VERSION ""

NS_ :

BS_:

BU_: TPM_HS EPS_HS IPC_HS TestTool_HS EBCM_HS BCM_HS TCM_HS ECM_HS
VAL_TABLE_ vt_BooleanValues 1 "true" 0 "false" ;

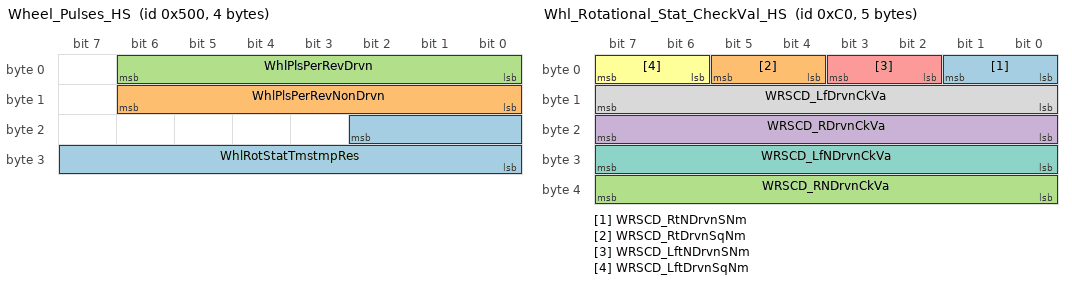
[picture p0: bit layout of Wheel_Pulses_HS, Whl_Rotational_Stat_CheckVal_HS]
BO_ 1280 Wheel_Pulses_HS: 4 EBCM_HS
 SG_ WhlRotStatTmstmpRes : 18|11@0+ (0.002,0) [0|4.094] "uSec"  EPS_HS
 SG_ WhlPlsPerRevNonDrvn : 14|7@0+ (1,0) [0|127] ""  EPS_HS
 SG_ WhlPlsPerRevDrvn : 6|7@0+ (1,0) [0|127] ""  EPS_HS

BO_ 192 Whl_Rotational_Stat_CheckVal_HS: 5 EBCM_HS
 SG_ WRSCD_RtNDrvnSNm : 1|2@0+ (1,0) [0|3] ""  EPS_HS
 SG_ WRSCD_RtDrvnSqNm : 5|2@0+ (1,0) [0|2] ""  EPS_HS
 SG_ WRSCD_RNDrvnCkVa : 39|8@0+ (1,0) [0|255] ""  EPS_HS
 SG_ WRSCD_RDrvnCkVa : 23|8@0+ (1,0) [0|255] ""  EPS_HS
 SG_ WRSCD_LftNDrvnSNm : 3|2@0+ (1,0) [0|3] ""  EPS_HS
 SG_ WRSCD_LftDrvnSqNm : 7|2@0+ (1,0) [0|3] ""  EPS_HS
 SG_ WRSCD_LfNDrvnCkVa : 31|8@0+ (1,0) [0|255] ""  EPS_HS
 SG_ WRSCD_LfDrvnCkVa : 15|8@0+ (1,0) [0|255] ""  EPS_HS

BO_ 546 Chime_Request: 1 TPM_HS
 SG_ ChmNum : 6|3@0- (1,0) [0|1] ""  BCM_HS
 SG_ ChmReq : 7|1@0+ (1,0) [0|1] ""  BCM_HS

BO_ 494 Tire_Pressure_Sensor_Prog_Res_HS: 1 TPM_HS
 SG_ TPMTrLrnMdCmplt : 1|2@0+ (1,0) [0|0] ""  IPC_HS

BO_ 591 USDT_Req_to_TPM_HS: 8 TestTool_HS
 SG_ DgnInf : 7|64@0+ (1,0) [0|1.844674407371E+019] ""  TPM_HS

BO_ 1615 USDT_Resp_From_TPM_HS: 8 TPM_HS
 SG_ DgnInf : 7|64@0+ (1,0) [0|1.8446744074E+019] ""  TestTool_HS

BO_ 1359 UUDT_Resp_From_TPM_HS: 8 TPM_HS
 SG_ DgnInf_HS54F : 7|64@0+ (1,0) [0|1.8446744074E+019] ""  TestTool_HS

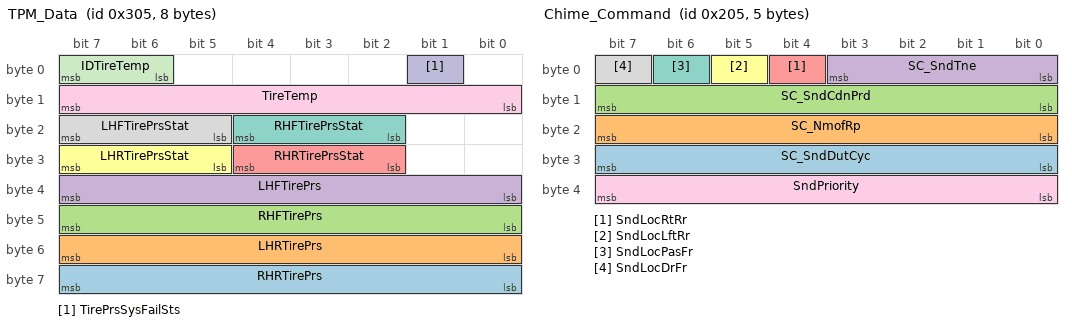
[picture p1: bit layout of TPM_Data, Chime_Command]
BO_ 773 TPM_Data: 8 TPM_HS
 SG_ RHRTirePrs : 63|8@0+ (0.0138,0) [0|3.5] "bar"  IPC_HS
 SG_ LHRTirePrs : 55|8@0+ (0.0138,0) [0|3.5] "bar"  IPC_HS
 SG_ RHFTirePrs : 47|8@0+ (0.0138,0) [0|3.5] "bar"  IPC_HS
 SG_ LHFTirePrs : 39|8@0+ (0.0138,0) [0|3.5] "bar" Vector__XXX
 SG_ RHRTirePrsStat : 28|3@0+ (1,0) [0|0] ""  IPC_HS
 SG_ LHRTirePrsStat : 31|3@0+ (1,0) [0|0] ""  IPC_HS
 SG_ RHFTirePrsStat : 20|3@0+ (1,0) [0|0] ""  IPC_HS
 SG_ LHFTirePrsStat : 23|3@0+ (1,0) [0|0] ""  IPC_HS
 SG_ TireTemp : 15|8@0+ (0.65,-40) [-40|125] "deg C"  IPC_HS
 SG_ TirePrsSysFailSts : 1|1@0+ (1,0) [0|0] ""  IPC_HS
 SG_ IDTireTemp : 7|2@0+ (1,0) [0|0] ""  IPC_HS

BO_ 1284 TPM_ID_Study_ACK: 1 TPM_HS
 SG_ IDStudyACK : 7|1@0+ (1,0) [0|1] ""  IPC_HS

BO_ 1283 TPM_ID_Study_Request: 1 IPC_HS
 SG_ IDStudyReq : 7|1@0+ (1,0) [0|1] ""  TPM_HS

BO_ 519 IPC_Chime_Request: 8 IPC_HS
 SG_ DrvSelOvSpdWarnActConf : 1|1@0+ (1,0) [0|1] ""  BCM_HS
 SG_ OvSpdChmReq : 0|1@0+ (1,0) [0|1] ""  BCM_HS

BO_ 533 IPC_General_Status_1: 1 IPC_HS
 SG_ DrvSelOvSpdEnbl : 1|1@0+ (1,0) [0|1] ""  BCM_HS
 SG_ OvSpdSta : 0|1@0+ (1,0) [0|1] ""  BCM_HS

BO_ 328 Power_Steering_Information_HS: 1 EPS_HS
 SG_ StrngAsstRdcdIO : 1|1@0- (1,0) [0|1] ""  IPC_HS
 SG_ PwrStrIO : 0|1@0+ (1,0) [0|1] ""  IPC_HS

BO_ 1346 UUDT_Resp_From_EPS_HS: 8 EPS_HS
 SG_ DgnInf : 7|64@0+ (1,0) [0|1.8446744074E+019] ""  TestTool_HS

BO_ 1602 USDT_Resp_From_EPS_HS: 8 EPS_HS
 SG_ DgnInf : 7|64@0+ (1,0) [0|1.8446744074E+019] ""  TestTool_HS

BO_ 578 USDT_Req_From_EPS_HS: 8 TestTool_HS
 SG_ DgnInf : 7|64@0+ (1,0) [0|1.8446744074E+019] ""  EPS_HS

BO_ 528 Chime_Active: 1 IPC_HS
 SG_ ChmVolSt : 2|2@0+ (1,0) [0|0] ""  BCM_HS
 SG_ ChmAct : 0|1@0+ (1,0) [0|1] ""  BCM_HS

BO_ 517 Chime_Command: 5 BCM_HS
 SG_ SC_SndDutCyc : 31|8@0+ (0.392157,0) [0|100.000035] "%"  IPC_HS
 SG_ SC_NmofRp : 23|8@0+ (1,0) [0|255] "reps"  IPC_HS
 SG_ SC_SndCdnPrd : 15|8@0+ (1,0) [0|2550] "ms"  IPC_HS
 SG_ SC_SndTne : 3|4@0+ (1,0) [0|15] ""  IPC_HS
 SG_ SndLocRtRr : 4|1@0+ (1,0) [0|1] ""  IPC_HS
 SG_ SndLocLftRr : 5|1@0+ (1,0) [0|1] ""  IPC_HS
 SG_ SndLocPasFr : 6|1@0+ (1,0) [0|1] ""  IPC_HS
 SG_ SndLocDrFr : 7|1@0+ (1,0) [0|1] ""  IPC_HS
 SG_ SndPriority : 39|8@0+ (1,0) [0|255] ""  IPC_HS

BO_ 1612 USDT_Resp_From_IPC_HS: 8 IPC_HS
 SG_ DgnInf : 7|64@0+ (1,0) [0|1.8446744074E+019] ""  TestTool_HS

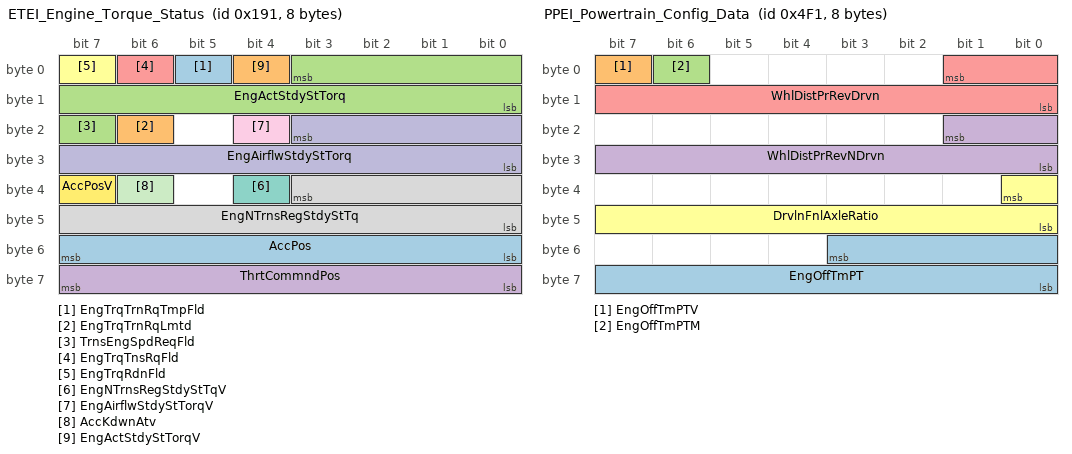
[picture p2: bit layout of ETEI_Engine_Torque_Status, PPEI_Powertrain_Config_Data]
BO_ 401 ETEI_Engine_Torque_Status: 8 ECM_HS
 SG_ EngTrqTrnRqTmpFld : 5|1@0+ (1,0) [0|1] ""  TCM_HS
 SG_ EngTrqTrnRqLmtd : 22|1@0+ (1,0) [0|1] ""  TCM_HS
 SG_ TrnsEngSpdReqFld : 23|1@0+ (1,0) [0|1] ""  TCM_HS
 SG_ ThrtCommndPos : 63|8@0+ (0.392157,0) [0|100.000035] "%"  TCM_HS
 SG_ EngTrqTnsRqFld : 6|1@0+ (1,0) [0|1] ""  TCM_HS
 SG_ EngTrqRdnFld : 7|1@0+ (1,0) [0|1] ""  TCM_HS
 SG_ EngNTrnsRegStdyStTqV : 36|1@0+ (1,0) [0|1] ""  TCM_HS
 SG_ EngNTrnsRegStdyStTq : 35|12@0+ (0.5,-848) [-848|1199.5] "Nm"  TCM_HS
 SG_ EngAirflwStdyStTorqV : 20|1@0+ (1,0) [0|1] ""  TCM_HS
 SG_ EngAirflwStdyStTorq : 19|12@0+ (0.5,-848) [-848|1199.5] "Nm"  TCM_HS
 SG_ AccKdwnAtv : 38|1@0+ (1,0) [0|1] ""  TCM_HS
 SG_ AccPosV : 39|1@0+ (1,0) [0|1] ""  TCM_HS
 SG_ AccPos : 55|8@0+ (0.392157,0) [0|100.000035] "%"  TCM_HS
 SG_ EngActStdyStTorqV : 4|1@0+ (1,0) [0|1] ""  TCM_HS
 SG_ EngActStdyStTorq : 3|12@0+ (0.5,-848) [-848|1199.5] "Nm"  TCM_HS

BO_ 1265 PPEI_Powertrain_Config_Data: 8 ECM_HS
 SG_ EngOffTmPT : 51|12@0+ (0.5,0) [0|2047.5] "min"  TCM_HS
 SG_ EngOffTmPTV : 7|1@0+ (1,0) [0|1] ""  TCM_HS
 SG_ EngOffTmPTM : 6|1@0+ (1,0) [0|1] ""  TCM_HS
 SG_ WhlDistPrRevNDrvn : 17|10@0+ (3,800) [800|3869] "mm"  EPS_HS,EBCM_HS
 SG_ WhlDistPrRevDrvn : 1|10@0+ (3,800) [800|3869] "mm"  EPS_HS,EBCM_HS,BCM_HS
 SG_ DrvlnFnlAxleRatio : 32|9@0+ (0.01,2) [2|7.11] ""  BCM_HS,EBCM_HS

BO_ 417 ETEI_Engine_General_Status: 7 ECM_HS
 SG_ EngRunng : 30|1@0+ (1,0) [0|1] "" Vector__XXX
 SG_ EngCrsCntrlMode : 29|3@0+ (1,0) [0|7] ""  TCM_HS
 SG_ EngPstOxgSnsDgAstRq : 31|1@0+ (1,0) [0|1] ""  TCM_HS
 SG_ CrsCtrlCnstSpdAct : 26|1@0+ (1,0) [0|1] ""  TCM_HS
 SG_ WrmUpShftPtrnRq : 25|1@0+ (1,0) [0|1] ""  TCM_HS
 SG_ EngIdlSpdRdcdRng : 39|8@0+ (8,0) [0|2040] "rpm"  TCM_HS
 SG_ EngCntrlRunCrnkTrmSt : 16|1@0+ (1,0) [0|1] ""  EBCM_HS,TCM_HS
 SG_ EngAlwCltAdp : 24|1@0+ (1,0) [0|1] ""  TCM_HS
 SG_ BsTrgtEngIdlSpd : 47|8@0+ (8,0) [0|2040] "rpm"  TCM_HS
 SG_ AccPdlPosPcntFullRngV : 17|1@0+ (1,0) [0|1] ""  TCM_HS
 SG_ AccPdlPosPcntFullRng : 55|8@0+ (0.392157,0) [0|100.000035] "%"  TCM_HS
 SG_ DslPrtFltrIdlRgtnMdReq : 20|1@0+ (1,0) [0|1] ""  TCM_HS
 SG_ DslPartFltrClngAlgActM : 18|1@0+ (1,0) [0|1] ""  TCM_HS
 SG_ DslPartFltrClngAlgAct : 19|1@0+ (1,0) [0|1] ""  TCM_HS
 SG_ EngCylDeactMd : 9|2@0+ (1,0) [0|3] "" Vector__XXX
 SG_ ACCmCltEngd : 13|1@0+ (1,0) [0|1] ""  TCM_HS
 SG_ ParkNeutralSwStatV : 21|1@0+ (1,0) [0|1] ""  TCM_HS
 SG_ ParkNeutralSwStat : 22|1@0+ (1,0) [0|1] ""  TCM_HS
 SG_ EngColdHiIdleActive : 23|1@0+ (1,0) [0|1] ""  TCM_HS
 SG_ EngCyDactTqSmtAct : 6|1@0+ (1,0) [0|1] ""  TCM_HS
 SG_ EngBrkStat : 15|2@0+ (1,0) [0|3] ""  TCM_HS
 SG_ TracCntlSysPwrtrnInhbt : 12|1@0+ (1,0) [0|1] ""  TCM_HS
 SG_ EngMtlProtAtv : 11|1@0+ (1,0) [0|1] ""  TCM_HS
 SG_ EngDgTrqCnvClUnlkRqd : 7|1@0+ (1,0) [0|1] ""  TCM_HS
 SG_ EngCyldrDeactReqd : 10|1@0+ (1,0) [0|1] ""  TCM_HS
 SG_ ETGRReqdGear : 3|4@0+ (1,0) [0|15] ""  TCM_HS
 SG_ ETGRReqType : 5|2@0+ (1,0) [0|3] ""  TCM_HS

BO_ 1233 PPEI_Engine_General_Status_5: 8 ECM_HS
 SG_ EngShtdwnAct : 48|1@0+ (1,0) [0|1] "" Vector__XXX
 SG_ EngShtdwnPndgIO : 49|1@0+ (1,0) [0|1] ""  BCM_HS
 SG_ FuelFltChgNwIO : 51|1@0+ (1,0) [0|1] ""  BCM_HS
 SG_ PTExPrtclFltrWrn2IO : 50|1@0+ (1,0) [0|1] ""  BCM_HS
 SG_ PTHiElecLdReqd : 52|1@0+ (1,0) [0|1] ""  BCM_HS
 SG_ PTExPrtclFltrWrnIO : 53|1@0+ (1,0) [0|1] ""  BCM_HS
 SG_ AirCndOffIO : 0|1@0+ (1,0) [0|1] ""  IPC_HS,BCM_HS
 SG_ EngSpdMaxLmt : 63|8@0+ (32,0) [0|8160] "rpm"  BCM_HS
 SG_ DslGlwPlgIO : 55|1@0+ (1,0) [0|1] ""  BCM_HS
 SG_ StgDisIO : 30|1@0+ (1,0) [0|1] ""  IPC_HS,BCM_HS
 SG_ RdcdPwrIO : 31|1@0+ (1,0) [0|1] ""  IPC_HS,BCM_HS
 SG_ FuelTotCap : 27|12@0+ (0.125,0) [0|511.875] "liters"  IPC_HS,BCM_HS
 SG_ FlLvlPctV : 28|1@0+ (1,0) [0|1] ""  IPC_HS,BCM_HS
 SG_ FlLvlPct : 47|8@0+ (0.392157,0) [0|100.000035] "%"  IPC_HS,BCM_HS
 SG_ EngWtrInFlIO : 54|1@0+ (1,0) [0|1] ""  BCM_HS
 SG_ EngOilTmpV : 7|1@0+ (1,0) [0|1] ""  IPC_HS,BCM_HS
 SG_ EngOilTmp : 15|8@0+ (1,-40) [-40|215] "deg C"  IPC_HS,BCM_HS
 SG_ EngOilPrsV : 6|1@0+ (1,0) [0|1] ""  IPC_HS,BCM_HS
 SG_ EngOilPrsLwIO : 5|1@0+ (1,0) [0|1] ""  IPC_HS,BCM_HS
 SG_ EngOilPrs : 23|8@0+ (4,0) [0|1020] "kPa"  IPC_HS,BCM_HS
 SG_ EngOilLvlLwIO : 4|1@0+ (1,0) [0|1] ""  IPC_HS,BCM_HS
 SG_ EngOilChngIO : 3|1@0+ (1,0) [0|1] ""  IPC_HS,BCM_HS
 SG_ EngHt_StpEngIO : 1|1@0+ (1,0) [0|1] ""  IPC_HS,BCM_HS
 SG_ EngHotFuelEnrchmntIO : 2|1@0+ (1,0) [0|1] ""  IPC_HS,BCM_HS
 SG_ CkFlFilrCapIO : 29|1@0+ (1,0) [0|1] ""  BCM_HS

BO_ 1217 PPEI_Engine_General_Status_4: 8 ECM_HS
 SG_ LegPstDTCClrDrvCyCm : 40|1@0+ (1,0) [0|1] ""  TCM_HS
 SG_ LegDiagColdStCndMet : 47|1@0+ (1,0) [0|1] ""  TCM_HS
 SG_ LegDiagColdStCndFltPr : 46|1@0+ (1,0) [0|1] ""  TCM_HS
 SG_ EngEconMdCmnd : 44|1@0+ (1,0) [0|1] ""  TCM_HS
 SG_ EngOilHotIO : 45|1@0+ (1,0) [0|1] ""  BCM_HS
 SG_ DslExhFldWrngIndRq : 53|3@0+ (1,0) [0|7] ""  BCM_HS
 SG_ DslExhFldRmngDstV : 50|1@0+ (1,0) [0|1] ""  BCM_HS
 SG_ DslExhFldRmngDst : 49|10@0+ (100,0) [0|102300] "km"  BCM_HS
 SG_ OAT_PT_EstV : 3|1@0+ (1,0) [0|1] ""  BCM_HS
 SG_ LegDiagStndCndMet : 2|1@0+ (1,0) [0|1] ""  TCM_HS
 SG_ LegDiagStndCndFltPr : 1|1@0+ (1,0) [0|1] ""  TCM_HS
 SG_ OAT_PT_EstM : 4|1@0+ (1,0) [0|1] ""  BCM_HS
 SG_ OAT_PT_Est : 39|8@0+ (0.5,-40) [-40|87.5] "deg C"  BCM_HS
 SG_ EngWrmUpAch : 0|1@0+ (1,0) [0|1] ""  TCM_HS
 SG_ EngIntAirTmpV : 5|1@0+ (1,0) [0|1] ""  BCM_HS
 SG_ EngIntAirTmp : 31|8@0+ (1,-40) [-40|215] "deg C"  BCM_HS
 SG_ EngCltTmpV : 6|1@0+ (1,0) [0|1] ""  IPC_HS,BCM_HS
 SG_ EngCltTmp : 23|8@0+ (1,-40) [-40|215] "deg C"  IPC_HS,BCM_HS
 SG_ BarPrsAbsV : 7|1@0+ (1,0) [0|1] ""  BCM_HS
 SG_ BarPrsAbs : 15|8@0+ (0.5,0) [0|127.5] "kPa"  BCM_HS

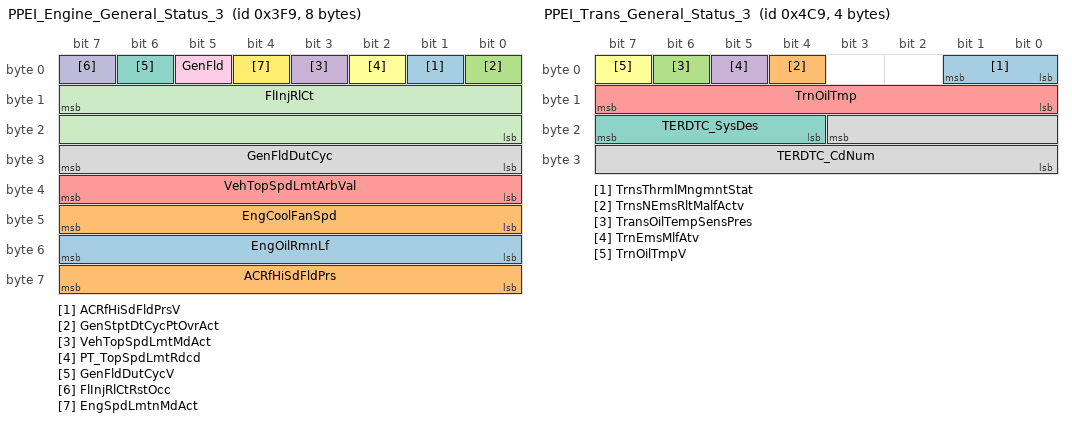
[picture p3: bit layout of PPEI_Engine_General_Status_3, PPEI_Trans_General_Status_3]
BO_ 1017 PPEI_Engine_General_Status_3: 8 ECM_HS
 SG_ ACRfHiSdFldPrsV : 1|1@0+ (1,0) [0|1] ""  BCM_HS
 SG_ ACRfHiSdFldPrs : 63|8@0+ (14,0) [0|3570] "kPaG"  BCM_HS
 SG_ GenStptDtCycPtOvrAct : 0|1@0+ (1,0) [0|1] ""  BCM_HS
 SG_ VehTopSpdLmtMdAct : 3|1@0+ (1,0) [0|1] ""  BCM_HS
 SG_ VehTopSpdLmtArbVal : 39|8@0+ (2,0) [0|510] "km / h"  BCM_HS
 SG_ PT_TopSpdLmtRdcd : 2|1@0+ (1,0) [0|1] ""  BCM_HS
 SG_ GenFldDutCycV : 6|1@0+ (1,0) [0|1] ""  BCM_HS
 SG_ GenFldDutCyc : 31|8@0+ (0.392157,0) [0|100.000035] "%"  BCM_HS
 SG_ GenFld : 5|1@0+ (1,0) [0|1] ""  IPC_HS,BCM_HS
 SG_ FlInjRlCtRstOcc : 7|1@0+ (1,0) [0|1] ""  BCM_HS
 SG_ FlInjRlCt : 15|16@0+ (3.05176E-005,0) [0|1.999970916] "liters"  BCM_HS
 SG_ EngSpdLmtnMdAct : 4|1@0+ (1,0) [0|1] ""  BCM_HS
 SG_ EngOilRmnLf : 55|8@0+ (0.392157,0) [0|100.000035] "%"  BCM_HS
 SG_ EngCoolFanSpd : 47|8@0+ (0.392157,0) [0|100.000035] "%"  BCM_HS

BO_ 977 PPEI_Engine_General_Status_2: 8 ECM_HS
 SG_ FuelFltLifRstPerf : 38|1@0+ (1,0) [0|1] ""  BCM_HS
 SG_ CrsCntlDrSelSpdAct : 39|1@0+ (1,0) [0|1] ""  BCM_HS
 SG_ ACCmpNrmLdGrdAld : 63|8@0+ (0.1,0) [0|25.5] "dm3/m/s"  BCM_HS
 SG_ ACCompCmnd : 37|1@0+ (1,0) [0|1] ""  BCM_HS
 SG_ EngBstPrsIndV : 23|1@0+ (1,0) [0|1] ""  BCM_HS
 SG_ EngBstPrsInd : 55|8@0+ (0.392157,0) [0|100.000035] "%"  BCM_HS
 SG_ EngOilLifRstPerf : 36|1@0+ (1,0) [0|1] ""  IPC_HS,BCM_HS
 SG_ ThrtlPrgrsnStat : 6|2@0+ (1,0) [0|3] ""  BCM_HS
 SG_ ThrPosV : 7|1@0+ (1,0) [0|1] ""  BCM_HS
 SG_ ThrPos : 15|8@0+ (0.392157,0) [0|100.000035] "%"  BCM_HS
 SG_ InstFuelConsmpRate : 35|12@0+ (0.025,0) [0|102.375] "ltrs/hr"  BCM_HS
 SG_ EngOilStrvtnIO : 21|1@0+ (1,0) [0|1] ""  BCM_HS
 SG_ EngNEmsnsRelMalfAct : 3|1@0+ (1,0) [0|1] ""  BCM_HS
 SG_ EngEmsRelMalfIndReq : 2|3@0+ (1,0) [0|7] ""  BCM_HS
 SG_ EngEmsMlfAtv : 4|1@0+ (1,0) [0|1] ""  BCM_HS
 SG_ EngCstFlCutAct : 22|1@0+ (1,0) [0|1] ""  BCM_HS
 SG_ AppBrkBfrCrsIO : 20|1@0+ (1,0) [0|1] ""  BCM_HS
 SG_ CrsSpdLmtrDrvSelSpd : 19|12@0+ (0.0625,0) [0|255.9375] "km / h"  TCM_HS,BCM_HS

BO_ 201 PPEI_Engine_General_Status_1: 8 ECM_HS
 SG_ EngAirIntBstPrV : 51|1@0+ (1,0) [0|1] ""  BCM_HS
 SG_ EngAirIntBstPr : 63|8@0- (1,0) [-128|127] "kPaG"  BCM_HS
 SG_ SpdLmtrSpdWrngEnbld : 47|1@0+ (1,0) [0|1] ""  BCM_HS
 SG_ SpdLmtrSpdWrngAct : 46|1@0+ (1,0) [0|1] ""  BCM_HS
 SG_ EngCylDactEvntPndg : 54|1@0+ (1,0) [0|1] "" Vector__XXX
 SG_ EngCylDeactMd : 43|2@0+ (1,0) [0|3] ""  BCM_HS
 SG_ RmVhStrtEngRng : 55|1@0+ (1,0) [0|1] ""  BCM_HS
 SG_ PFEngSpdCmndSpcd : 45|1@0+ (1,0) [0|1] ""  BCM_HS
 SG_ DrThrtlOvrrdDetProtVal : 25|2@0+ (1,0) [0|3] ""  EBCM_HS
 SG_ DrThrtlOvrdDetAlvRlCnt : 27|2@0+ (1,0) [0|3] ""  EBCM_HS
 SG_ PltfrmEngSpdCmdInhtRq : 44|1@0+ (1,0) [0|1] ""  BCM_HS
 SG_ PT_BrkPedDscrtInpStatV : 41|1@0+ (1,0) [0|1] ""  EBCM_HS
 SG_ PT_BrkPedDscrtInpStat : 40|1@0+ (1,0) [0|1] ""  EBCM_HS
 SG_ AccActPos : 39|8@0+ (0.392157,0) [0|100.000035] "%"  EBCM_HS,BCM_HS,TCM_HS
 SG_ CrsCntEnbld : 29|1@0+ (1,0) [0|1] ""  BCM_HS
 SG_ CrsCntAtv : 30|1@0+ (1,0) [0|1] ""  IPC_HS,EBCM_HS,BCM_HS,TCM_HS
 SG_ DrvThrottlOvrrdDet : 28|1@0+ (1,0) [0|1] ""  EBCM_HS,BCM_HS
 SG_ PT_CrnkAct : 6|1@0+ (1,0) [0|1] "" Vector__XXX
 SG_ PTRunAbrt : 4|1@0+ (1,0) [0|1] ""  BCM_HS
 SG_ PTO_PT_RunAbrtd : 3|1@0+ (1,0) [0|1] ""  BCM_HS
 SG_ PTCrnkAbrted : 5|1@0+ (1,0) [0|1] ""  BCM_HS
 SG_ EngSpdStat : 1|2@0+ (1,0) [0|3] ""  IPC_HS,EBCM_HS,BCM_HS
 SG_ EngSpd : 15|16@0+ (0.25,0) [0|16383.75] "rpm"  IPC_HS,EBCM_HS,BCM_HS
 SG_ EngRunAtv : 7|1@0+ (1,0) [0|1] ""  EPS_HS,IPC_HS,EBCM_HS,BCM_HS
 SG_ EngIdlAtv : 2|1@0+ (1,0) [0|1] ""  IPC_HS,BCM_HS
 SG_ AccActPosV : 31|1@0+ (1,0) [0|1] ""  EBCM_HS,BCM_HS,TCM_HS

BO_ 501 PPEI_Trans_General_Status_2: 8 ECM_HS
 SG_ EngRecDwnshftIO : 54|1@0+ (1,0) [0|1] ""  BCM_HS
 SG_ TrnsPattSelEcnMdOCm : 52|1@0+ (1,0) [0|1] ""  ECM_HS
 SG_ TransShftDlyd : 45|1@0+ (1,0) [0|1] ""  BCM_HS
 SG_ CltStartSwAtvV : 38|1@0+ (1,0) [0|0] ""  BCM_HS
 SG_ CltStartSwAtv : 37|1@0+ (1,0) [0|1] ""  BCM_HS
 SG_ CltchPdlActPosV : 55|1@0+ (1,0) [0|1] ""  ECM_HS
 SG_ CltchPdlActPos : 63|8@0+ (0.392157,0) [0|100.000035] "%"  ECM_HS
 SG_ TrnsEngdStateV : 50|1@0+ (1,0) [0|1] ""  IPC_HS,BCM_HS
 SG_ TrnsEngdState : 49|2@0+ (1,0) [0|3] ""  IPC_HS,BCM_HS
 SG_ TransTUDMdStat : 41|2@0+ (1,0) [0|3] ""  IPC_HS,BCM_HS,ECM_HS
 SG_ TrnCrpMdAtv : 46|1@0+ (1,0) [0|1] ""  ECM_HS,BCM_HS
 SG_ TrnsShftLvrLckRqd : 47|1@0+ (1,0) [0|1] "" Vector__XXX
 SG_ TrnsSkpShftIO : 23|1@0+ (1,0) [0|1] ""  BCM_HS
 SG_ TrnsSftMdStat : 34|3@0+ (1,0) [0|7] ""  BCM_HS
 SG_ TrnsRngInhbtStat : 31|3@0+ (1,0) [0|7] ""  BCM_HS
 SG_ TopTrvlCltchSwActV : 15|1@0+ (1,0) [0|1] ""  BCM_HS
 SG_ TopTrvlCltchSwAct : 14|1@0+ (1,0) [0|1] ""  BCM_HS
 SG_ OvrdrvDsblReqGrntd : 39|1@0+ (1,0) [0|1] ""  BCM_HS
 SG_ EngRecmndUpshftIO : 22|1@0+ (1,0) [0|1] ""  BCM_HS
 SG_ DrvtShftCntrlTrgtGear : 19|4@0+ (1,0) [0|15] ""  IPC_HS,BCM_HS
 SG_ DrShftCntrlReqDndIO : 21|1@0+ (1,0) [0|1] ""  IPC_HS,BCM_HS
 SG_ TrnShftPtrnActStat : 44|3@0+ (1,0) [0|7] ""  EPS_HS,IPC_HS,BCM_HS
 SG_ TrnsFldPrsPrsnt : 51|1@0+ (1,0) [0|1] ""  ECM_HS
 SG_ TrnsShftLvrPos : 27|4@0+ (1,0) [0|15] ""  IPC_HS,BCM_HS,ECM_HS
 SG_ TrnsShftLvrPosV : 28|1@0+ (1,0) [0|1] ""  IPC_HS,BCM_HS,ECM_HS
 SG_ TrnsTrqCnvCltCmndMd : 7|3@0+ (1,0) [0|7] ""  ECM_HS
 SG_ AutoTransComndGear : 11|4@0+ (1,0) [0|15] ""  BCM_HS,ECM_HS
 SG_ AutoTransGrSftDirect : 13|2@0+ (1,0) [0|3] ""  ECM_HS
 SG_ TransEstGear : 3|4@0+ (1,0) [0|15] ""  IPC_HS,EPS_HS,BCM_HS,ECM_HS
 SG_ TransEstGearV : 4|1@0+ (1,0) [0|1] ""  IPC_HS,EPS_HS,BCM_HS,ECM_HS

BO_ 1225 PPEI_Trans_General_Status_3: 4 ECM_HS
 SG_ TrnsThrmlMngmntStat : 1|2@0+ (1,0) [0|3] ""  BCM_HS
 SG_ TrnsNEmsRltMalfActv : 4|1@0+ (1,0) [0|1] ""  BCM_HS
 SG_ TransOilTempSensPres : 6|1@0+ (1,0) [0|1] ""  BCM_HS
 SG_ TrnEmsMlfAtv : 5|1@0+ (1,0) [0|1] ""  BCM_HS,ECM_HS
 SG_ TrnOilTmp : 15|8@0+ (1,-40) [-40|215] "deg C"  BCM_HS,ECM_HS
 SG_ TrnOilTmpV : 7|1@0+ (1,0) [0|1] ""  BCM_HS,ECM_HS
 SG_ TERDTC_SysDes : 23|4@0+ (1,0) [0|15] ""  ECM_HS
 SG_ TERDTC_CdNum : 19|12@0+ (1,0) [0|4095] ""  ECM_HS

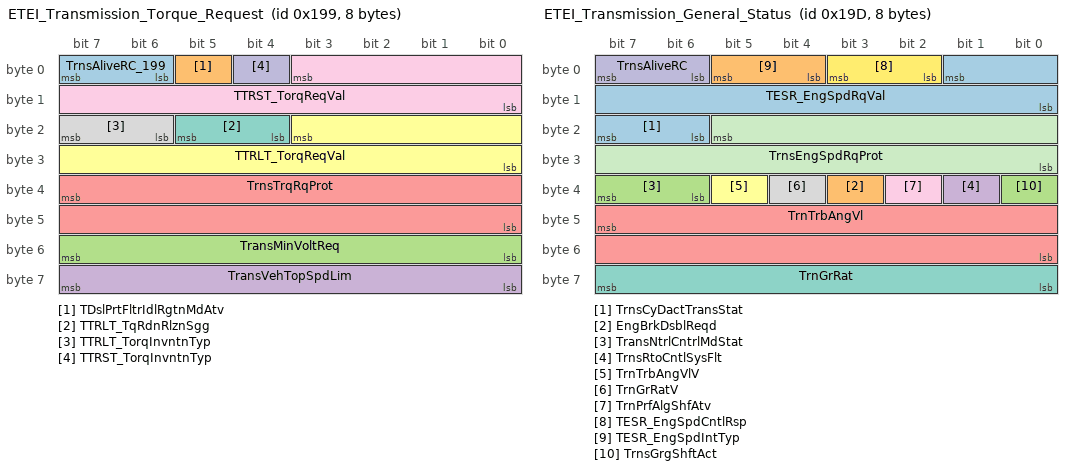
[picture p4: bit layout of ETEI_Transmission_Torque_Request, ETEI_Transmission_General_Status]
BO_ 409 ETEI_Transmission_Torque_Request: 8 TCM_HS
 SG_ TrnsAliveRC_199 : 7|2@0+ (1,0) [0|3] ""  ECM_HS
 SG_ TDslPrtFltrIdlRgtnMdAtv : 5|1@0+ (1,0) [0|1] ""  ECM_HS
 SG_ TransMinVoltReq : 55|8@0+ (0.07843,0) [0|19.99965] "volts"  ECM_HS
 SG_ TransVehTopSpdLim : 63|8@0+ (2,0) [0|510] "km / h"  ECM_HS
 SG_ TrnsTrqRqProt : 39|16@0+ (1,0) [0|65535] ""  ECM_HS
 SG_ TTRLT_TorqReqVal : 19|12@0+ (0.5,-848) [-848|1199.5] "Nm"  ECM_HS
 SG_ TTRLT_TqRdnRlznSgg : 21|2@0+ (1,0) [0|3] ""  ECM_HS
 SG_ TTRLT_TorqInvntnTyp : 23|2@0+ (1,0) [0|3] ""  ECM_HS
 SG_ TTRST_TorqReqVal : 3|12@0+ (0.5,-848) [-848|1199.5] "Nm"  ECM_HS
 SG_ TTRST_TorqInvntnTyp : 4|1@0+ (1,0) [0|1] ""  ECM_HS

BO_ 413 ETEI_Transmission_General_Status: 8 TCM_HS
 SG_ TrnsCyDactTransStat : 23|2@0+ (1,0) [0|3] ""  ECM_HS
 SG_ EngBrkDsblReqd : 35|1@0+ (1,0) [0|1] ""  ECM_HS
 SG_ TransNtrlCntrlMdStat : 39|2@0+ (1,0) [0|3] ""  BCM_HS,ECM_HS
 SG_ TrnsRtoCntlSysFlt : 33|1@0+ (1,0) [0|1] ""  ECM_HS
 SG_ TrnTrbAngVl : 47|16@0+ (0.25,0) [0|16383.75] "rpm"  ECM_HS
 SG_ TrnTrbAngVlV : 37|1@0+ (1,0) [0|1] ""  ECM_HS
 SG_ TrnGrRat : 63|8@0+ (0.03125,0) [0|7.96875] ""  ECM_HS
 SG_ TrnGrRatV : 36|1@0+ (1,0) [0|1] ""  ECM_HS
 SG_ TrnPrfAlgShfAtv : 34|1@0+ (1,0) [0|1] ""  ECM_HS
 SG_ TrnsAliveRC : 7|2@0+ (1,0) [0|3] ""  ECM_HS
 SG_ TrnsEngSpdRqProt : 21|14@0+ (1,0) [0|16383] ""  ECM_HS
 SG_ TESR_EngSpdCntlRsp : 3|2@0+ (1,0) [0|3] ""  ECM_HS
 SG_ TESR_EngSpdRqVal : 1|10@0+ (8,0) [0|8184] "rpm"  ECM_HS
 SG_ TESR_EngSpdIntTyp : 5|2@0+ (1,0) [0|3] ""  ECM_HS
 SG_ TrnsGrgShftAct : 32|1@0+ (1,0) [0|1] ""  ECM_HS

BO_ 257 USDT_Req_to_All_HS_ECUs: 8 TestTool_HS
 SG_ DgnInf : 7|64@0+ (1,0) [0|1.8446744074E+019] ""  TPM_HS,EPS_HS,IPC_HS,EBCM_HS,BCM_HS,TCM_HS,ECM_HS

BO_ 2016 USDT_Req_to_ECM_HS: 8 TestTool_HS
 SG_ DgnInf : 7|64@0+ (1,0) [0|1.8446744074E+019] ""  ECM_HS

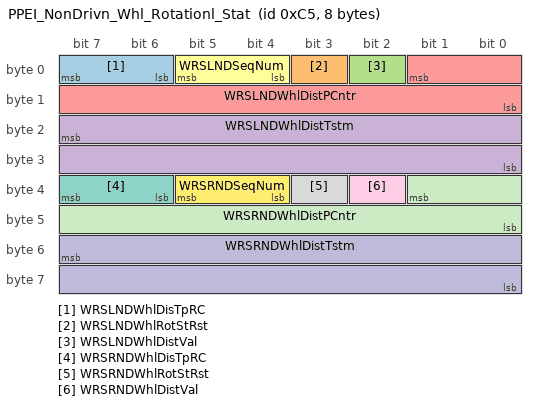
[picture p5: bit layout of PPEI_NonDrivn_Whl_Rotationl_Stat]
BO_ 197 PPEI_NonDrivn_Whl_Rotationl_Stat: 8 EBCM_HS
 SG_ WRSLNDWhlDisTpRC : 7|2@0+ (1,0) [0|3] "counts"  EPS_HS,BCM_HS,TCM_HS,ECM_HS
 SG_ WRSLNDWhlRotStRst : 3|1@0+ (1,0) [0|1] ""  EPS_HS,BCM_HS,TCM_HS,ECM_HS
 SG_ WRSLNDWhlDistVal : 2|1@0+ (1,0) [0|1] ""  EPS_HS,BCM_HS,TCM_HS,ECM_HS
 SG_ WRSLNDWhlDistTstm : 23|16@0+ (1,0) [0|65535] "counts"  EPS_HS,BCM_HS,TCM_HS,ECM_HS
 SG_ WRSLNDWhlDistPCntr : 1|10@0+ (1,0) [0|1023] "counts"  EPS_HS,BCM_HS,TCM_HS,ECM_HS
 SG_ WRSLNDSeqNum : 5|2@0+ (1,0) [0|3] "counts"  EPS_HS,BCM_HS,TCM_HS,ECM_HS
 SG_ WRSRNDWhlDisTpRC : 39|2@0+ (1,0) [0|3] "counts"  EPS_HS,BCM_HS,TCM_HS,ECM_HS
 SG_ WRSRNDWhlRotStRst : 35|1@0+ (1,0) [0|1] ""  EPS_HS,BCM_HS,TCM_HS,ECM_HS
 SG_ WRSRNDWhlDistVal : 34|1@0+ (1,0) [0|1] ""  EPS_HS,BCM_HS,TCM_HS,ECM_HS
 SG_ WRSRNDWhlDistTstm : 55|16@0+ (1,0) [0|65535] "counts"  EPS_HS,BCM_HS,TCM_HS,ECM_HS
 SG_ WRSRNDWhlDistPCntr : 33|10@0+ (1,0) [0|1023] "counts"  EPS_HS,BCM_HS,TCM_HS,ECM_HS
 SG_ WRSRNDSeqNum : 37|2@0+ (1,0) [0|3] "counts"  EPS_HS,BCM_HS,TCM_HS,ECM_HS

BO_TX_BU_ 501 : TCM_HS,ECM_HS;
BO_TX_BU_ 1225 : TCM_HS,ECM_HS;

CM_ "Primary High Speed GMLAN";
CM_ BU_ TPM_HS "Tire Pressure Module";
CM_ BU_ EPS_HS "Electrical Power Streering";
CM_ BU_ IPC_HS "IP cluster";
CM_ BU_ EBCM_HS "Electronic Brake Control Module";
CM_ BU_ BCM_HS "HS Side Global Architecture Gateway and Body Control Module";
CM_ BU_ TCM_HS "Transmission Control Module";
CM_ BU_ ECM_HS "Engine Control Module";
CM_ BO_ 533 "Created for SGM818 LSD function";
CM_ SG_ 401 EngTrqTnsRqFld "Indicates that the Engine controller will not honor the torque request from the Transmission Controller due to a failure in the Rolling count, protection value, etc.";
CM_ SG_ 401 EngNTrnsRegStdyStTqV "ETEI 3.1";
CM_ SG_ 401 EngNTrnsRegStdyStTq "ETEI 3.1";
CM_ SG_ 401 EngAirflwStdyStTorqV "ETEI 3.1";
CM_ SG_ 401 EngAirflwStdyStTorq "ETEI 3.1";
CM_ SG_ 401 EngActStdyStTorqV "ETEI 3.1";
CM_ SG_ 401 EngActStdyStTorq "ETEI 3.1";
CM_ SG_ 417 TracCntlSysPwrtrnInhbt "ETEI 3.1";
CM_ SG_ 977 ACCmpNrmLdGrdAld "dm3/m/s = dm3/minute/second";
CM_ SG_ 977 ThrtlPrgrsnStat "ECM = Engine Control Module";
CM_ BO_ 201 "Changed for PPEI 3.6";
CM_ SG_ 201 EngRunAtv "Indication from powertrain that the engine is running (Has RPM > 0)";
CM_ SG_ 501 TrnShftPtrnActStat "(PT = Powertrain)";
BA_DEF_  "BusType" STRING ;
BA_DEF_ SG_  "VNSigSLHS_VNReq" ENUM  "No","Yes";
BA_DEF_ SG_  "VNSigSLHSSharedDiagnostic" ENUM  "No","Yes";
BA_DEF_ SG_  "SignalType" STRING ;
BA_DEF_ SG_  "PacketOrder" INT 0 65535;
BA_DEF_ SG_  "SignalLongName" STRING ;
BA_DEF_ SG_  "GenSigStartValue" INT 0 65535;
BA_DEF_ SG_  "VNSigAllNodes" ENUM  "No","Yes";
BA_DEF_ SG_  "GenSigDeltaValue" INT 0 0;
BA_DEF_ SG_  "GenSigSendType_signal" ENUM  "not used","not used","not used","not used","not used","not used","not used","NoSigSendType","not used","not used","OnAnyChange","OnChangeIfActive","OnDelta";
BA_DEF_ SG_  "GenSigSendOnInit_signal" ENUM  "Not Initialized","Application","Handler";
BA_DEF_ SG_  "GenSigSendType" ENUM  "not used","not used","not used","not used","not used","not used","not used","NoSigSendType","not used","not used","OnAnyChange","OnChangeIfActive","OnDelta";
BA_DEF_ SG_  "GenSigSendOnInit" ENUM  "Not Initialized","Application","Handler";
BA_DEF_ BO_  "GenMsgILSupport" ENUM  "No","Yes";
BA_DEF_ BO_  "TpApplType" STRING ;
BA_DEF_ BO_  "Prio" INT 0 7;
BA_DEF_ BO_  "MessageSubnet" ENUM  "LS","MS","HS","CE","PE","CC";
BA_DEF_ BO_  "DiagState" ENUM  "No","Yes";
BA_DEF_ BO_  "GenMsgDelayTime" INT 0 100000;
BA_DEF_ BO_  "GenMsgCycleTime" INT 0 100000;
BA_DEF_ BO_  "GenMsgSendType" ENUM  "cyclicX","spontanX","cyclicIfActiveX","spontanWithDelay","cyclicAndSpontanX","cyclicAndSpontanWithDelay","spontanWithRepitition","cyclicIfActiveAndSpontanWD";
BA_DEF_ BO_  "DiagResponse" ENUM  "No","Yes";
BA_DEF_ BO_  "DiagRequest" ENUM  "No","Yes";
BA_DEF_ BO_  "NmMessage" ENUM  "No","Yes";
BA_DEF_ BU_  "NmNode" ENUM  "No","Yes";
BA_DEF_ BU_  "ILUsed" ENUM  "No","Yes";
BA_DEF_ BU_  "NodeLayerModules" STRING ;
BA_DEF_ BU_  "D22_FRdDataByPID" ENUM  "No","Yes";
BA_DEF_ BU_  "D22_ReqType" ENUM  "Functional","Physical","Both";
BA_DEF_ BU_  "D2D_ReqType" ENUM  "Functional","Physical","Both";
BA_DEF_ BU_  "DAE_ReqType" ENUM  "Functional","Physical","Both";
BA_DEF_ BU_  "DAE_NE3" ENUM  "No","Yes";
BA_DEF_ BU_  "DAE_N78" ENUM  "No","Yes";
BA_DEF_ BU_  "DAE_N31" ENUM  "No","Yes";
BA_DEF_ BU_  "DAE_N12" ENUM  "No","Yes";
BA_DEF_ BU_  "DAE_FDevCtrl" ENUM  "No","Yes","vector_leerstring";
BA_DEF_ BU_  "DAA_ReqType" ENUM  "Functional","Physical","Both";
BA_DEF_ BU_  "DAA_N81" ENUM  "No","Yes";
BA_DEF_ BU_  "DAA_N78" ENUM  "No","Yes";
BA_DEF_ BU_  "DAA_N31" ENUM  "No","Yes";
BA_DEF_ BU_  "DAA_N12" ENUM  "No","Yes";
BA_DEF_ BU_  "DAA_L04_FastRate" ENUM  "No","Yes";
BA_DEF_ BU_  "DAA_L03_MedRate" ENUM  "No","Yes";
BA_DEF_ BU_  "DAA_L02_SlowRate" ENUM  "No","Yes";
BA_DEF_ BU_  "DAA_L01_SndOneRsp" ENUM  "No","Yes";
BA_DEF_ BU_  "DAA_L00_StopSnd" ENUM  "No","Yes";
BA_DEF_ BU_  "DAA_FRdDPID" ENUM  "No","Yes","vector_leerstring";
BA_DEF_ BU_  "DA9_ReqType" ENUM  "Functional","Physical","Both";
BA_DEF_ BU_  "DA9_N78" ENUM  "No","Yes";
BA_DEF_ BU_  "DA9_N31" ENUM  "No","Yes";
BA_DEF_ BU_  "DA9_N12" ENUM  "No","Yes";
BA_DEF_ BU_  "DA9_L82_SndChgDTC" ENUM  "No","Yes";
BA_DEF_ BU_  "DA9_L81_RdStatDTCbyMsk" ENUM  "No","Yes";
BA_DEF_ BU_  "DA9_L80_RdStatDTCbyNum" ENUM  "No","Yes";
BA_DEF_ BU_  "DA9_FRdDiagInfo" ENUM  "No","Yes","vector_leerstring";
BA_DEF_ BU_  "DA5_ReqType" ENUM  "Functional","Physical","Both";
BA_DEF_ BU_  "DA5_N78" ENUM  "No","Yes";
BA_DEF_ BU_  "DA5_N22" ENUM  "No","Yes";
BA_DEF_ BU_  "DA5_N12" ENUM  "No","Yes";
BA_DEF_ BU_  "DA5_L03_EnabProgMode" ENUM  "No","Yes";
BA_DEF_ BU_  "DA5_L02_ReqProgModeHS" ENUM  "No","Yes";
BA_DEF_ BU_  "DA5_L01_ReqProgMode" ENUM  "No","Yes";
BA_DEF_ BU_  "DA5_FProgMode" ENUM  "No","Yes","vector_leerstring";
BA_DEF_ BU_  "DA2_ReqType" ENUM  "Functional","Physical","Both";
BA_DEF_ BU_  "DA2_N78" ENUM  "No","Yes";
BA_DEF_ BU_  "DA2_N12" ENUM  "No","Yes";
BA_DEF_ BU_  "DA2_FRptPrgStat" ENUM  "No","Yes","vector_leerstring";
BA_DEF_ BU_  "D3E_ReqType" ENUM  "Functional","Physical","Both";
BA_DEF_ BU_  "D3E_N12" ENUM  "No","Yes";
BA_DEF_ BU_  "D3E_FTstrPres" ENUM  "No","Yes","vector_leerstring";
BA_DEF_ BU_  "D3B_ReqType" ENUM  "Functional","Physical","Both";
BA_DEF_ BU_  "D3B_N78" ENUM  "No","Yes";
BA_DEF_ BU_  "D3B_N31" ENUM  "No","Yes";
BA_DEF_ BU_  "D3B_N22" ENUM  "No","Yes";
BA_DEF_ BU_  "D3B_N12" ENUM  "No","Yes";
BA_DEF_ BU_  "D3B_FWrtBlk" ENUM  "No","Yes","vector_leerstring";
BA_DEF_ BU_  "D36_ReqType" ENUM  "Functional","Physical","Both";
BA_DEF_ BU_  "D36_N89" ENUM  "No","Yes";
BA_DEF_ BU_  "D36_N85" ENUM  "No","Yes";
BA_DEF_ BU_  "D36_N83" ENUM  "No","Yes";
BA_DEF_ BU_  "D36_N78" ENUM  "No","Yes";
BA_DEF_ BU_  "D36_N31" ENUM  "No","Yes";
BA_DEF_ BU_  "D36_N22" ENUM  "No","Yes";
BA_DEF_ BU_  "D36_N12" ENUM  "No","Yes";
BA_DEF_ BU_  "D36_L80_DwnldExec" ENUM  "No","Yes";
BA_DEF_ BU_  "D36_L00_DownLoad" ENUM  "No","Yes";
BA_DEF_ BU_  "D36_FXfrData" ENUM  "No","Yes","vector_leerstring";
BA_DEF_ BU_  "D34_ReqType" ENUM  "Functional","Physical","Both";
BA_DEF_ BU_  "D34_N99" ENUM  "No","Yes";
BA_DEF_ BU_  "D34_N78" ENUM  "No","Yes";
BA_DEF_ BU_  "D34_N22" ENUM  "No","Yes";
BA_DEF_ BU_  "D34_N12" ENUM  "No","Yes";
BA_DEF_ BU_  "D34_FReqDwnld" ENUM  "No","Yes";
BA_DEF_ BU_  "D2C_ReqType" ENUM  "Functional","Physical","Both";
BA_DEF_ BU_  "D2C_N78" ENUM  "No","Yes";
BA_DEF_ BU_  "D2C_N31" ENUM  "No","Yes";
BA_DEF_ BU_  "D2C_N12" ENUM  "No","Yes";
BA_DEF_ BU_  "D2C_FDynMsg" ENUM  "No","Yes","vector_leerstring";
BA_DEF_ BU_  "D28_ReqType" ENUM  "Functional","Physical","Both";
BA_DEF_ BU_  "D28_N22" ENUM  "No","Yes";
BA_DEF_ BU_  "D28_N12" ENUM  "No","Yes";
BA_DEF_ BU_  "D28_FDisNormComm" ENUM  "No","Yes","vector_leerstring";
BA_DEF_ BU_  "D27_ReqType" ENUM  "Functional","Physical","Both";
BA_DEF_ BU_  "D27_N78" ENUM  "No","Yes";
BA_DEF_ BU_  "D27_N37" ENUM  "No","Yes";
BA_DEF_ BU_  "D27_N36" ENUM  "No","Yes";
BA_DEF_ BU_  "D27_N35" ENUM  "No","Yes";
BA_DEF_ BU_  "D27_N22" ENUM  "No","Yes";
BA_DEF_ BU_  "D27_N12" ENUM  "No","Yes";
BA_DEF_ BU_  "D27_L02_SndKey" ENUM  "No","Yes";
BA_DEF_ BU_  "D27_L01_ReqSeed" ENUM  "No","Yes";
BA_DEF_ BU_  "D27_FSecAcc" ENUM  "No","Yes","vector_leerstring";
BA_DEF_ BU_  "D23_ReqType" ENUM  "Functional","Physical","Both";
BA_DEF_ BU_  "D23_N78" ENUM  "No","Yes";
BA_DEF_ BU_  "D23_N31" ENUM  "No","Yes";
BA_DEF_ BU_  "D23_N12" ENUM  "No","Yes";
BA_DEF_ BU_  "D23_FRdMemAddr" ENUM  "No","Yes","vector_leerstring";
BA_DEF_ BU_  "D20_ReqType" ENUM  "Functional","Physical","Both";
BA_DEF_ BU_  "D20_N12" ENUM  "No","Yes";
BA_DEF_ BU_  "D20_FRtnNormComm" ENUM  "No","Yes","vector_leerstring";
BA_DEF_ BU_  "D1A_ReqType" ENUM  "Functional","Physical","Both";
BA_DEF_ BU_  "D1A_N78" ENUM  "No","Yes";
BA_DEF_ BU_  "D1A_N31" ENUM  "No","Yes";
BA_DEF_ BU_  "D1A_N22" ENUM  "No","Yes";
BA_DEF_ BU_  "D1A_N12" ENUM  "No","Yes";
BA_DEF_ BU_  "D1A_FRdDataID" ENUM  "No","Yes","vector_leerstring";
BA_DEF_ BU_  "D12_ReqType" ENUM  "Functional","Physical","Both";
BA_DEF_ BU_  "D12_N78" ENUM  "No","Yes";
BA_DEF_ BU_  "D12_N31" ENUM  "No","Yes";
BA_DEF_ BU_  "D12_N12" ENUM  "No","Yes";
BA_DEF_ BU_  "D12_L02_RdFRcdParam" ENUM  "No","Yes";
BA_DEF_ BU_  "D12_L01_RdFRcdData" ENUM  "No","Yes";
BA_DEF_ BU_  "D12_FRdFailRec" ENUM  "No","Yes","vector_leerstring";
BA_DEF_ BU_  "D10_ReqType" ENUM  "Functional","Physical ","Both";
BA_DEF_ BU_  "D10_N78" ENUM  "No","Yes";
BA_DEF_ BU_  "D10_N22" ENUM  "No","Yes";
BA_DEF_ BU_  "D10_N12" ENUM  "No","Yes";
BA_DEF_ BU_  "D10_L04_WakeUpLinks" ENUM  "No","Yes";
BA_DEF_ BU_  "D10_L03_DTCsDurDevCtrl" ENUM  "No","Yes";
BA_DEF_ BU_  "D10_L02_DisAllDTCs" ENUM  "No","Yes";
BA_DEF_ BU_  "D10_FInitDiagOp" ENUM  "No","Yes";
BA_DEF_ BU_  "D04_ReqType" ENUM  "Functional","Physical","Both";
BA_DEF_ BU_  "D04_N78" ENUM  "No","Yes";
BA_DEF_ BU_  "D04_N22" ENUM  "No","Yes";
BA_DEF_ BU_  "D04_N12" ENUM  "No","Yes";
BA_DEF_ BU_  "D04_FClrDTC" ENUM  "No","Yes";
BA_DEF_ BU_  "NmStationAddress" INT 0 31;
BA_DEF_ BU_  "ECU_Id_Node" HEX 0 255;
BA_DEF_ BU_  "SourceId_Node" HEX 0 253;
BA_DEF_ BU_  "VNECUSLHSSharedDiagnostic" ENUM  "None","Activator","Remoted","Activator and Remoted","Shared Local";
BA_DEF_ BU_  "VNECUSLHS_VNReq" ENUM  "None","Activator","Remoted","Activator and Remoted","Shared Local";
BA_DEF_ BU_  "VNECUAllNodes" ENUM  "None","Activator","Remoted","Activator and Remoted","Shared Local";
BA_DEF_ BU_  "SourceId" HEX 0 253;
BA_DEF_ BU_  "ECU_Id" HEX 0 255;
BA_DEF_  "SyncJumpWidthMax" INT 0 255;
BA_DEF_  "SyncJumpWidthMin" INT 0 255;
BA_DEF_  "SamplePointMax" FLOAT 0 100;
BA_DEF_  "SamplePointMin" FLOAT 0 100;
BA_DEF_  "Baudrate" INT 0 1000000;
BA_DEF_  "VehicleArchitecture" STRING ;
BA_DEF_  "VNInitActSLHS_VNReq" ENUM  "No","Yes";
BA_DEF_  "VN_SLHS_VNReq" INT 0 255;
BA_DEF_  "VNInitActSLHSSharedDiagnostic" ENUM  "No","Yes";
BA_DEF_  "VN_SLHSSharedDiagnostic" INT 0 255;
BA_DEF_  "VersionNumber" FLOAT 0 65535;
BA_DEF_  "NmMessageCount" INT 0 32;
BA_DEF_  "NmBaseAddress" HEX 0 2032;
BA_DEF_  "NetworkType" STRING ;
BA_DEF_  "VNMFPeriodicInterval" INT 0 65535;
BA_DEF_  "BusWakeUpDelay" INT 0 65535;
BA_DEF_  "BusOffRecoveryTime" INT 0 65535;
BA_DEF_  "NodeStatusMsgID" HEX 0 536870911;
BA_DEF_  "NodeStatusMsgCycleTime" INT 0 65535;
BA_DEF_  "NodeStatusMsgTimeoutTime" INT 0 65535;
BA_DEF_  "UseGMParameterIDs" INT 0 1;
BA_DEF_  "VersionWeek" INT 0 255;
BA_DEF_  "VersionYear" INT 0 255;
BA_DEF_  "VN_AllNodes" INT 0 255;
BA_DEF_  "Manufacturer" ENUM  "DBAG","VAG","BMW","PAG","GM";
BA_DEF_  "NmType" STRING ;
BA_DEF_REL_ BU_SG_REL_  "GenSigSuprvRespComment" STRING ;
BA_DEF_REL_ BU_SG_REL_  "GenSigVBitResp" ENUM  "No","Yes";
BA_DEF_REL_ BU_SG_REL_  "GenSigVBitRespComment" STRING ;
BA_DEF_REL_ BU_SG_REL_  "GenSigVDAFailComment" STRING ;
BA_DEF_REL_ BU_SG_REL_  "GenSigVDAFailResp" ENUM  "No","Yes";
BA_DEF_REL_ BU_SG_REL_  "GenSigRxStartValue" STRING ;
BA_DEF_REL_ BU_SG_REL_  "GenSigSuprvRespSubValue" INT 0 65535;
BA_DEF_REL_ BU_SG_REL_  "GenSigSuprvResp" ENUM  "None","Notify App","Substitute Default";
BA_DEF_REL_ BU_SG_REL_  "GenSigTimeoutMsg" HEX -2147483648 268435455;
BA_DEF_REL_ BU_SG_REL_  "GenSigTimeoutTime" INT 0 15000;
BA_DEF_DEF_  "BusType" "";
BA_DEF_DEF_  "VNSigSLHS_VNReq" "No";
BA_DEF_DEF_  "VNSigSLHSSharedDiagnostic" "No";
BA_DEF_DEF_  "SignalType" "";
BA_DEF_DEF_  "PacketOrder" 0;
BA_DEF_DEF_  "SignalLongName" "";
BA_DEF_DEF_  "GenSigStartValue" 0;
BA_DEF_DEF_  "VNSigAllNodes" "No";
BA_DEF_DEF_  "GenSigDeltaValue" 0;
BA_DEF_DEF_  "GenSigSendType_signal" "NoSigSendType";
BA_DEF_DEF_  "GenSigSendOnInit_signal" "Not Initialized";
BA_DEF_DEF_  "GenSigSendType" "NoSigSendType";
BA_DEF_DEF_  "GenSigSendOnInit" "Not Initialized";
BA_DEF_DEF_  "GenMsgILSupport" "Yes";
BA_DEF_DEF_  "TpApplType" "";
BA_DEF_DEF_  "Prio" 4;
BA_DEF_DEF_  "MessageSubnet" "LS";
BA_DEF_DEF_  "DiagState" "No";
BA_DEF_DEF_  "GenMsgDelayTime" 0;
BA_DEF_DEF_  "GenMsgCycleTime" 0;
BA_DEF_DEF_  "GenMsgSendType" "spontanX";
BA_DEF_DEF_  "DiagResponse" "No";
BA_DEF_DEF_  "DiagRequest" "No";
BA_DEF_DEF_  "NmMessage" "No";
BA_DEF_DEF_  "NmNode" "Yes";
BA_DEF_DEF_  "ILUsed" "Yes";
BA_DEF_DEF_  "NodeLayerModules" "gmlan02.dll";
BA_DEF_DEF_  "D22_FRdDataByPID" "No";
BA_DEF_DEF_  "D22_ReqType" "Both";
BA_DEF_DEF_  "D2D_ReqType" "Both";
BA_DEF_DEF_  "DAE_ReqType" "Both";
BA_DEF_DEF_  "DAE_NE3" "No";
BA_DEF_DEF_  "DAE_N78" "No";
BA_DEF_DEF_  "DAE_N31" "No";
BA_DEF_DEF_  "DAE_N12" "No";
BA_DEF_DEF_  "DAE_FDevCtrl" "No";
BA_DEF_DEF_  "DAA_ReqType" "Both";
BA_DEF_DEF_  "DAA_N81" "No";
BA_DEF_DEF_  "DAA_N78" "No";
BA_DEF_DEF_  "DAA_N31" "No";
BA_DEF_DEF_  "DAA_N12" "No";
BA_DEF_DEF_  "DAA_L04_FastRate" "No";
BA_DEF_DEF_  "DAA_L03_MedRate" "No";
BA_DEF_DEF_  "DAA_L02_SlowRate" "No";
BA_DEF_DEF_  "DAA_L01_SndOneRsp" "No";
BA_DEF_DEF_  "DAA_L00_StopSnd" "No";
BA_DEF_DEF_  "DAA_FRdDPID" "No";
BA_DEF_DEF_  "DA9_ReqType" "Both";
BA_DEF_DEF_  "DA9_N78" "No";
BA_DEF_DEF_  "DA9_N31" "No";
BA_DEF_DEF_  "DA9_N12" "No";
BA_DEF_DEF_  "DA9_L82_SndChgDTC" "No";
BA_DEF_DEF_  "DA9_L81_RdStatDTCbyMsk" "No";
BA_DEF_DEF_  "DA9_L80_RdStatDTCbyNum" "No";
BA_DEF_DEF_  "DA9_FRdDiagInfo" "Yes";
BA_DEF_DEF_  "DA5_ReqType" "Both";
BA_DEF_DEF_  "DA5_N78" "No";
BA_DEF_DEF_  "DA5_N22" "No";
BA_DEF_DEF_  "DA5_N12" "No";
BA_DEF_DEF_  "DA5_L03_EnabProgMode" "No";
BA_DEF_DEF_  "DA5_L02_ReqProgModeHS" "No";
BA_DEF_DEF_  "DA5_L01_ReqProgMode" "No";
BA_DEF_DEF_  "DA5_FProgMode" "Yes";
BA_DEF_DEF_  "DA2_ReqType" "Both";
BA_DEF_DEF_  "DA2_N78" "No";
BA_DEF_DEF_  "DA2_N12" "No";
BA_DEF_DEF_  "DA2_FRptPrgStat" "Yes";
BA_DEF_DEF_  "D3E_ReqType" "Both";
BA_DEF_DEF_  "D3E_N12" "No";
BA_DEF_DEF_  "D3E_FTstrPres" "Yes";
BA_DEF_DEF_  "D3B_ReqType" "Both";
BA_DEF_DEF_  "D3B_N78" "No";
BA_DEF_DEF_  "D3B_N31" "No";
BA_DEF_DEF_  "D3B_N22" "No";
BA_DEF_DEF_  "D3B_N12" "No";
BA_DEF_DEF_  "D3B_FWrtBlk" "No";
BA_DEF_DEF_  "D36_ReqType" "Both";
BA_DEF_DEF_  "D36_N89" "No";
BA_DEF_DEF_  "D36_N85" "No";
BA_DEF_DEF_  "D36_N83" "No";
BA_DEF_DEF_  "D36_N78" "No";
BA_DEF_DEF_  "D36_N31" "No";
BA_DEF_DEF_  "D36_N22" "No";
BA_DEF_DEF_  "D36_N12" "No";
BA_DEF_DEF_  "D36_L80_DwnldExec" "No";
BA_DEF_DEF_  "D36_L00_DownLoad" "No";
BA_DEF_DEF_  "D36_FXfrData" "Yes";
BA_DEF_DEF_  "D34_ReqType" "Both";
BA_DEF_DEF_  "D34_N99" "No";
BA_DEF_DEF_  "D34_N78" "No";
BA_DEF_DEF_  "D34_N22" "No";
BA_DEF_DEF_  "D34_N12" "No";
BA_DEF_DEF_  "D34_FReqDwnld" "Yes";
BA_DEF_DEF_  "D2C_ReqType" "Both";
BA_DEF_DEF_  "D2C_N78" "No";
BA_DEF_DEF_  "D2C_N31" "No";
BA_DEF_DEF_  "D2C_N12" "No";
BA_DEF_DEF_  "D2C_FDynMsg" "No";
BA_DEF_DEF_  "D28_ReqType" "Both";
BA_DEF_DEF_  "D28_N22" "No";
BA_DEF_DEF_  "D28_N12" "No";
BA_DEF_DEF_  "D28_FDisNormComm" "Yes";
BA_DEF_DEF_  "D27_ReqType" "Both";
BA_DEF_DEF_  "D27_N78" "No";
BA_DEF_DEF_  "D27_N37" "No";
BA_DEF_DEF_  "D27_N36" "No";
BA_DEF_DEF_  "D27_N35" "No";
BA_DEF_DEF_  "D27_N22" "No";
BA_DEF_DEF_  "D27_N12" "No";
BA_DEF_DEF_  "D27_L02_SndKey" "No";
BA_DEF_DEF_  "D27_L01_ReqSeed" "No";
BA_DEF_DEF_  "D27_FSecAcc" "No";
BA_DEF_DEF_  "D23_ReqType" "Both";
BA_DEF_DEF_  "D23_N78" "No";
BA_DEF_DEF_  "D23_N31" "No";
BA_DEF_DEF_  "D23_N12" "No";
BA_DEF_DEF_  "D23_FRdMemAddr" "No";
BA_DEF_DEF_  "D20_ReqType" "Both";
BA_DEF_DEF_  "D20_N12" "No";
BA_DEF_DEF_  "D20_FRtnNormComm" "Yes";
BA_DEF_DEF_  "D1A_ReqType" "Both";
BA_DEF_DEF_  "D1A_N78" "No";
BA_DEF_DEF_  "D1A_N31" "No";
BA_DEF_DEF_  "D1A_N22" "No";
BA_DEF_DEF_  "D1A_N12" "No";
BA_DEF_DEF_  "D1A_FRdDataID" "Yes";
BA_DEF_DEF_  "D12_ReqType" "Both";
BA_DEF_DEF_  "D12_N78" "No";
BA_DEF_DEF_  "D12_N31" "No";
BA_DEF_DEF_  "D12_N12" "No";
BA_DEF_DEF_  "D12_L02_RdFRcdParam" "No";
BA_DEF_DEF_  "D12_L01_RdFRcdData" "No";
BA_DEF_DEF_  "D12_FRdFailRec" "No";
BA_DEF_DEF_  "D10_ReqType" "Both";
BA_DEF_DEF_  "D10_N78" "No";
BA_DEF_DEF_  "D10_N22" "No";
BA_DEF_DEF_  "D10_N12" "No";
BA_DEF_DEF_  "D10_L04_WakeUpLinks" "No";
BA_DEF_DEF_  "D10_L03_DTCsDurDevCtrl" "No";
BA_DEF_DEF_  "D10_L02_DisAllDTCs" "No";
BA_DEF_DEF_  "D10_FInitDiagOp" "Yes";
BA_DEF_DEF_  "D04_ReqType" "Both";
BA_DEF_DEF_  "D04_N78" "No";
BA_DEF_DEF_  "D04_N22" "No";
BA_DEF_DEF_  "D04_N12" "No";
BA_DEF_DEF_  "D04_FClrDTC" "Yes";
BA_DEF_DEF_  "NmStationAddress" 0;
BA_DEF_DEF_  "ECU_Id_Node" 0;
BA_DEF_DEF_  "SourceId_Node" 0;
BA_DEF_DEF_  "VNECUSLHSSharedDiagnostic" "None";
BA_DEF_DEF_  "VNECUSLHS_VNReq" "None";
BA_DEF_DEF_  "VNECUAllNodes" "None";
BA_DEF_DEF_  "SourceId" 0;
BA_DEF_DEF_  "ECU_Id" 0;
BA_DEF_DEF_  "SyncJumpWidthMax" 0;
BA_DEF_DEF_  "SyncJumpWidthMin" 0;
BA_DEF_DEF_  "SamplePointMax" 0;
BA_DEF_DEF_  "SamplePointMin" 0;
BA_DEF_DEF_  "Baudrate" 0;
BA_DEF_DEF_  "VehicleArchitecture" "";
BA_DEF_DEF_  "VNInitActSLHS_VNReq" "No";
BA_DEF_DEF_  "VN_SLHS_VNReq" 2;
BA_DEF_DEF_  "VNInitActSLHSSharedDiagnostic" "No";
BA_DEF_DEF_  "VN_SLHSSharedDiagnostic" 0;
BA_DEF_DEF_  "VersionNumber" 120;
BA_DEF_DEF_  "NmMessageCount" 32;
BA_DEF_DEF_  "NmBaseAddress" 1568;
BA_DEF_DEF_  "NetworkType" "";
BA_DEF_DEF_  "VNMFPeriodicInterval" 3000;
BA_DEF_DEF_  "BusWakeUpDelay" 100;
BA_DEF_DEF_  "BusOffRecoveryTime" 0;
BA_DEF_DEF_  "NodeStatusMsgID" 335536128;
BA_DEF_DEF_  "NodeStatusMsgCycleTime" 1200;
BA_DEF_DEF_  "NodeStatusMsgTimeoutTime" 3000;
BA_DEF_DEF_  "UseGMParameterIDs" 1;
BA_DEF_DEF_  "VersionWeek" 0;
BA_DEF_DEF_  "VersionYear" 9;
BA_DEF_DEF_  "VN_AllNodes" 1;
BA_DEF_DEF_  "Manufacturer" "GM";
BA_DEF_DEF_  "NmType" "GMLAN";
BA_DEF_DEF_REL_ "GenSigSuprvRespComment" "";
BA_DEF_DEF_REL_ "GenSigVBitResp" "No";
BA_DEF_DEF_REL_ "GenSigVBitRespComment" "";
BA_DEF_DEF_REL_ "GenSigVDAFailComment" "";
BA_DEF_DEF_REL_ "GenSigVDAFailResp" "No";
BA_DEF_DEF_REL_ "GenSigRxStartValue" "";
BA_DEF_DEF_REL_ "GenSigSuprvRespSubValue" 0;
BA_DEF_DEF_REL_ "GenSigSuprvResp" "None";
BA_DEF_DEF_REL_ "GenSigTimeoutMsg" 0;
BA_DEF_DEF_REL_ "GenSigTimeoutTime" 0;
BA_ "BusType" "CAN";
BA_ "VersionYear" 3;
BA_ "VersionWeek" 40;
BA_ "UseGMParameterIDs" 0;
BA_ "NodeStatusMsgTimeoutTime" 0;
BA_ "NodeStatusMsgID" 0;
BA_ "BusOffRecoveryTime" 160;
BA_ "BusWakeUpDelay" 70;
BA_ "NetworkType" "CAN";
BA_ "NmBaseAddress" 1536;
BA_ "NmMessageCount" 16;
BA_ "VNInitActSLHSSharedDiagnostic" 1;
BA_ "VNInitActSLHS_VNReq" 1;
BA_ "VehicleArchitecture" "CLEA";
BA_ "Baudrate" 500000;
BA_ "SamplePointMin" 80;
BA_ "SamplePointMax" 81.25;
BA_ "SyncJumpWidthMin" 2;
BA_ "SyncJumpWidthMax" 3;
BA_ "VNECUSLHS_VNReq" BU_ TPM_HS 4;
BA_ "DAE_NE3" BU_ TPM_HS 1;
BA_ "DAE_N78" BU_ TPM_HS 1;
BA_ "DAE_N31" BU_ TPM_HS 1;
BA_ "DAE_N12" BU_ TPM_HS 1;
BA_ "DAE_FDevCtrl" BU_ TPM_HS 1;
BA_ "DAA_N81" BU_ TPM_HS 1;
BA_ "VNECUSLHSSharedDiagnostic" BU_ TPM_HS 4;
BA_ "VNECUAllNodes" BU_ TPM_HS 4;
BA_ "D04_N78" BU_ TPM_HS 1;
BA_ "D04_N22" BU_ TPM_HS 1;
BA_ "D04_N12" BU_ TPM_HS 1;
BA_ "SourceId" BU_ TPM_HS 35;
BA_ "ECU_Id" BU_ TPM_HS 35;
BA_ "SourceId_Node" BU_ TPM_HS 35;
BA_ "ECU_Id_Node" BU_ TPM_HS 35;
BA_ "D10_L02_DisAllDTCs" BU_ TPM_HS 1;
BA_ "D10_L03_DTCsDurDevCtrl" BU_ TPM_HS 1;
BA_ "D10_L04_WakeUpLinks" BU_ TPM_HS 1;
BA_ "D10_N12" BU_ TPM_HS 1;
BA_ "D10_N22" BU_ TPM_HS 1;
BA_ "D12_N31" BU_ TPM_HS 1;
BA_ "D1A_N12" BU_ TPM_HS 1;
BA_ "D1A_N22" BU_ TPM_HS 1;
BA_ "D1A_N31" BU_ TPM_HS 1;
BA_ "D1A_N78" BU_ TPM_HS 1;
BA_ "D20_N12" BU_ TPM_HS 1;
BA_ "D23_N78" BU_ TPM_HS 1;
BA_ "D23_N31" BU_ TPM_HS 1;
BA_ "D23_N12" BU_ TPM_HS 1;
BA_ "D23_FRdMemAddr" BU_ TPM_HS 1;
BA_ "D27_N78" BU_ TPM_HS 1;
BA_ "D27_N37" BU_ TPM_HS 1;
BA_ "D27_N36" BU_ TPM_HS 1;
BA_ "D27_N35" BU_ TPM_HS 1;
BA_ "D27_N22" BU_ TPM_HS 1;
BA_ "D27_N12" BU_ TPM_HS 1;
BA_ "D27_L02_SndKey" BU_ TPM_HS 1;
BA_ "D27_L01_ReqSeed" BU_ TPM_HS 1;
BA_ "D27_FSecAcc" BU_ TPM_HS 1;
BA_ "D28_N12" BU_ TPM_HS 1;
BA_ "D28_N22" BU_ TPM_HS 1;
BA_ "D2C_FDynMsg" BU_ TPM_HS 1;
BA_ "D2C_N12" BU_ TPM_HS 1;
BA_ "D2C_N31" BU_ TPM_HS 1;
BA_ "D2C_N78" BU_ TPM_HS 1;
BA_ "D34_N12" BU_ TPM_HS 1;
BA_ "D34_N22" BU_ TPM_HS 1;
BA_ "D34_N78" BU_ TPM_HS 1;
BA_ "D34_N99" BU_ TPM_HS 1;
BA_ "D36_L00_DownLoad" BU_ TPM_HS 1;
BA_ "D36_L80_DwnldExec" BU_ TPM_HS 1;
BA_ "D36_N12" BU_ TPM_HS 1;
BA_ "D36_N22" BU_ TPM_HS 1;
BA_ "D36_N31" BU_ TPM_HS 1;
BA_ "D36_N78" BU_ TPM_HS 1;
BA_ "D36_N83" BU_ TPM_HS 1;
BA_ "D36_N85" BU_ TPM_HS 1;
BA_ "D3B_N31" BU_ TPM_HS 1;
BA_ "D3B_N22" BU_ TPM_HS 1;
BA_ "D3B_N12" BU_ TPM_HS 1;
BA_ "D3B_FWrtBlk" BU_ TPM_HS 1;
BA_ "D3B_N78" BU_ TPM_HS 1;
BA_ "DA5_L03_EnabProgMode" BU_ TPM_HS 1;
BA_ "DA5_L01_ReqProgMode" BU_ TPM_HS 1;
BA_ "DA2_N78" BU_ TPM_HS 1;
BA_ "DA2_N12" BU_ TPM_HS 1;
BA_ "D3E_N12" BU_ TPM_HS 1;
BA_ "DA9_N78" BU_ TPM_HS 1;
BA_ "DA9_N31" BU_ TPM_HS 1;
BA_ "DA9_N12" BU_ TPM_HS 1;
BA_ "DA5_N78" BU_ TPM_HS 1;
BA_ "DA5_N22" BU_ TPM_HS 1;
BA_ "DA5_N12" BU_ TPM_HS 1;
BA_ "DAA_N78" BU_ TPM_HS 1;
BA_ "DAA_N31" BU_ TPM_HS 1;
BA_ "DAA_N12" BU_ TPM_HS 1;
BA_ "DAA_L04_FastRate" BU_ TPM_HS 1;
BA_ "DAA_L03_MedRate" BU_ TPM_HS 1;
BA_ "DAA_L02_SlowRate" BU_ TPM_HS 1;
BA_ "DAA_L01_SndOneRsp" BU_ TPM_HS 1;
BA_ "DAA_L00_StopSnd" BU_ TPM_HS 1;
BA_ "DAA_FRdDPID" BU_ TPM_HS 1;
BA_ "SourceId_Node" BU_ EPS_HS 49;
BA_ "ECU_Id_Node" BU_ EPS_HS 2;
BA_ "ECU_Id" BU_ EPS_HS 2;
BA_ "SourceId" BU_ EPS_HS 49;
BA_ "VNECUAllNodes" BU_ EPS_HS 4;
BA_ "VNECUSLHS_VNReq" BU_ EPS_HS 4;
BA_ "VNECUSLHSSharedDiagnostic" BU_ EPS_HS 4;
BA_ "DAE_NE3" BU_ EPS_HS 1;
BA_ "DAE_N78" BU_ EPS_HS 1;
BA_ "DAE_N31" BU_ EPS_HS 1;
BA_ "DAE_N12" BU_ EPS_HS 1;
BA_ "DAE_FDevCtrl" BU_ EPS_HS 1;
BA_ "DAA_N81" BU_ EPS_HS 1;
BA_ "D04_N78" BU_ EPS_HS 1;
BA_ "D04_N22" BU_ EPS_HS 1;
BA_ "D04_N12" BU_ EPS_HS 1;
BA_ "D10_L02_DisAllDTCs" BU_ EPS_HS 1;
BA_ "D10_L03_DTCsDurDevCtrl" BU_ EPS_HS 1;
BA_ "D10_L04_WakeUpLinks" BU_ EPS_HS 1;
BA_ "D10_N12" BU_ EPS_HS 1;
BA_ "D10_N22" BU_ EPS_HS 1;
BA_ "D12_N31" BU_ EPS_HS 1;
BA_ "D1A_N12" BU_ EPS_HS 1;
BA_ "D1A_N22" BU_ EPS_HS 1;
BA_ "D1A_N31" BU_ EPS_HS 1;
BA_ "D1A_N78" BU_ EPS_HS 1;
BA_ "D20_N12" BU_ EPS_HS 1;
BA_ "D23_N78" BU_ EPS_HS 1;
BA_ "D23_N31" BU_ EPS_HS 1;
BA_ "D23_N12" BU_ EPS_HS 1;
BA_ "D23_FRdMemAddr" BU_ EPS_HS 1;
BA_ "D27_N78" BU_ EPS_HS 1;
BA_ "D27_N37" BU_ EPS_HS 1;
BA_ "D27_N36" BU_ EPS_HS 1;
BA_ "D27_N35" BU_ EPS_HS 1;
BA_ "D27_N22" BU_ EPS_HS 1;
BA_ "D27_N12" BU_ EPS_HS 1;
BA_ "D27_L02_SndKey" BU_ EPS_HS 1;
BA_ "D27_L01_ReqSeed" BU_ EPS_HS 1;
BA_ "D27_FSecAcc" BU_ EPS_HS 1;
BA_ "D28_N12" BU_ EPS_HS 1;
BA_ "D28_N22" BU_ EPS_HS 1;
BA_ "D2C_FDynMsg" BU_ EPS_HS 1;
BA_ "D2C_N12" BU_ EPS_HS 1;
BA_ "D2C_N31" BU_ EPS_HS 1;
BA_ "D2C_N78" BU_ EPS_HS 1;
BA_ "D34_N12" BU_ EPS_HS 1;
BA_ "D34_N22" BU_ EPS_HS 1;
BA_ "D34_N78" BU_ EPS_HS 1;
BA_ "D34_N99" BU_ EPS_HS 1;
BA_ "D36_L00_DownLoad" BU_ EPS_HS 1;
BA_ "D36_L80_DwnldExec" BU_ EPS_HS 1;
BA_ "D36_N12" BU_ EPS_HS 1;
BA_ "D36_N22" BU_ EPS_HS 1;
BA_ "D36_N31" BU_ EPS_HS 1;
BA_ "D36_N78" BU_ EPS_HS 1;
BA_ "D36_N83" BU_ EPS_HS 1;
BA_ "D36_N85" BU_ EPS_HS 1;
BA_ "D3B_N31" BU_ EPS_HS 1;
BA_ "D3B_N22" BU_ EPS_HS 1;
BA_ "D3B_N12" BU_ EPS_HS 1;
BA_ "D3B_FWrtBlk" BU_ EPS_HS 1;
BA_ "D3B_N78" BU_ EPS_HS 1;
BA_ "DA5_L03_EnabProgMode" BU_ EPS_HS 1;
BA_ "DA5_L01_ReqProgMode" BU_ EPS_HS 1;
BA_ "DA2_N78" BU_ EPS_HS 1;
BA_ "DA2_N12" BU_ EPS_HS 1;
BA_ "D3E_N12" BU_ EPS_HS 1;
BA_ "DA9_N78" BU_ EPS_HS 1;
BA_ "DA9_N31" BU_ EPS_HS 1;
BA_ "DA9_N12" BU_ EPS_HS 1;
BA_ "DA5_N78" BU_ EPS_HS 1;
BA_ "DA5_N22" BU_ EPS_HS 1;
BA_ "DA5_N12" BU_ EPS_HS 1;
BA_ "DAA_N78" BU_ EPS_HS 1;
BA_ "DAA_N31" BU_ EPS_HS 1;
BA_ "DAA_N12" BU_ EPS_HS 1;
BA_ "DAA_L04_FastRate" BU_ EPS_HS 1;
BA_ "DAA_L03_MedRate" BU_ EPS_HS 1;
BA_ "DAA_L02_SlowRate" BU_ EPS_HS 1;
BA_ "DAA_L01_SndOneRsp" BU_ EPS_HS 1;
BA_ "DAA_L00_StopSnd" BU_ EPS_HS 1;
BA_ "DAA_FRdDPID" BU_ EPS_HS 1;
BA_ "SourceId_Node" BU_ IPC_HS 96;
BA_ "ECU_Id_Node" BU_ IPC_HS 12;
BA_ "ECU_Id" BU_ IPC_HS 12;
BA_ "SourceId" BU_ IPC_HS 96;
BA_ "VNECUAllNodes" BU_ IPC_HS 4;
BA_ "VNECUSLHS_VNReq" BU_ IPC_HS 4;
BA_ "VNECUSLHSSharedDiagnostic" BU_ IPC_HS 4;
BA_ "DAE_NE3" BU_ IPC_HS 1;
BA_ "DAE_N78" BU_ IPC_HS 1;
BA_ "DAE_N31" BU_ IPC_HS 1;
BA_ "DAE_N12" BU_ IPC_HS 1;
BA_ "DAE_FDevCtrl" BU_ IPC_HS 1;
BA_ "DAA_N81" BU_ IPC_HS 1;
BA_ "D04_N78" BU_ IPC_HS 1;
BA_ "D04_N22" BU_ IPC_HS 1;
BA_ "D04_N12" BU_ IPC_HS 1;
BA_ "D10_L02_DisAllDTCs" BU_ IPC_HS 1;
BA_ "D10_L03_DTCsDurDevCtrl" BU_ IPC_HS 1;
BA_ "D10_L04_WakeUpLinks" BU_ IPC_HS 1;
BA_ "D10_N12" BU_ IPC_HS 1;
BA_ "D10_N22" BU_ IPC_HS 1;
BA_ "D12_N31" BU_ IPC_HS 1;
BA_ "D1A_N12" BU_ IPC_HS 1;
BA_ "D1A_N22" BU_ IPC_HS 1;
BA_ "D1A_N31" BU_ IPC_HS 1;
BA_ "D1A_N78" BU_ IPC_HS 1;
BA_ "D20_N12" BU_ IPC_HS 1;
BA_ "D23_N78" BU_ IPC_HS 1;
BA_ "D23_N31" BU_ IPC_HS 1;
BA_ "D23_N12" BU_ IPC_HS 1;
BA_ "D23_FRdMemAddr" BU_ IPC_HS 1;
BA_ "D27_N78" BU_ IPC_HS 1;
BA_ "D27_N37" BU_ IPC_HS 1;
BA_ "D27_N36" BU_ IPC_HS 1;
BA_ "D27_N35" BU_ IPC_HS 1;
BA_ "D27_N22" BU_ IPC_HS 1;
BA_ "D27_N12" BU_ IPC_HS 1;
BA_ "D27_L02_SndKey" BU_ IPC_HS 1;
BA_ "D27_L01_ReqSeed" BU_ IPC_HS 1;
BA_ "D27_FSecAcc" BU_ IPC_HS 1;
BA_ "D28_N12" BU_ IPC_HS 1;
BA_ "D28_N22" BU_ IPC_HS 1;
BA_ "D2C_FDynMsg" BU_ IPC_HS 1;
BA_ "D2C_N12" BU_ IPC_HS 1;
BA_ "D2C_N31" BU_ IPC_HS 1;
BA_ "D2C_N78" BU_ IPC_HS 1;
BA_ "D34_N12" BU_ IPC_HS 1;
BA_ "D34_N22" BU_ IPC_HS 1;
BA_ "D34_N78" BU_ IPC_HS 1;
BA_ "D34_N99" BU_ IPC_HS 1;
BA_ "D36_L00_DownLoad" BU_ IPC_HS 1;
BA_ "D36_L80_DwnldExec" BU_ IPC_HS 1;
BA_ "D36_N12" BU_ IPC_HS 1;
BA_ "D36_N22" BU_ IPC_HS 1;
BA_ "D36_N31" BU_ IPC_HS 1;
BA_ "D36_N78" BU_ IPC_HS 1;
BA_ "D36_N83" BU_ IPC_HS 1;
BA_ "D36_N85" BU_ IPC_HS 1;
BA_ "D3B_N31" BU_ IPC_HS 1;
BA_ "D3B_N22" BU_ IPC_HS 1;
BA_ "D3B_N12" BU_ IPC_HS 1;
BA_ "D3B_FWrtBlk" BU_ IPC_HS 1;
BA_ "D3B_N78" BU_ IPC_HS 1;
BA_ "DA5_L03_EnabProgMode" BU_ IPC_HS 1;
BA_ "DA5_L01_ReqProgMode" BU_ IPC_HS 1;
BA_ "DA2_N78" BU_ IPC_HS 1;
BA_ "DA2_N12" BU_ IPC_HS 1;
BA_ "D3E_N12" BU_ IPC_HS 1;
BA_ "DA9_N78" BU_ IPC_HS 1;
BA_ "DA9_N31" BU_ IPC_HS 1;
BA_ "DA9_N12" BU_ IPC_HS 1;
BA_ "DA5_N78" BU_ IPC_HS 1;
BA_ "DA5_N22" BU_ IPC_HS 1;
BA_ "DA5_N12" BU_ IPC_HS 1;
BA_ "DAA_N78" BU_ IPC_HS 1;
BA_ "DAA_N31" BU_ IPC_HS 1;
BA_ "DAA_N12" BU_ IPC_HS 1;
BA_ "DAA_L04_FastRate" BU_ IPC_HS 1;
BA_ "DAA_L03_MedRate" BU_ IPC_HS 1;
BA_ "DAA_L02_SlowRate" BU_ IPC_HS 1;
BA_ "DAA_L01_SndOneRsp" BU_ IPC_HS 1;
BA_ "DAA_L00_StopSnd" BU_ IPC_HS 1;
BA_ "DAA_FRdDPID" BU_ IPC_HS 1;
BA_ "SourceId_Node" BU_ TestTool_HS 253;
BA_ "SourceId" BU_ TestTool_HS 253;
BA_ "VNECUSLHSSharedDiagnostic" BU_ TestTool_HS 4;
BA_ "DAE_NE3" BU_ TestTool_HS 1;
BA_ "DAE_N78" BU_ TestTool_HS 1;
BA_ "DAE_N31" BU_ TestTool_HS 1;
BA_ "DAE_N12" BU_ TestTool_HS 1;
BA_ "DAE_FDevCtrl" BU_ TestTool_HS 1;
BA_ "DAA_N81" BU_ TestTool_HS 1;
BA_ "VNECUAllNodes" BU_ TestTool_HS 4;
BA_ "VNECUSLHS_VNReq" BU_ TestTool_HS 4;
BA_ "D04_N78" BU_ TestTool_HS 1;
BA_ "D04_N22" BU_ TestTool_HS 1;
BA_ "D04_N12" BU_ TestTool_HS 1;
BA_ "D10_L02_DisAllDTCs" BU_ TestTool_HS 1;
BA_ "D10_L03_DTCsDurDevCtrl" BU_ TestTool_HS 1;
BA_ "D10_L04_WakeUpLinks" BU_ TestTool_HS 1;
BA_ "D10_N12" BU_ TestTool_HS 1;
BA_ "D10_N22" BU_ TestTool_HS 1;
BA_ "D12_N31" BU_ TestTool_HS 1;
BA_ "D1A_N12" BU_ TestTool_HS 1;
BA_ "D1A_N22" BU_ TestTool_HS 1;
BA_ "D1A_N31" BU_ TestTool_HS 1;
BA_ "D1A_N78" BU_ TestTool_HS 1;
BA_ "D20_N12" BU_ TestTool_HS 1;
BA_ "D23_N78" BU_ TestTool_HS 1;
BA_ "D23_N31" BU_ TestTool_HS 1;
BA_ "D23_N12" BU_ TestTool_HS 1;
BA_ "D23_FRdMemAddr" BU_ TestTool_HS 1;
BA_ "D27_N78" BU_ TestTool_HS 1;
BA_ "D27_N37" BU_ TestTool_HS 1;
BA_ "D27_N36" BU_ TestTool_HS 1;
BA_ "D27_N35" BU_ TestTool_HS 1;
BA_ "D27_N22" BU_ TestTool_HS 1;
BA_ "D27_N12" BU_ TestTool_HS 1;
BA_ "D27_L02_SndKey" BU_ TestTool_HS 1;
BA_ "D27_L01_ReqSeed" BU_ TestTool_HS 1;
BA_ "D27_FSecAcc" BU_ TestTool_HS 1;
BA_ "D28_N12" BU_ TestTool_HS 1;
BA_ "D28_N22" BU_ TestTool_HS 1;
BA_ "D2C_FDynMsg" BU_ TestTool_HS 1;
BA_ "D2C_N12" BU_ TestTool_HS 1;
BA_ "D2C_N31" BU_ TestTool_HS 1;
BA_ "D2C_N78" BU_ TestTool_HS 1;
BA_ "D34_N12" BU_ TestTool_HS 1;
BA_ "D34_N22" BU_ TestTool_HS 1;
BA_ "D34_N78" BU_ TestTool_HS 1;
BA_ "D34_N99" BU_ TestTool_HS 1;
BA_ "D36_L00_DownLoad" BU_ TestTool_HS 1;
BA_ "D36_L80_DwnldExec" BU_ TestTool_HS 1;
BA_ "D36_N12" BU_ TestTool_HS 1;
BA_ "D36_N22" BU_ TestTool_HS 1;
BA_ "D36_N31" BU_ TestTool_HS 1;
BA_ "D36_N78" BU_ TestTool_HS 1;
BA_ "D36_N83" BU_ TestTool_HS 1;
BA_ "D36_N85" BU_ TestTool_HS 1;
BA_ "D3B_N31" BU_ TestTool_HS 1;
BA_ "D3B_N22" BU_ TestTool_HS 1;
BA_ "D3B_N12" BU_ TestTool_HS 1;
BA_ "D3B_FWrtBlk" BU_ TestTool_HS 1;
BA_ "D3B_N78" BU_ TestTool_HS 1;
BA_ "DA5_L03_EnabProgMode" BU_ TestTool_HS 1;
BA_ "DA5_L01_ReqProgMode" BU_ TestTool_HS 1;
BA_ "DA2_N78" BU_ TestTool_HS 1;
BA_ "DA2_N12" BU_ TestTool_HS 1;
BA_ "D3E_N12" BU_ TestTool_HS 1;
BA_ "DA9_N78" BU_ TestTool_HS 1;
BA_ "DA9_N31" BU_ TestTool_HS 1;
BA_ "DA9_N12" BU_ TestTool_HS 1;
BA_ "DA5_N78" BU_ TestTool_HS 1;
BA_ "DA5_N22" BU_ TestTool_HS 1;
BA_ "DA5_N12" BU_ TestTool_HS 1;
BA_ "DAA_N78" BU_ TestTool_HS 1;
BA_ "DAA_N31" BU_ TestTool_HS 1;
BA_ "DAA_N12" BU_ TestTool_HS 1;
BA_ "DAA_L04_FastRate" BU_ TestTool_HS 1;
BA_ "DAA_L03_MedRate" BU_ TestTool_HS 1;
BA_ "DAA_L02_SlowRate" BU_ TestTool_HS 1;
BA_ "DAA_L01_SndOneRsp" BU_ TestTool_HS 1;
BA_ "DAA_L00_StopSnd" BU_ TestTool_HS 1;
BA_ "DAA_FRdDPID" BU_ TestTool_HS 1;
BA_ "SourceId_Node" BU_ EBCM_HS 40;
BA_ "ECU_Id_Node" BU_ EBCM_HS 3;
BA_ "D04_N12" BU_ EBCM_HS 1;
BA_ "D04_N22" BU_ EBCM_HS 1;
BA_ "D10_L02_DisAllDTCs" BU_ EBCM_HS 1;
BA_ "D10_L03_DTCsDurDevCtrl" BU_ EBCM_HS 1;
BA_ "D10_N12" BU_ EBCM_HS 1;
BA_ "D10_N22" BU_ EBCM_HS 1;
BA_ "D12_N31" BU_ EBCM_HS 1;
BA_ "D1A_N12" BU_ EBCM_HS 1;
BA_ "D1A_N22" BU_ EBCM_HS 1;
BA_ "D1A_N31" BU_ EBCM_HS 1;
BA_ "D1A_N78" BU_ EBCM_HS 1;
BA_ "D20_N12" BU_ EBCM_HS 1;
BA_ "D23_FRdMemAddr" BU_ EBCM_HS 1;
BA_ "D23_N12" BU_ EBCM_HS 1;
BA_ "D23_N31" BU_ EBCM_HS 1;
BA_ "D27_FSecAcc" BU_ EBCM_HS 1;
BA_ "D27_L01_ReqSeed" BU_ EBCM_HS 1;
BA_ "D27_L02_SndKey" BU_ EBCM_HS 1;
BA_ "D27_N12" BU_ EBCM_HS 1;
BA_ "D27_N22" BU_ EBCM_HS 1;
BA_ "D27_N35" BU_ EBCM_HS 1;
BA_ "D27_N36" BU_ EBCM_HS 1;
BA_ "D27_N37" BU_ EBCM_HS 1;
BA_ "D27_N78" BU_ EBCM_HS 1;
BA_ "D28_N12" BU_ EBCM_HS 1;
BA_ "D28_N22" BU_ EBCM_HS 1;
BA_ "D2C_FDynMsg" BU_ EBCM_HS 1;
BA_ "D2C_N12" BU_ EBCM_HS 1;
BA_ "D2C_N31" BU_ EBCM_HS 1;
BA_ "D2C_N78" BU_ EBCM_HS 1;
BA_ "D34_N12" BU_ EBCM_HS 1;
BA_ "D34_N22" BU_ EBCM_HS 1;
BA_ "D34_N78" BU_ EBCM_HS 1;
BA_ "D34_N99" BU_ EBCM_HS 1;
BA_ "D36_L00_DownLoad" BU_ EBCM_HS 1;
BA_ "D36_L80_DwnldExec" BU_ EBCM_HS 1;
BA_ "D36_N12" BU_ EBCM_HS 1;
BA_ "D36_N22" BU_ EBCM_HS 1;
BA_ "D36_N31" BU_ EBCM_HS 1;
BA_ "D36_N78" BU_ EBCM_HS 1;
BA_ "D36_N83" BU_ EBCM_HS 1;
BA_ "D36_N85" BU_ EBCM_HS 1;
BA_ "D3B_FWrtBlk" BU_ EBCM_HS 1;
BA_ "D3B_N12" BU_ EBCM_HS 1;
BA_ "D3B_N22" BU_ EBCM_HS 1;
BA_ "D3B_N31" BU_ EBCM_HS 1;
BA_ "D3B_N78" BU_ EBCM_HS 1;
BA_ "D3E_N12" BU_ EBCM_HS 1;
BA_ "DA2_N12" BU_ EBCM_HS 1;
BA_ "DA5_L01_ReqProgMode" BU_ EBCM_HS 1;
BA_ "DA5_L03_EnabProgMode" BU_ EBCM_HS 1;
BA_ "DA5_N12" BU_ EBCM_HS 1;
BA_ "DA5_N22" BU_ EBCM_HS 1;
BA_ "DA9_N12" BU_ EBCM_HS 1;
BA_ "DA9_N31" BU_ EBCM_HS 1;
BA_ "DA9_N78" BU_ EBCM_HS 1;
BA_ "DAA_FRdDPID" BU_ EBCM_HS 1;
BA_ "DAA_L00_StopSnd" BU_ EBCM_HS 1;
BA_ "DAA_L01_SndOneRsp" BU_ EBCM_HS 1;
BA_ "DAA_L02_SlowRate" BU_ EBCM_HS 1;
BA_ "DAA_L03_MedRate" BU_ EBCM_HS 1;
BA_ "DAA_L04_FastRate" BU_ EBCM_HS 1;
BA_ "DAA_N12" BU_ EBCM_HS 1;
BA_ "DAA_N31" BU_ EBCM_HS 1;
BA_ "DAA_N78" BU_ EBCM_HS 1;
BA_ "DAA_N81" BU_ EBCM_HS 1;
BA_ "DAE_FDevCtrl" BU_ EBCM_HS 1;
BA_ "DAE_N12" BU_ EBCM_HS 1;
BA_ "DAE_N31" BU_ EBCM_HS 1;
BA_ "DAE_N78" BU_ EBCM_HS 1;
BA_ "DAE_NE3" BU_ EBCM_HS 1;
BA_ "ECU_Id" BU_ EBCM_HS 3;
BA_ "SourceId" BU_ EBCM_HS 40;
BA_ "VNECUAllNodes" BU_ EBCM_HS 4;
BA_ "VNECUSLHS_VNReq" BU_ EBCM_HS 4;
BA_ "VNECUSLHSSharedDiagnostic" BU_ EBCM_HS 4;
BA_ "D04_N78" BU_ EBCM_HS 1;
BA_ "D10_L04_WakeUpLinks" BU_ EBCM_HS 1;
BA_ "D23_N78" BU_ EBCM_HS 1;
BA_ "DA2_N78" BU_ EBCM_HS 1;
BA_ "DA5_N78" BU_ EBCM_HS 1;
BA_ "SourceId_Node" BU_ BCM_HS 64;
BA_ "ECU_Id_Node" BU_ BCM_HS 1;
BA_ "D04_N12" BU_ BCM_HS 1;
BA_ "D04_N22" BU_ BCM_HS 1;
BA_ "D04_N78" BU_ BCM_HS 1;
BA_ "D10_L02_DisAllDTCs" BU_ BCM_HS 1;
BA_ "D10_L03_DTCsDurDevCtrl" BU_ BCM_HS 1;
BA_ "D10_L04_WakeUpLinks" BU_ BCM_HS 1;
BA_ "D10_N12" BU_ BCM_HS 1;
BA_ "D10_N22" BU_ BCM_HS 1;
BA_ "D10_N78" BU_ BCM_HS 1;
BA_ "D1A_N12" BU_ BCM_HS 1;
BA_ "D1A_N22" BU_ BCM_HS 1;
BA_ "D1A_N31" BU_ BCM_HS 1;
BA_ "D1A_N78" BU_ BCM_HS 1;
BA_ "D20_N12" BU_ BCM_HS 1;
BA_ "D23_FRdMemAddr" BU_ BCM_HS 1;
BA_ "D23_N12" BU_ BCM_HS 1;
BA_ "D23_N31" BU_ BCM_HS 1;
BA_ "D23_N78" BU_ BCM_HS 1;
BA_ "D27_FSecAcc" BU_ BCM_HS 1;
BA_ "D27_L01_ReqSeed" BU_ BCM_HS 1;
BA_ "D27_L02_SndKey" BU_ BCM_HS 1;
BA_ "D27_N12" BU_ BCM_HS 1;
BA_ "D27_N22" BU_ BCM_HS 1;
BA_ "D27_N35" BU_ BCM_HS 1;
BA_ "D27_N36" BU_ BCM_HS 1;
BA_ "D27_N37" BU_ BCM_HS 1;
BA_ "D27_N78" BU_ BCM_HS 1;
BA_ "D28_N12" BU_ BCM_HS 1;
BA_ "D28_N22" BU_ BCM_HS 1;
BA_ "D2C_FDynMsg" BU_ BCM_HS 1;
BA_ "D2C_N12" BU_ BCM_HS 1;
BA_ "D2C_N31" BU_ BCM_HS 1;
BA_ "D2C_N78" BU_ BCM_HS 1;
BA_ "D34_N12" BU_ BCM_HS 1;
BA_ "D34_N22" BU_ BCM_HS 1;
BA_ "D34_N78" BU_ BCM_HS 1;
BA_ "D34_N99" BU_ BCM_HS 1;
BA_ "D36_L00_DownLoad" BU_ BCM_HS 1;
BA_ "D36_L80_DwnldExec" BU_ BCM_HS 1;
BA_ "D36_N12" BU_ BCM_HS 1;
BA_ "D36_N22" BU_ BCM_HS 1;
BA_ "D36_N31" BU_ BCM_HS 1;
BA_ "D36_N78" BU_ BCM_HS 1;
BA_ "D36_N83" BU_ BCM_HS 1;
BA_ "D36_N85" BU_ BCM_HS 1;
BA_ "D3B_FWrtBlk" BU_ BCM_HS 1;
BA_ "D3B_N12" BU_ BCM_HS 1;
BA_ "D3B_N22" BU_ BCM_HS 1;
BA_ "D3B_N31" BU_ BCM_HS 1;
BA_ "D3B_N78" BU_ BCM_HS 1;
BA_ "D3E_N12" BU_ BCM_HS 1;
BA_ "DA2_N12" BU_ BCM_HS 1;
BA_ "DA2_N78" BU_ BCM_HS 1;
BA_ "DA5_L01_ReqProgMode" BU_ BCM_HS 1;
BA_ "DA5_L03_EnabProgMode" BU_ BCM_HS 1;
BA_ "DA5_N12" BU_ BCM_HS 1;
BA_ "DA5_N22" BU_ BCM_HS 1;
BA_ "DA5_N78" BU_ BCM_HS 1;
BA_ "DA9_N12" BU_ BCM_HS 1;
BA_ "DA9_N31" BU_ BCM_HS 1;
BA_ "DA9_N78" BU_ BCM_HS 1;
BA_ "DAA_FRdDPID" BU_ BCM_HS 1;
BA_ "DAA_L00_StopSnd" BU_ BCM_HS 1;
BA_ "DAA_L01_SndOneRsp" BU_ BCM_HS 1;
BA_ "DAA_L02_SlowRate" BU_ BCM_HS 1;
BA_ "DAA_L03_MedRate" BU_ BCM_HS 1;
BA_ "DAA_L04_FastRate" BU_ BCM_HS 1;
BA_ "DAA_N12" BU_ BCM_HS 1;
BA_ "DAA_N31" BU_ BCM_HS 1;
BA_ "DAA_N78" BU_ BCM_HS 1;
BA_ "DAA_N81" BU_ BCM_HS 1;
BA_ "DAE_FDevCtrl" BU_ BCM_HS 1;
BA_ "DAE_N12" BU_ BCM_HS 1;
BA_ "DAE_N31" BU_ BCM_HS 1;
BA_ "DAE_N78" BU_ BCM_HS 1;
BA_ "DAE_NE3" BU_ BCM_HS 1;
BA_ "ECU_Id" BU_ BCM_HS 1;
BA_ "SourceId" BU_ BCM_HS 64;
BA_ "VNECUAllNodes" BU_ BCM_HS 4;
BA_ "VNECUSLHS_VNReq" BU_ BCM_HS 4;
BA_ "VNECUSLHSSharedDiagnostic" BU_ BCM_HS 4;
BA_ "SourceId_Node" BU_ TCM_HS 24;
BA_ "ECU_Id_Node" BU_ TCM_HS 226;
BA_ "D04_N12" BU_ TCM_HS 1;
BA_ "D04_N22" BU_ TCM_HS 1;
BA_ "D04_N78" BU_ TCM_HS 1;
BA_ "D10_L02_DisAllDTCs" BU_ TCM_HS 1;
BA_ "D10_L03_DTCsDurDevCtrl" BU_ TCM_HS 1;
BA_ "D10_N12" BU_ TCM_HS 1;
BA_ "D10_N22" BU_ TCM_HS 1;
BA_ "D12_N31" BU_ TCM_HS 1;
BA_ "D1A_N12" BU_ TCM_HS 1;
BA_ "D1A_N22" BU_ TCM_HS 1;
BA_ "D1A_N31" BU_ TCM_HS 1;
BA_ "D1A_N78" BU_ TCM_HS 1;
BA_ "D20_N12" BU_ TCM_HS 1;
BA_ "D23_FRdMemAddr" BU_ TCM_HS 1;
BA_ "D23_N12" BU_ TCM_HS 1;
BA_ "D23_N31" BU_ TCM_HS 1;
BA_ "D23_N78" BU_ TCM_HS 1;
BA_ "D27_FSecAcc" BU_ TCM_HS 1;
BA_ "D27_L01_ReqSeed" BU_ TCM_HS 1;
BA_ "D27_L02_SndKey" BU_ TCM_HS 1;
BA_ "D27_N12" BU_ TCM_HS 1;
BA_ "D27_N22" BU_ TCM_HS 1;
BA_ "D27_N35" BU_ TCM_HS 1;
BA_ "D27_N36" BU_ TCM_HS 1;
BA_ "D27_N37" BU_ TCM_HS 1;
BA_ "D27_N78" BU_ TCM_HS 1;
BA_ "D28_N12" BU_ TCM_HS 1;
BA_ "D28_N22" BU_ TCM_HS 1;
BA_ "D2C_FDynMsg" BU_ TCM_HS 1;
BA_ "D2C_N12" BU_ TCM_HS 1;
BA_ "D2C_N31" BU_ TCM_HS 1;
BA_ "D2C_N78" BU_ TCM_HS 1;
BA_ "D34_N12" BU_ TCM_HS 1;
BA_ "D34_N22" BU_ TCM_HS 1;
BA_ "D34_N78" BU_ TCM_HS 1;
BA_ "D34_N99" BU_ TCM_HS 1;
BA_ "D36_L00_DownLoad" BU_ TCM_HS 1;
BA_ "D36_L80_DwnldExec" BU_ TCM_HS 1;
BA_ "D36_N12" BU_ TCM_HS 1;
BA_ "D36_N22" BU_ TCM_HS 1;
BA_ "D36_N31" BU_ TCM_HS 1;
BA_ "D36_N78" BU_ TCM_HS 1;
BA_ "D36_N83" BU_ TCM_HS 1;
BA_ "D36_N85" BU_ TCM_HS 1;
BA_ "D3B_FWrtBlk" BU_ TCM_HS 1;
BA_ "D3B_N12" BU_ TCM_HS 1;
BA_ "D3B_N22" BU_ TCM_HS 1;
BA_ "D3B_N31" BU_ TCM_HS 1;
BA_ "D3B_N78" BU_ TCM_HS 1;
BA_ "D3E_N12" BU_ TCM_HS 1;
BA_ "DA2_N12" BU_ TCM_HS 1;
BA_ "DA2_N78" BU_ TCM_HS 1;
BA_ "DA5_L01_ReqProgMode" BU_ TCM_HS 1;
BA_ "DA5_L03_EnabProgMode" BU_ TCM_HS 1;
BA_ "DA5_N12" BU_ TCM_HS 1;
BA_ "DA5_N22" BU_ TCM_HS 1;
BA_ "DA5_N78" BU_ TCM_HS 1;
BA_ "DA9_N12" BU_ TCM_HS 1;
BA_ "DA9_N31" BU_ TCM_HS 1;
BA_ "DA9_N78" BU_ TCM_HS 1;
BA_ "DAA_FRdDPID" BU_ TCM_HS 1;
BA_ "DAA_L00_StopSnd" BU_ TCM_HS 1;
BA_ "DAA_L01_SndOneRsp" BU_ TCM_HS 1;
BA_ "DAA_L02_SlowRate" BU_ TCM_HS 1;
BA_ "DAA_L03_MedRate" BU_ TCM_HS 1;
BA_ "DAA_L04_FastRate" BU_ TCM_HS 1;
BA_ "DAA_N12" BU_ TCM_HS 1;
BA_ "DAA_N31" BU_ TCM_HS 1;
BA_ "DAA_N78" BU_ TCM_HS 1;
BA_ "DAA_N81" BU_ TCM_HS 1;
BA_ "DAE_FDevCtrl" BU_ TCM_HS 1;
BA_ "DAE_N12" BU_ TCM_HS 1;
BA_ "DAE_N31" BU_ TCM_HS 1;
BA_ "DAE_N78" BU_ TCM_HS 1;
BA_ "DAE_NE3" BU_ TCM_HS 1;
BA_ "ECU_Id" BU_ TCM_HS 226;
BA_ "SourceId" BU_ TCM_HS 24;
BA_ "VNECUAllNodes" BU_ TCM_HS 4;
BA_ "VNECUSLHS_VNReq" BU_ TCM_HS 4;
BA_ "VNECUSLHSSharedDiagnostic" BU_ TCM_HS 4;
BA_ "D10_L04_WakeUpLinks" BU_ TCM_HS 1;
BA_ "SourceId_Node" BU_ ECM_HS 17;
BA_ "ECU_Id_Node" BU_ ECM_HS 224;
BA_ "D04_N12" BU_ ECM_HS 1;
BA_ "D04_N22" BU_ ECM_HS 1;
BA_ "D04_N78" BU_ ECM_HS 1;
BA_ "D10_L02_DisAllDTCs" BU_ ECM_HS 1;
BA_ "D10_L03_DTCsDurDevCtrl" BU_ ECM_HS 1;
BA_ "D10_N12" BU_ ECM_HS 1;
BA_ "D10_N22" BU_ ECM_HS 1;
BA_ "D12_N31" BU_ ECM_HS 1;
BA_ "D1A_N12" BU_ ECM_HS 1;
BA_ "D1A_N22" BU_ ECM_HS 1;
BA_ "D1A_N31" BU_ ECM_HS 1;
BA_ "D1A_N78" BU_ ECM_HS 1;
BA_ "D20_N12" BU_ ECM_HS 1;
BA_ "D23_FRdMemAddr" BU_ ECM_HS 1;
BA_ "D23_N12" BU_ ECM_HS 1;
BA_ "D23_N31" BU_ ECM_HS 1;
BA_ "D23_N78" BU_ ECM_HS 1;
BA_ "D27_FSecAcc" BU_ ECM_HS 1;
BA_ "D27_L01_ReqSeed" BU_ ECM_HS 1;
BA_ "D27_L02_SndKey" BU_ ECM_HS 1;
BA_ "D27_N12" BU_ ECM_HS 1;
BA_ "D27_N22" BU_ ECM_HS 1;
BA_ "D27_N35" BU_ ECM_HS 1;
BA_ "D27_N36" BU_ ECM_HS 1;
BA_ "D27_N37" BU_ ECM_HS 1;
BA_ "D27_N78" BU_ ECM_HS 1;
BA_ "D28_N12" BU_ ECM_HS 1;
BA_ "D28_N22" BU_ ECM_HS 1;
BA_ "D2C_FDynMsg" BU_ ECM_HS 1;
BA_ "D2C_N12" BU_ ECM_HS 1;
BA_ "D2C_N31" BU_ ECM_HS 1;
BA_ "D2C_N78" BU_ ECM_HS 1;
BA_ "D34_N12" BU_ ECM_HS 1;
BA_ "D34_N22" BU_ ECM_HS 1;
BA_ "D34_N78" BU_ ECM_HS 1;
BA_ "D34_N99" BU_ ECM_HS 1;
BA_ "D36_L00_DownLoad" BU_ ECM_HS 1;
BA_ "D36_L80_DwnldExec" BU_ ECM_HS 1;
BA_ "D36_N12" BU_ ECM_HS 1;
BA_ "D36_N22" BU_ ECM_HS 1;
BA_ "D36_N31" BU_ ECM_HS 1;
BA_ "D36_N78" BU_ ECM_HS 1;
BA_ "D36_N83" BU_ ECM_HS 1;
BA_ "D36_N85" BU_ ECM_HS 1;
BA_ "D3B_FWrtBlk" BU_ ECM_HS 1;
BA_ "D3B_N12" BU_ ECM_HS 1;
BA_ "D3B_N22" BU_ ECM_HS 1;
BA_ "D3B_N31" BU_ ECM_HS 1;
BA_ "D3B_N78" BU_ ECM_HS 1;
BA_ "D3E_N12" BU_ ECM_HS 1;
BA_ "DA2_N12" BU_ ECM_HS 1;
BA_ "DA2_N78" BU_ ECM_HS 1;
BA_ "DA5_L01_ReqProgMode" BU_ ECM_HS 1;
BA_ "DA5_L03_EnabProgMode" BU_ ECM_HS 1;
BA_ "DA5_N12" BU_ ECM_HS 1;
BA_ "DA5_N22" BU_ ECM_HS 1;
BA_ "DA5_N78" BU_ ECM_HS 1;
BA_ "DA9_N12" BU_ ECM_HS 1;
BA_ "DA9_N31" BU_ ECM_HS 1;
BA_ "DA9_N78" BU_ ECM_HS 1;
BA_ "DAA_FRdDPID" BU_ ECM_HS 1;
BA_ "DAA_L00_StopSnd" BU_ ECM_HS 1;
BA_ "DAA_L01_SndOneRsp" BU_ ECM_HS 1;
BA_ "DAA_L02_SlowRate" BU_ ECM_HS 1;
BA_ "DAA_L03_MedRate" BU_ ECM_HS 1;
BA_ "DAA_L04_FastRate" BU_ ECM_HS 1;
BA_ "DAA_N12" BU_ ECM_HS 1;
BA_ "DAA_N31" BU_ ECM_HS 1;
BA_ "DAA_N78" BU_ ECM_HS 1;
BA_ "DAA_N81" BU_ ECM_HS 1;
BA_ "DAE_FDevCtrl" BU_ ECM_HS 1;
BA_ "DAE_N12" BU_ ECM_HS 1;
BA_ "DAE_N31" BU_ ECM_HS 1;
BA_ "DAE_N78" BU_ ECM_HS 1;
BA_ "DAE_NE3" BU_ ECM_HS 1;
BA_ "ECU_Id" BU_ ECM_HS 224;
BA_ "SourceId" BU_ ECM_HS 17;
BA_ "VNECUAllNodes" BU_ ECM_HS 4;
BA_ "VNECUSLHS_VNReq" BU_ ECM_HS 4;
BA_ "VNECUSLHSSharedDiagnostic" BU_ ECM_HS 4;
BA_ "D10_L04_WakeUpLinks" BU_ ECM_HS 1;
BA_ "GenMsgSendType" BO_ 1280 0;
BA_ "GenMsgCycleTime" BO_ 1280 1000;
BA_ "MessageSubnet" BO_ 1280 2;
BA_ "Prio" BO_ 1280 0;
BA_ "GenMsgSendType" BO_ 192 0;
BA_ "GenMsgCycleTime" BO_ 192 10;
BA_ "MessageSubnet" BO_ 192 2;
BA_ "Prio" BO_ 192 0;
BA_ "GenMsgDelayTime" BO_ 546 100;
BA_ "MessageSubnet" BO_ 546 2;
BA_ "Prio" BO_ 546 0;
BA_ "MessageSubnet" BO_ 494 2;
BA_ "Prio" BO_ 494 0;
BA_ "GenMsgDelayTime" BO_ 494 100;
BA_ "DiagRequest" BO_ 591 1;
BA_ "MessageSubnet" BO_ 591 2;
BA_ "Prio" BO_ 591 0;
BA_ "DiagResponse" BO_ 1615 1;
BA_ "MessageSubnet" BO_ 1615 2;
BA_ "Prio" BO_ 1615 0;
BA_ "MessageSubnet" BO_ 1359 2;
BA_ "Prio" BO_ 1359 0;
BA_ "GenMsgSendType" BO_ 773 4;
BA_ "GenMsgCycleTime" BO_ 773 500;
BA_ "GenMsgDelayTime" BO_ 773 100;
BA_ "MessageSubnet" BO_ 773 2;
BA_ "Prio" BO_ 773 0;
BA_ "GenMsgDelayTime" BO_ 1284 100;
BA_ "MessageSubnet" BO_ 1284 2;
BA_ "Prio" BO_ 1284 0;
BA_ "GenMsgDelayTime" BO_ 1283 100;
BA_ "MessageSubnet" BO_ 1283 2;
BA_ "Prio" BO_ 1283 0;
BA_ "MessageSubnet" BO_ 519 2;
BA_ "Prio" BO_ 519 0;
BA_ "GenMsgSendType" BO_ 533 0;
BA_ "GenMsgCycleTime" BO_ 533 1000;
BA_ "Prio" BO_ 533 0;
BA_ "GenMsgSendType" BO_ 328 0;
BA_ "GenMsgCycleTime" BO_ 328 1000;
BA_ "GenMsgDelayTime" BO_ 328 100;
BA_ "MessageSubnet" BO_ 328 2;
BA_ "Prio" BO_ 328 0;
BA_ "MessageSubnet" BO_ 1346 2;
BA_ "Prio" BO_ 1346 0;
BA_ "GenMsgILSupport" BO_ 1346 0;
BA_ "DiagResponse" BO_ 1602 1;
BA_ "MessageSubnet" BO_ 1602 2;
BA_ "Prio" BO_ 1602 0;
BA_ "DiagRequest" BO_ 578 1;
BA_ "MessageSubnet" BO_ 578 2;
BA_ "Prio" BO_ 578 0;
BA_ "MessageSubnet" BO_ 528 2;
BA_ "Prio" BO_ 528 0;
BA_ "MessageSubnet" BO_ 517 2;
BA_ "Prio" BO_ 517 0;
BA_ "DiagResponse" BO_ 1612 1;
BA_ "MessageSubnet" BO_ 1612 2;
BA_ "Prio" BO_ 1612 0;
BA_ "GenMsgSendType" BO_ 401 0;
BA_ "GenMsgCycleTime" BO_ 401 12;
BA_ "MessageSubnet" BO_ 401 2;
BA_ "Prio" BO_ 401 0;
BA_ "GenMsgSendType" BO_ 1265 0;
BA_ "GenMsgCycleTime" BO_ 1265 1000;
BA_ "MessageSubnet" BO_ 1265 2;
BA_ "Prio" BO_ 1265 0;
BA_ "GenMsgSendType" BO_ 417 0;
BA_ "GenMsgCycleTime" BO_ 417 25;
BA_ "MessageSubnet" BO_ 417 2;
BA_ "Prio" BO_ 417 0;
BA_ "GenMsgSendType" BO_ 1233 0;
BA_ "GenMsgCycleTime" BO_ 1233 500;
BA_ "MessageSubnet" BO_ 1233 2;
BA_ "Prio" BO_ 1233 0;
BA_ "GenMsgSendType" BO_ 1217 0;
BA_ "GenMsgCycleTime" BO_ 1217 500;
BA_ "MessageSubnet" BO_ 1217 2;
BA_ "Prio" BO_ 1217 0;
BA_ "GenMsgSendType" BO_ 1017 0;
BA_ "GenMsgCycleTime" BO_ 1017 250;
BA_ "MessageSubnet" BO_ 1017 2;
BA_ "Prio" BO_ 1017 0;
BA_ "GenMsgSendType" BO_ 977 0;
BA_ "GenMsgCycleTime" BO_ 977 100;
BA_ "MessageSubnet" BO_ 977 2;
BA_ "Prio" BO_ 977 0;
BA_ "GenMsgSendType" BO_ 201 0;
BA_ "GenMsgCycleTime" BO_ 201 12;
BA_ "MessageSubnet" BO_ 201 2;
BA_ "Prio" BO_ 201 0;
BA_ "GenMsgSendType" BO_ 501 0;
BA_ "GenMsgCycleTime" BO_ 501 25;
BA_ "MessageSubnet" BO_ 501 2;
BA_ "Prio" BO_ 501 0;
BA_ "GenMsgSendType" BO_ 1225 0;
BA_ "GenMsgCycleTime" BO_ 1225 500;
BA_ "MessageSubnet" BO_ 1225 2;
BA_ "Prio" BO_ 1225 0;
BA_ "GenMsgSendType" BO_ 409 0;
BA_ "GenMsgCycleTime" BO_ 409 12;
BA_ "MessageSubnet" BO_ 409 2;
BA_ "Prio" BO_ 409 0;
BA_ "GenMsgSendType" BO_ 413 0;
BA_ "GenMsgCycleTime" BO_ 413 25;
BA_ "MessageSubnet" BO_ 413 2;
BA_ "Prio" BO_ 413 0;
BA_ "DiagState" BO_ 257 1;
BA_ "MessageSubnet" BO_ 257 2;
BA_ "Prio" BO_ 257 0;
BA_ "GenMsgILSupport" BO_ 257 0;
BA_ "DiagRequest" BO_ 2016 1;
BA_ "MessageSubnet" BO_ 2016 2;
BA_ "Prio" BO_ 2016 0;
BA_ "GenMsgSendType" BO_ 197 0;
BA_ "GenMsgCycleTime" BO_ 197 10;
BA_ "MessageSubnet" BO_ 197 2;
BA_ "Prio" BO_ 197 0;
BA_ "VNSigAllNodes" SG_ 1280 WhlRotStatTmstmpRes 1;
BA_ "SignalLongName" SG_ 1280 WhlRotStatTmstmpRes "Wheel Rotational Status Timestamp Resolution";
BA_ "SignalType" SG_ 1280 WhlRotStatTmstmpRes "UNM";
BA_ "VNSigAllNodes" SG_ 1280 WhlPlsPerRevNonDrvn 1;
BA_ "SignalLongName" SG_ 1280 WhlPlsPerRevNonDrvn "Wheel Pulses Per Revolution Non Driven";
BA_ "SignalType" SG_ 1280 WhlPlsPerRevNonDrvn "UNM";
BA_ "VNSigAllNodes" SG_ 1280 WhlPlsPerRevDrvn 1;
BA_ "SignalLongName" SG_ 1280 WhlPlsPerRevDrvn "Wheel Pulses Per Revolution Driven";
BA_ "SignalType" SG_ 1280 WhlPlsPerRevDrvn "UNM";
BA_ "VNSigAllNodes" SG_ 192 WRSCD_RtNDrvnSNm 1;
BA_ "SignalLongName" SG_ 192 WRSCD_RtNDrvnSNm "Wheel Rotational Status Check Data : Right Non Driven Sequence Number";
BA_ "PacketOrder" SG_ 192 WRSCD_RtNDrvnSNm 4;
BA_ "SignalType" SG_ 192 WRSCD_RtNDrvnSNm "UNM";
BA_ "VNSigAllNodes" SG_ 192 WRSCD_RtDrvnSqNm 1;
BA_ "SignalLongName" SG_ 192 WRSCD_RtDrvnSqNm "Wheel Rotational Status Check Data : Right Driven Sequence Number";
BA_ "PacketOrder" SG_ 192 WRSCD_RtDrvnSqNm 2;
BA_ "SignalType" SG_ 192 WRSCD_RtDrvnSqNm "UNM";
BA_ "VNSigAllNodes" SG_ 192 WRSCD_RNDrvnCkVa 1;
BA_ "SignalLongName" SG_ 192 WRSCD_RNDrvnCkVa "Wheel Rotational Status Check Data : Right Non Driven Check Value";
BA_ "PacketOrder" SG_ 192 WRSCD_RNDrvnCkVa 8;
BA_ "SignalType" SG_ 192 WRSCD_RNDrvnCkVa "UNM";
BA_ "VNSigAllNodes" SG_ 192 WRSCD_RDrvnCkVa 1;
BA_ "SignalLongName" SG_ 192 WRSCD_RDrvnCkVa "Wheel Rotational Status Check Data : Right Driven Check Value";
BA_ "PacketOrder" SG_ 192 WRSCD_RDrvnCkVa 6;
BA_ "SignalType" SG_ 192 WRSCD_RDrvnCkVa "UNM";
BA_ "VNSigAllNodes" SG_ 192 WRSCD_LftNDrvnSNm 1;
BA_ "SignalLongName" SG_ 192 WRSCD_LftNDrvnSNm "Wheel Rotational Status Check Data : Left Non Driven Sequence Number";
BA_ "PacketOrder" SG_ 192 WRSCD_LftNDrvnSNm 3;
BA_ "SignalType" SG_ 192 WRSCD_LftNDrvnSNm "UNM";
BA_ "VNSigAllNodes" SG_ 192 WRSCD_LftDrvnSqNm 1;
BA_ "SignalLongName" SG_ 192 WRSCD_LftDrvnSqNm "Wheel Rotational Status Check Data : Left Driven Sequence Number";
BA_ "PacketOrder" SG_ 192 WRSCD_LftDrvnSqNm 1;
BA_ "SignalType" SG_ 192 WRSCD_LftDrvnSqNm "UNM";
BA_ "VNSigAllNodes" SG_ 192 WRSCD_LfNDrvnCkVa 1;
BA_ "SignalLongName" SG_ 192 WRSCD_LfNDrvnCkVa "Wheel Rotational Status Check Data : Left Non Driven Check Value";
BA_ "PacketOrder" SG_ 192 WRSCD_LfNDrvnCkVa 7;
BA_ "SignalType" SG_ 192 WRSCD_LfNDrvnCkVa "UNM";
BA_ "VNSigAllNodes" SG_ 192 WRSCD_LfDrvnCkVa 1;
BA_ "SignalLongName" SG_ 192 WRSCD_LfDrvnCkVa "Wheel Rotational Status Check Data : Left Driven Check Value";
BA_ "PacketOrder" SG_ 192 WRSCD_LfDrvnCkVa 5;
BA_ "SignalType" SG_ 192 WRSCD_LfDrvnCkVa "UNM";
BA_ "GenSigSendType" SG_ 546 ChmNum 10;
BA_ "GenSigSendType_signal" SG_ 546 ChmNum 10;
BA_ "VNSigAllNodes" SG_ 546 ChmNum 1;
BA_ "SignalLongName" SG_ 546 ChmNum "Chime Number";
BA_ "SignalType" SG_ 546 ChmNum "ENM";
BA_ "GenSigSendType" SG_ 546 ChmReq 10;
BA_ "GenSigSendType_signal" SG_ 546 ChmReq 10;
BA_ "VNSigAllNodes" SG_ 546 ChmReq 1;
BA_ "SignalLongName" SG_ 546 ChmReq "Chime Request";
BA_ "SignalType" SG_ 546 ChmReq "BLN";
BA_ "VNSigAllNodes" SG_ 494 TPMTrLrnMdCmplt 1;
BA_ "GenSigSendType" SG_ 494 TPMTrLrnMdCmplt 10;
BA_ "GenSigSendType_signal" SG_ 494 TPMTrLrnMdCmplt 10;
BA_ "SignalLongName" SG_ 494 TPMTrLrnMdCmplt "Tire Pressure Monitoring Tire Learn Mode Complete";
BA_ "SignalType" SG_ 494 TPMTrLrnMdCmplt "ENM";
BA_ "VNSigAllNodes" SG_ 591 DgnInf 1;
BA_ "SignalLongName" SG_ 591 DgnInf "Diagnostic Information";
BA_ "SignalType" SG_ 591 DgnInf "UNM";
BA_ "VNSigSLHSSharedDiagnostic" SG_ 591 DgnInf 1;
BA_ "VNSigAllNodes" SG_ 1615 DgnInf 1;
BA_ "SignalLongName" SG_ 1615 DgnInf "Diagnostic Information";
BA_ "SignalType" SG_ 1615 DgnInf "UNM";
BA_ "VNSigSLHSSharedDiagnostic" SG_ 1615 DgnInf 1;
BA_ "VNSigAllNodes" SG_ 1359 DgnInf_HS54F 1;
BA_ "VNSigSLHSSharedDiagnostic" SG_ 1359 DgnInf_HS54F 1;
BA_ "SignalLongName" SG_ 1359 DgnInf_HS54F "Diagnostic Information HS54F";
BA_ "SignalType" SG_ 1359 DgnInf_HS54F "UNM";
BA_ "VNSigAllNodes" SG_ 773 RHRTirePrs 1;
BA_ "SignalLongName" SG_ 773 RHRTirePrs "RHR Tire Pressure";
BA_ "SignalType" SG_ 773 RHRTirePrs "UNM";
BA_ "VNSigAllNodes" SG_ 773 LHRTirePrs 1;
BA_ "SignalLongName" SG_ 773 LHRTirePrs "LHR Tire Pressure";
BA_ "SignalType" SG_ 773 LHRTirePrs "UNM";
BA_ "VNSigAllNodes" SG_ 773 RHFTirePrs 1;
BA_ "SignalLongName" SG_ 773 RHFTirePrs "RHF Tire Pressure";
BA_ "SignalType" SG_ 773 RHFTirePrs "UNM";
BA_ "VNSigAllNodes" SG_ 773 LHFTirePrs 1;
BA_ "SignalLongName" SG_ 773 LHFTirePrs "LHF Tire Pressure";
BA_ "SignalType" SG_ 773 LHFTirePrs "UNM";
BA_ "VNSigAllNodes" SG_ 773 RHRTirePrsStat 1;
BA_ "SignalLongName" SG_ 773 RHRTirePrsStat "RHR Tire Pressure Status";
BA_ "SignalType" SG_ 773 RHRTirePrsStat "ENM";
BA_ "SignalType" SG_ 773 LHRTirePrsStat "ENM";
BA_ "SignalLongName" SG_ 773 LHRTirePrsStat "LHR Tire Pressure Status";
BA_ "VNSigAllNodes" SG_ 773 LHRTirePrsStat 1;
BA_ "SignalType" SG_ 773 RHFTirePrsStat "ENM";
BA_ "SignalLongName" SG_ 773 RHFTirePrsStat "RHF Tire Pressure Status";
BA_ "VNSigAllNodes" SG_ 773 RHFTirePrsStat 1;
BA_ "SignalType" SG_ 773 LHFTirePrsStat "ENM";
BA_ "SignalLongName" SG_ 773 LHFTirePrsStat "LHF Tire Pressure Status";
BA_ "VNSigAllNodes" SG_ 773 LHFTirePrsStat 1;
BA_ "SignalType" SG_ 773 TireTemp "UNM";
BA_ "SignalLongName" SG_ 773 TireTemp "Tire Temperature";
BA_ "VNSigAllNodes" SG_ 773 TireTemp 1;
BA_ "SignalType" SG_ 773 TirePrsSysFailSts "ENM";
BA_ "SignalLongName" SG_ 773 TirePrsSysFailSts "Tire Pressure System Fail Status";
BA_ "VNSigAllNodes" SG_ 773 TirePrsSysFailSts 1;
BA_ "GenSigSendType_signal" SG_ 773 TirePrsSysFailSts 10;
BA_ "GenSigSendType" SG_ 773 TirePrsSysFailSts 10;
BA_ "VNSigAllNodes" SG_ 773 IDTireTemp 1;
BA_ "SignalLongName" SG_ 773 IDTireTemp "ID Tire Temperature";
BA_ "SignalType" SG_ 773 IDTireTemp "ENM";
BA_ "GenSigSendType" SG_ 1284 IDStudyACK 10;
BA_ "GenSigSendType_signal" SG_ 1284 IDStudyACK 10;
BA_ "VNSigAllNodes" SG_ 1284 IDStudyACK 1;
BA_ "SignalLongName" SG_ 1284 IDStudyACK "ID Study ACK";
BA_ "SignalType" SG_ 1284 IDStudyACK "BLN";
BA_ "GenSigSendType" SG_ 1283 IDStudyReq 10;
BA_ "GenSigSendType_signal" SG_ 1283 IDStudyReq 10;
BA_ "VNSigAllNodes" SG_ 1283 IDStudyReq 1;
BA_ "SignalLongName" SG_ 1283 IDStudyReq "ID Study Request";
BA_ "SignalType" SG_ 1283 IDStudyReq "BLN";
BA_ "VNSigAllNodes" SG_ 519 DrvSelOvSpdWarnActConf 1;
BA_ "SignalLongName" SG_ 519 DrvSelOvSpdWarnActConf "Driver Selected Over Speed Warning Active Confirmation";
BA_ "VNSigAllNodes" SG_ 519 OvSpdChmReq 1;
BA_ "SignalLongName" SG_ 519 OvSpdChmReq "Over Speed Chime Request";
BA_ "VNSigAllNodes" SG_ 533 DrvSelOvSpdEnbl 1;
BA_ "SignalLongName" SG_ 533 DrvSelOvSpdEnbl "Driver Selected Over Speed Enable";
BA_ "VNSigAllNodes" SG_ 533 OvSpdSta 1;
BA_ "SignalLongName" SG_ 533 OvSpdSta "Over Speed Status";
BA_ "GenSigSendType" SG_ 328 StrngAsstRdcdIO 10;
BA_ "GenSigSendType_signal" SG_ 328 StrngAsstRdcdIO 10;
BA_ "VNSigAllNodes" SG_ 328 StrngAsstRdcdIO 1;
BA_ "SignalLongName" SG_ 328 StrngAsstRdcdIO "Steering Assist Reduced Indication On";
BA_ "SignalType" SG_ 328 StrngAsstRdcdIO "BLN";
BA_ "GenSigSendType_signal" SG_ 328 PwrStrIO 10;
BA_ "VNSigAllNodes" SG_ 328 PwrStrIO 1;
BA_ "SignalLongName" SG_ 328 PwrStrIO "Power Steering Indication On";
BA_ "SignalType" SG_ 328 PwrStrIO "BLN";
BA_ "VNSigAllNodes" SG_ 1346 DgnInf 1;
BA_ "SignalLongName" SG_ 1346 DgnInf "Diagnostic Information";
BA_ "SignalType" SG_ 1346 DgnInf "UNM";
BA_ "VNSigSLHSSharedDiagnostic" SG_ 1346 DgnInf 1;
BA_ "VNSigAllNodes" SG_ 1602 DgnInf 1;
BA_ "SignalLongName" SG_ 1602 DgnInf "Diagnostic Information";
BA_ "SignalType" SG_ 1602 DgnInf "UNM";
BA_ "VNSigSLHSSharedDiagnostic" SG_ 1602 DgnInf 1;
BA_ "VNSigAllNodes" SG_ 578 DgnInf 1;
BA_ "SignalLongName" SG_ 578 DgnInf "Diagnostic Information";
BA_ "SignalType" SG_ 578 DgnInf "UNM";
BA_ "VNSigSLHSSharedDiagnostic" SG_ 578 DgnInf 1;
BA_ "GenSigSendType_signal" SG_ 528 ChmVolSt 10;
BA_ "VNSigAllNodes" SG_ 528 ChmVolSt 1;
BA_ "SignalLongName" SG_ 528 ChmVolSt "Chime Volume Status";
BA_ "SignalType" SG_ 528 ChmVolSt "ENM";
BA_ "VNSigAllNodes" SG_ 528 ChmAct 1;
BA_ "SignalLongName" SG_ 528 ChmAct "Chime Active";
BA_ "SignalType" SG_ 528 ChmAct "BLN";
BA_ "GenSigSendOnInit" SG_ 528 ChmAct 1;
BA_ "GenSigSendType_signal" SG_ 517 SC_SndDutCyc 12;
BA_ "GenSigDeltaValue" SG_ 517 SC_SndDutCyc 1;
BA_ "VNSigAllNodes" SG_ 517 SC_SndDutCyc 1;
BA_ "SignalLongName" SG_ 517 SC_SndDutCyc "Sound Characteristics : Sound Duty Cycle";
BA_ "PacketOrder" SG_ 517 SC_SndDutCyc 4;
BA_ "SignalType" SG_ 517 SC_SndDutCyc "UNM";
BA_ "GenSigSendType_signal" SG_ 517 SC_NmofRp 12;
BA_ "GenSigDeltaValue" SG_ 517 SC_NmofRp 1;
BA_ "VNSigAllNodes" SG_ 517 SC_NmofRp 1;
BA_ "SignalLongName" SG_ 517 SC_NmofRp "Sound Characteristics : Number of Repetitions";
BA_ "PacketOrder" SG_ 517 SC_NmofRp 3;
BA_ "SignalType" SG_ 517 SC_NmofRp "UNM";
BA_ "GenSigSendType_signal" SG_ 517 SC_SndCdnPrd 12;
BA_ "GenSigDeltaValue" SG_ 517 SC_SndCdnPrd 1;
BA_ "VNSigAllNodes" SG_ 517 SC_SndCdnPrd 1;
BA_ "SignalLongName" SG_ 517 SC_SndCdnPrd "Sound Characteristics : Sound Cadence Period";
BA_ "PacketOrder" SG_ 517 SC_SndCdnPrd 2;
BA_ "SignalType" SG_ 517 SC_SndCdnPrd "UNM";
BA_ "GenSigSendType_signal" SG_ 517 SC_SndTne 10;
BA_ "VNSigAllNodes" SG_ 517 SC_SndTne 1;
BA_ "SignalLongName" SG_ 517 SC_SndTne "Sound Characteristics : Sound Tone";
BA_ "PacketOrder" SG_ 517 SC_SndTne 1;
BA_ "SignalType" SG_ 517 SC_SndTne "ENM";
BA_ "GenSigSendType_signal" SG_ 517 SndLocRtRr 10;
BA_ "VNSigAllNodes" SG_ 517 SndLocRtRr 1;
BA_ "SignalLongName" SG_ 517 SndLocRtRr "Sound Location : Right Rear";
BA_ "PacketOrder" SG_ 517 SndLocRtRr 4;
BA_ "SignalType" SG_ 517 SndLocRtRr "BLN";
BA_ "GenSigSendType_signal" SG_ 517 SndLocLftRr 10;
BA_ "VNSigAllNodes" SG_ 517 SndLocLftRr 1;
BA_ "SignalLongName" SG_ 517 SndLocLftRr "Sound Location : Left Rear";
BA_ "PacketOrder" SG_ 517 SndLocLftRr 3;
BA_ "SignalType" SG_ 517 SndLocLftRr "BLN";
BA_ "GenSigSendType_signal" SG_ 517 SndLocPasFr 10;
BA_ "VNSigAllNodes" SG_ 517 SndLocPasFr 1;
BA_ "SignalLongName" SG_ 517 SndLocPasFr "Sound Location : Passenger Front";
BA_ "PacketOrder" SG_ 517 SndLocPasFr 2;
BA_ "SignalType" SG_ 517 SndLocPasFr "BLN";
BA_ "GenSigSendType_signal" SG_ 517 SndLocDrFr 10;
BA_ "VNSigAllNodes" SG_ 517 SndLocDrFr 1;
BA_ "SignalLongName" SG_ 517 SndLocDrFr "Sound Location : Driver Front";
BA_ "PacketOrder" SG_ 517 SndLocDrFr 1;
BA_ "SignalType" SG_ 517 SndLocDrFr "BLN";
BA_ "GenSigSendType_signal" SG_ 517 SndPriority 12;
BA_ "GenSigDeltaValue" SG_ 517 SndPriority 1;
BA_ "VNSigAllNodes" SG_ 517 SndPriority 1;
BA_ "SignalLongName" SG_ 517 SndPriority "Sound Priority";
BA_ "SignalType" SG_ 517 SndPriority "UNM";
BA_ "VNSigAllNodes" SG_ 1612 DgnInf 1;
BA_ "SignalLongName" SG_ 1612 DgnInf "Diagnostic Information";
BA_ "SignalType" SG_ 1612 DgnInf "UNM";
BA_ "VNSigSLHSSharedDiagnostic" SG_ 1612 DgnInf 1;
BA_ "VNSigAllNodes" SG_ 401 EngTrqTrnRqTmpFld 1;
BA_ "SignalLongName" SG_ 401 EngTrqTrnRqTmpFld "Engine Torque Transmission Request Temporarily Failed";
BA_ "SignalType" SG_ 401 EngTrqTrnRqTmpFld "BLN";
BA_ "VNSigAllNodes" SG_ 401 EngTrqTrnRqLmtd 1;
BA_ "SignalLongName" SG_ 401 EngTrqTrnRqLmtd "Engine Torque Transmission Request Limited";
BA_ "SignalType" SG_ 401 EngTrqTrnRqLmtd "BLN";
BA_ "VNSigAllNodes" SG_ 401 TrnsEngSpdReqFld 1;
BA_ "SignalLongName" SG_ 401 TrnsEngSpdReqFld "Transmission Engine Speed Request Failed";
BA_ "SignalType" SG_ 401 TrnsEngSpdReqFld "BLN";
BA_ "VNSigAllNodes" SG_ 401 ThrtCommndPos 1;
BA_ "SignalLongName" SG_ 401 ThrtCommndPos "Throttle Commanded Position";
BA_ "SignalType" SG_ 401 ThrtCommndPos "UNM";
BA_ "VNSigAllNodes" SG_ 401 EngTrqTnsRqFld 1;
BA_ "SignalLongName" SG_ 401 EngTrqTnsRqFld "Engine Torque Transmission Request Failed";
BA_ "SignalType" SG_ 401 EngTrqTnsRqFld "BLN";
BA_ "VNSigAllNodes" SG_ 401 EngTrqRdnFld 1;
BA_ "SignalLongName" SG_ 401 EngTrqRdnFld "Engine Torque Reduction Failed";
BA_ "SignalType" SG_ 401 EngTrqRdnFld "BLN";
BA_ "VNSigAllNodes" SG_ 401 EngNTrnsRegStdyStTqV 1;
BA_ "SignalLongName" SG_ 401 EngNTrnsRegStdyStTqV "Engine Non-Transmission Regulated Steady State Torque Validity";
BA_ "SignalType" SG_ 401 EngNTrnsRegStdyStTqV "ENM";
BA_ "VNSigAllNodes" SG_ 401 EngNTrnsRegStdyStTq 1;
BA_ "SignalLongName" SG_ 401 EngNTrnsRegStdyStTq "Engine Non-Transmission Regulated Steady State Torque";
BA_ "SignalType" SG_ 401 EngNTrnsRegStdyStTq "UNM";
BA_ "VNSigAllNodes" SG_ 401 EngAirflwStdyStTorqV 1;
BA_ "SignalLongName" SG_ 401 EngAirflwStdyStTorqV "Engine Airflow Steady State Torque Validity";
BA_ "SignalType" SG_ 401 EngAirflwStdyStTorqV "ENM";
BA_ "VNSigAllNodes" SG_ 401 EngAirflwStdyStTorq 1;
BA_ "SignalLongName" SG_ 401 EngAirflwStdyStTorq "Engine Airflow Steady State Torque";
BA_ "SignalType" SG_ 401 EngAirflwStdyStTorq "UNM";
BA_ "VNSigAllNodes" SG_ 401 AccKdwnAtv 1;
BA_ "SignalLongName" SG_ 401 AccKdwnAtv "Accelerator Kick Down Detected";
BA_ "SignalType" SG_ 401 AccKdwnAtv "BLN";
BA_ "VNSigAllNodes" SG_ 401 AccPosV 1;
BA_ "SignalLongName" SG_ 401 AccPosV "Accelerator Effective Position Validity";
BA_ "SignalType" SG_ 401 AccPosV "ENM";
BA_ "VNSigAllNodes" SG_ 401 AccPos 1;
BA_ "SignalLongName" SG_ 401 AccPos "Accelerator Effective Position";
BA_ "SignalType" SG_ 401 AccPos "UNM";
BA_ "VNSigAllNodes" SG_ 401 EngActStdyStTorqV 1;
BA_ "SignalLongName" SG_ 401 EngActStdyStTorqV "Engine Actual Steady State Torque Validity";
BA_ "SignalType" SG_ 401 EngActStdyStTorqV "ENM";
BA_ "VNSigAllNodes" SG_ 401 EngActStdyStTorq 1;
BA_ "SignalLongName" SG_ 401 EngActStdyStTorq "Engine Actual Steady State Torque";
BA_ "SignalType" SG_ 401 EngActStdyStTorq "UNM";
BA_ "VNSigAllNodes" SG_ 1265 EngOffTmPT 1;
BA_ "SignalLongName" SG_ 1265 EngOffTmPT "Engine Off Time Powertrain";
BA_ "SignalType" SG_ 1265 EngOffTmPT "UNM";
BA_ "VNSigAllNodes" SG_ 1265 EngOffTmPTV 1;
BA_ "SignalLongName" SG_ 1265 EngOffTmPTV "Engine Off Time Powertrain Validity";
BA_ "SignalType" SG_ 1265 EngOffTmPTV "ENM";
BA_ "VNSigAllNodes" SG_ 1265 EngOffTmPTM 1;
BA_ "SignalLongName" SG_ 1265 EngOffTmPTM "Engine Off Time Powertrain Mask";
BA_ "SignalType" SG_ 1265 EngOffTmPTM "ENM";
BA_ "VNSigAllNodes" SG_ 1265 WhlDistPrRevNDrvn 1;
BA_ "SignalLongName" SG_ 1265 WhlDistPrRevNDrvn "Wheel Distance Per Revolution Non Driven";
BA_ "SignalType" SG_ 1265 WhlDistPrRevNDrvn "UNM";
BA_ "VNSigAllNodes" SG_ 1265 WhlDistPrRevDrvn 1;
BA_ "SignalLongName" SG_ 1265 WhlDistPrRevDrvn "Wheel Distance Per Revolution Driven";
BA_ "SignalType" SG_ 1265 WhlDistPrRevDrvn "UNM";
BA_ "VNSigAllNodes" SG_ 1265 DrvlnFnlAxleRatio 1;
BA_ "SignalLongName" SG_ 1265 DrvlnFnlAxleRatio "Driveline Final Axle Ratio";
BA_ "SignalType" SG_ 1265 DrvlnFnlAxleRatio "UNM";
BA_ "VNSigAllNodes" SG_ 417 EngRunng 1;
BA_ "SignalLongName" SG_ 417 EngRunng "Engine Running";
BA_ "SignalType" SG_ 417 EngRunng "BLN";
BA_ "VNSigAllNodes" SG_ 417 EngCrsCntrlMode 1;
BA_ "SignalLongName" SG_ 417 EngCrsCntrlMode "Engine Cruise Control Mode";
BA_ "SignalType" SG_ 417 EngCrsCntrlMode "ENM";
BA_ "VNSigAllNodes" SG_ 417 EngPstOxgSnsDgAstRq 1;
BA_ "SignalLongName" SG_ 417 EngPstOxgSnsDgAstRq "Engine Post Oxygen Sensor Diagnostic Assistance Requested";
BA_ "SignalType" SG_ 417 EngPstOxgSnsDgAstRq "BLN";
BA_ "VNSigAllNodes" SG_ 417 CrsCtrlCnstSpdAct 1;
BA_ "SignalLongName" SG_ 417 CrsCtrlCnstSpdAct "Cruise Control Constant Speed Active";
BA_ "SignalType" SG_ 417 CrsCtrlCnstSpdAct "BLN";
BA_ "VNSigAllNodes" SG_ 417 WrmUpShftPtrnRq 1;
BA_ "SignalLongName" SG_ 417 WrmUpShftPtrnRq "Warm Up Shift Pattern Request";
BA_ "SignalType" SG_ 417 WrmUpShftPtrnRq "ENM";
BA_ "VNSigAllNodes" SG_ 417 EngIdlSpdRdcdRng 1;
BA_ "SignalLongName" SG_ 417 EngIdlSpdRdcdRng "Engine Idle Speed Reduced Range";
BA_ "SignalType" SG_ 417 EngIdlSpdRdcdRng "UNM";
BA_ "VNSigAllNodes" SG_ 417 EngCntrlRunCrnkTrmSt 1;
BA_ "SignalLongName" SG_ 417 EngCntrlRunCrnkTrmSt "Engine Controller Run Crank Terminal Status";
BA_ "SignalType" SG_ 417 EngCntrlRunCrnkTrmSt "ENM";
BA_ "VNSigAllNodes" SG_ 417 EngAlwCltAdp 1;
BA_ "SignalLongName" SG_ 417 EngAlwCltAdp "Engine Allowed Clutch Adaptation";
BA_ "SignalType" SG_ 417 EngAlwCltAdp "BLN";
BA_ "VNSigAllNodes" SG_ 417 BsTrgtEngIdlSpd 1;
BA_ "SignalLongName" SG_ 417 BsTrgtEngIdlSpd "Base Target Engine Idle Speed";
BA_ "SignalType" SG_ 417 BsTrgtEngIdlSpd "UNM";
BA_ "VNSigAllNodes" SG_ 417 AccPdlPosPcntFullRngV 1;
BA_ "SignalLongName" SG_ 417 AccPdlPosPcntFullRngV "Accelerator Pedal Position Percent Full Range  Validity";
BA_ "SignalType" SG_ 417 AccPdlPosPcntFullRngV "ENM";
BA_ "VNSigAllNodes" SG_ 417 AccPdlPosPcntFullRng 1;
BA_ "SignalLongName" SG_ 417 AccPdlPosPcntFullRng "Accelerator Pedal Position Percent Full Range";
BA_ "SignalType" SG_ 417 AccPdlPosPcntFullRng "UNM";
BA_ "VNSigAllNodes" SG_ 417 DslPrtFltrIdlRgtnMdReq 1;
BA_ "SignalLongName" SG_ 417 DslPrtFltrIdlRgtnMdReq "Diesel Particulate Filter Idle Regeneration Mode Request";
BA_ "SignalType" SG_ 417 DslPrtFltrIdlRgtnMdReq "BLN";
BA_ "VNSigAllNodes" SG_ 417 DslPartFltrClngAlgActM 1;
BA_ "SignalLongName" SG_ 417 DslPartFltrClngAlgActM "Diesel Particle Filter Cleaning Algorithm Active Mask";
BA_ "SignalType" SG_ 417 DslPartFltrClngAlgActM "ENM";
BA_ "VNSigAllNodes" SG_ 417 DslPartFltrClngAlgAct 1;
BA_ "SignalLongName" SG_ 417 DslPartFltrClngAlgAct "Diesel Particle Filter Cleaning Algorithm Active";
BA_ "SignalType" SG_ 417 DslPartFltrClngAlgAct "BLN";
BA_ "VNSigAllNodes" SG_ 417 EngCylDeactMd 1;
BA_ "SignalLongName" SG_ 417 EngCylDeactMd "Engine Cylinder Deactivation Mode";
BA_ "SignalType" SG_ 417 EngCylDeactMd "ENM";
BA_ "VNSigAllNodes" SG_ 417 ACCmCltEngd 1;
BA_ "SignalLongName" SG_ 417 ACCmCltEngd "Air Conditioning Compressor Clutch Engaged";
BA_ "SignalType" SG_ 417 ACCmCltEngd "BLN";
BA_ "VNSigAllNodes" SG_ 417 ParkNeutralSwStatV 1;
BA_ "SignalLongName" SG_ 417 ParkNeutralSwStatV "Park Neutral Switch Status Validity";
BA_ "SignalType" SG_ 417 ParkNeutralSwStatV "ENM";
BA_ "VNSigAllNodes" SG_ 417 ParkNeutralSwStat 1;
BA_ "SignalLongName" SG_ 417 ParkNeutralSwStat "Park Neutral Switch Status";
BA_ "SignalType" SG_ 417 ParkNeutralSwStat "ENM";
BA_ "VNSigAllNodes" SG_ 417 EngColdHiIdleActive 1;
BA_ "SignalLongName" SG_ 417 EngColdHiIdleActive "Engine Cold High Idle Active";
BA_ "SignalType" SG_ 417 EngColdHiIdleActive "BLN";
BA_ "VNSigAllNodes" SG_ 417 EngCyDactTqSmtAct 1;
BA_ "SignalLongName" SG_ 417 EngCyDactTqSmtAct "Engine Cylinder Deactivation Torque Smoothing Active";
BA_ "SignalType" SG_ 417 EngCyDactTqSmtAct "BLN";
BA_ "VNSigAllNodes" SG_ 417 EngBrkStat 1;
BA_ "SignalLongName" SG_ 417 EngBrkStat "Engine Brake Status";
BA_ "SignalType" SG_ 417 EngBrkStat "ENM";
BA_ "VNSigAllNodes" SG_ 417 TracCntlSysPwrtrnInhbt 1;
BA_ "SignalLongName" SG_ 417 TracCntlSysPwrtrnInhbt "Traction Control System Powertrain Inhibit";
BA_ "SignalType" SG_ 417 TracCntlSysPwrtrnInhbt "BLN";
BA_ "VNSigAllNodes" SG_ 417 EngMtlProtAtv 1;
BA_ "SignalLongName" SG_ 417 EngMtlProtAtv "Engine Metal Protection Active";
BA_ "SignalType" SG_ 417 EngMtlProtAtv "BLN";
BA_ "VNSigAllNodes" SG_ 417 EngDgTrqCnvClUnlkRqd 1;
BA_ "SignalLongName" SG_ 417 EngDgTrqCnvClUnlkRqd "Engine Diagnostic Torque Converter Clutch Unlock Requested";
BA_ "SignalType" SG_ 417 EngDgTrqCnvClUnlkRqd "BLN";
BA_ "VNSigAllNodes" SG_ 417 EngCyldrDeactReqd 1;
BA_ "SignalLongName" SG_ 417 EngCyldrDeactReqd "Engine Cylinder Deactivation Requested";
BA_ "SignalType" SG_ 417 EngCyldrDeactReqd "BLN";
BA_ "VNSigAllNodes" SG_ 417 ETGRReqdGear 1;
BA_ "SignalLongName" SG_ 417 ETGRReqdGear "Engine Transmission Gear Request : Requested Gear";
BA_ "PacketOrder" SG_ 417 ETGRReqdGear 2;
BA_ "SignalType" SG_ 417 ETGRReqdGear "ENM";
BA_ "VNSigAllNodes" SG_ 417 ETGRReqType 1;
BA_ "SignalLongName" SG_ 417 ETGRReqType "Engine Transmission Gear Request : Request Type";
BA_ "PacketOrder" SG_ 417 ETGRReqType 1;
BA_ "SignalType" SG_ 417 ETGRReqType "ENM";
BA_ "VNSigAllNodes" SG_ 1233 EngShtdwnAct 1;
BA_ "SignalLongName" SG_ 1233 EngShtdwnAct "Engine Shutdown Active";
BA_ "SignalType" SG_ 1233 EngShtdwnAct "BLN";
BA_ "VNSigAllNodes" SG_ 1233 EngShtdwnPndgIO 1;
BA_ "SignalLongName" SG_ 1233 EngShtdwnPndgIO "Engine Shutdown Pending Indication On";
BA_ "SignalType" SG_ 1233 EngShtdwnPndgIO "BLN";
BA_ "VNSigAllNodes" SG_ 1233 FuelFltChgNwIO 1;
BA_ "SignalLongName" SG_ 1233 FuelFltChgNwIO "Fuel Filter Change Now Indication On";
BA_ "SignalType" SG_ 1233 FuelFltChgNwIO "BLN";
BA_ "VNSigAllNodes" SG_ 1233 PTExPrtclFltrWrn2IO 1;
BA_ "SignalLongName" SG_ 1233 PTExPrtclFltrWrn2IO "Powertrain Exhaust Particle Filter Warning 2 Indication On";
BA_ "SignalType" SG_ 1233 PTExPrtclFltrWrn2IO "BLN";
BA_ "VNSigAllNodes" SG_ 1233 PTHiElecLdReqd 1;
BA_ "SignalLongName" SG_ 1233 PTHiElecLdReqd "Powertrain High Electrical Load Requested";
BA_ "SignalType" SG_ 1233 PTHiElecLdReqd "BLN";
BA_ "VNSigAllNodes" SG_ 1233 PTExPrtclFltrWrnIO 1;
BA_ "SignalLongName" SG_ 1233 PTExPrtclFltrWrnIO "Powertrain Exhaust Particle Filter Warning Indication On";
BA_ "SignalType" SG_ 1233 PTExPrtclFltrWrnIO "BLN";
BA_ "VNSigAllNodes" SG_ 1233 AirCndOffIO 1;
BA_ "SignalLongName" SG_ 1233 AirCndOffIO "Air Conditioning Off Indication On";
BA_ "SignalType" SG_ 1233 AirCndOffIO "BLN";
BA_ "VNSigAllNodes" SG_ 1233 EngSpdMaxLmt 1;
BA_ "SignalLongName" SG_ 1233 EngSpdMaxLmt "Engine Speed Maximum Limit";
BA_ "SignalType" SG_ 1233 EngSpdMaxLmt "UNM";
BA_ "VNSigAllNodes" SG_ 1233 DslGlwPlgIO 1;
BA_ "SignalLongName" SG_ 1233 DslGlwPlgIO "Diesel Glow Plug Indication On";
BA_ "SignalType" SG_ 1233 DslGlwPlgIO "BLN";
BA_ "VNSigAllNodes" SG_ 1233 StgDisIO 1;
BA_ "SignalLongName" SG_ 1233 StgDisIO "Starting Disabled Indication On";
BA_ "SignalType" SG_ 1233 StgDisIO "BLN";
BA_ "VNSigAllNodes" SG_ 1233 RdcdPwrIO 1;
BA_ "SignalLongName" SG_ 1233 RdcdPwrIO "Reduced Power Indication On";
BA_ "SignalType" SG_ 1233 RdcdPwrIO "BLN";
BA_ "VNSigAllNodes" SG_ 1233 FuelTotCap 1;
BA_ "SignalLongName" SG_ 1233 FuelTotCap "Fuel Total Capacity";
BA_ "SignalType" SG_ 1233 FuelTotCap "UNM";
BA_ "VNSigAllNodes" SG_ 1233 FlLvlPctV 1;
BA_ "SignalLongName" SG_ 1233 FlLvlPctV "Fuel Level Percent Validity";
BA_ "SignalType" SG_ 1233 FlLvlPctV "ENM";
BA_ "VNSigAllNodes" SG_ 1233 FlLvlPct 1;
BA_ "SignalLongName" SG_ 1233 FlLvlPct "Fuel Level Percent";
BA_ "SignalType" SG_ 1233 FlLvlPct "UNM";
BA_ "VNSigAllNodes" SG_ 1233 EngWtrInFlIO 1;
BA_ "SignalLongName" SG_ 1233 EngWtrInFlIO "Engine Water In Fuel Indication On";
BA_ "SignalType" SG_ 1233 EngWtrInFlIO "BLN";
BA_ "VNSigAllNodes" SG_ 1233 EngOilTmpV 1;
BA_ "SignalLongName" SG_ 1233 EngOilTmpV "Engine Oil Temperature Validity";
BA_ "SignalType" SG_ 1233 EngOilTmpV "ENM";
BA_ "VNSigAllNodes" SG_ 1233 EngOilTmp 1;
BA_ "SignalLongName" SG_ 1233 EngOilTmp "Engine Oil Temperature";
BA_ "SignalType" SG_ 1233 EngOilTmp "UNM";
BA_ "VNSigAllNodes" SG_ 1233 EngOilPrsV 1;
BA_ "SignalLongName" SG_ 1233 EngOilPrsV "Engine Oil Pressure Validity";
BA_ "SignalType" SG_ 1233 EngOilPrsV "ENM";
BA_ "VNSigAllNodes" SG_ 1233 EngOilPrsLwIO 1;
BA_ "SignalLongName" SG_ 1233 EngOilPrsLwIO "Engine Oil Pressure Low Indication On";
BA_ "SignalType" SG_ 1233 EngOilPrsLwIO "BLN";
BA_ "VNSigAllNodes" SG_ 1233 EngOilPrs 1;
BA_ "SignalLongName" SG_ 1233 EngOilPrs "Engine Oil Pressure";
BA_ "SignalType" SG_ 1233 EngOilPrs "UNM";
BA_ "VNSigAllNodes" SG_ 1233 EngOilLvlLwIO 1;
BA_ "SignalLongName" SG_ 1233 EngOilLvlLwIO "Engine Oil Level Low Indication On";
BA_ "SignalType" SG_ 1233 EngOilLvlLwIO "BLN";
BA_ "VNSigAllNodes" SG_ 1233 EngOilChngIO 1;
BA_ "SignalLongName" SG_ 1233 EngOilChngIO "Engine Oil Change Indication On";
BA_ "SignalType" SG_ 1233 EngOilChngIO "BLN";
BA_ "VNSigAllNodes" SG_ 1233 EngHt_StpEngIO 1;
BA_ "SignalLongName" SG_ 1233 EngHt_StpEngIO "Engine Hot / Stop Engine Indication On";
BA_ "SignalType" SG_ 1233 EngHt_StpEngIO "BLN";
BA_ "VNSigAllNodes" SG_ 1233 EngHotFuelEnrchmntIO 1;
BA_ "SignalLongName" SG_ 1233 EngHotFuelEnrchmntIO "Engine Hot Fuel Enrichment Indication On";
BA_ "SignalType" SG_ 1233 EngHotFuelEnrchmntIO "BLN";
BA_ "VNSigAllNodes" SG_ 1233 CkFlFilrCapIO 1;
BA_ "SignalLongName" SG_ 1233 CkFlFilrCapIO "Check Fuel Filler Cap Indication On";
BA_ "SignalType" SG_ 1233 CkFlFilrCapIO "BLN";
BA_ "VNSigAllNodes" SG_ 1217 LegPstDTCClrDrvCyCm 1;
BA_ "SignalLongName" SG_ 1217 LegPstDTCClrDrvCyCm "Legislated Post DTC Clear Drive Cycle Complete";
BA_ "SignalType" SG_ 1217 LegPstDTCClrDrvCyCm "BLN";
BA_ "VNSigAllNodes" SG_ 1217 LegDiagColdStCndMet 1;
BA_ "SignalLongName" SG_ 1217 LegDiagColdStCndMet "Legislated Diagnostics Cold Start Conditions Met";
BA_ "SignalType" SG_ 1217 LegDiagColdStCndMet "BLN";
BA_ "VNSigAllNodes" SG_ 1217 LegDiagColdStCndFltPr 1;
BA_ "SignalLongName" SG_ 1217 LegDiagColdStCndFltPr "Legislated Diagnostics Cold Start Conditions Fault Present";
BA_ "SignalType" SG_ 1217 LegDiagColdStCndFltPr "BLN";
BA_ "VNSigAllNodes" SG_ 1217 EngEconMdCmnd 1;
BA_ "SignalLongName" SG_ 1217 EngEconMdCmnd "Engine Economy Mode Commanded";
BA_ "SignalType" SG_ 1217 EngEconMdCmnd "BLN";
BA_ "VNSigAllNodes" SG_ 1217 EngOilHotIO 1;
BA_ "SignalLongName" SG_ 1217 EngOilHotIO "Engine Oil Hot Indication On";
BA_ "SignalType" SG_ 1217 EngOilHotIO "BLN";
BA_ "VNSigAllNodes" SG_ 1217 DslExhFldWrngIndRq 1;
BA_ "SignalLongName" SG_ 1217 DslExhFldWrngIndRq "Diesel Exhaust Fluid Warning Indication Request";
BA_ "SignalType" SG_ 1217 DslExhFldWrngIndRq "ENM";
BA_ "VNSigAllNodes" SG_ 1217 DslExhFldRmngDstV 1;
BA_ "SignalLongName" SG_ 1217 DslExhFldRmngDstV "Diesel Exhaust Fluid Remaining Distance Validity";
BA_ "SignalType" SG_ 1217 DslExhFldRmngDstV "ENM";
BA_ "VNSigAllNodes" SG_ 1217 DslExhFldRmngDst 1;
BA_ "SignalLongName" SG_ 1217 DslExhFldRmngDst "Diesel Exhaust Fluid Remaining Distance";
BA_ "SignalType" SG_ 1217 DslExhFldRmngDst "UNM";
BA_ "VNSigAllNodes" SG_ 1217 OAT_PT_EstV 1;
BA_ "SignalLongName" SG_ 1217 OAT_PT_EstV "Outside Air Temperature Powertrain Estimated Validity";
BA_ "SignalType" SG_ 1217 OAT_PT_EstV "ENM";
BA_ "VNSigAllNodes" SG_ 1217 LegDiagStndCndMet 1;
BA_ "SignalLongName" SG_ 1217 LegDiagStndCndMet "Legislated Diagnostics Standard Conditions Met";
BA_ "SignalType" SG_ 1217 LegDiagStndCndMet "BLN";
BA_ "VNSigAllNodes" SG_ 1217 LegDiagStndCndFltPr 1;
BA_ "SignalLongName" SG_ 1217 LegDiagStndCndFltPr "Legislated Diagnostics Standard Conditions Fault Present";
BA_ "SignalType" SG_ 1217 LegDiagStndCndFltPr "BLN";
BA_ "VNSigAllNodes" SG_ 1217 OAT_PT_EstM 1;
BA_ "SignalLongName" SG_ 1217 OAT_PT_EstM "Outside Air Temperature Powertrain Estimated Mask";
BA_ "SignalType" SG_ 1217 OAT_PT_EstM "ENM";
BA_ "VNSigAllNodes" SG_ 1217 OAT_PT_Est 1;
BA_ "SignalLongName" SG_ 1217 OAT_PT_Est "Outside Air Temperature Powertrain Estimated";
BA_ "SignalType" SG_ 1217 OAT_PT_Est "UNM";
BA_ "VNSigAllNodes" SG_ 1217 EngWrmUpAch 1;
BA_ "SignalLongName" SG_ 1217 EngWrmUpAch "Engine Warm Up Cycle Achieved";
BA_ "SignalType" SG_ 1217 EngWrmUpAch "BLN";
BA_ "VNSigAllNodes" SG_ 1217 EngIntAirTmpV 1;
BA_ "SignalLongName" SG_ 1217 EngIntAirTmpV "Engine Intake Air Temperature Validity";
BA_ "SignalType" SG_ 1217 EngIntAirTmpV "ENM";
BA_ "VNSigAllNodes" SG_ 1217 EngIntAirTmp 1;
BA_ "SignalLongName" SG_ 1217 EngIntAirTmp "Engine Intake Air Temperature";
BA_ "SignalType" SG_ 1217 EngIntAirTmp "UNM";
BA_ "VNSigAllNodes" SG_ 1217 EngCltTmpV 1;
BA_ "SignalLongName" SG_ 1217 EngCltTmpV "Engine Coolant Temperature Validity";
BA_ "SignalType" SG_ 1217 EngCltTmpV "ENM";
BA_ "VNSigAllNodes" SG_ 1217 EngCltTmp 1;
BA_ "SignalLongName" SG_ 1217 EngCltTmp "Engine Coolant Temperature";
BA_ "SignalType" SG_ 1217 EngCltTmp "UNM";
BA_ "VNSigAllNodes" SG_ 1217 BarPrsAbsV 1;
BA_ "SignalLongName" SG_ 1217 BarPrsAbsV "Barometric Pressure Absolute Validity";
BA_ "SignalType" SG_ 1217 BarPrsAbsV "ENM";
BA_ "VNSigAllNodes" SG_ 1217 BarPrsAbs 1;
BA_ "SignalLongName" SG_ 1217 BarPrsAbs "Barometric Pressure Absolute";
BA_ "SignalType" SG_ 1217 BarPrsAbs "UNM";
BA_ "VNSigAllNodes" SG_ 1017 ACRfHiSdFldPrsV 1;
BA_ "SignalLongName" SG_ 1017 ACRfHiSdFldPrsV "Air Conditioning Refrigerant High Side Fluid Pressure Validity";
BA_ "SignalType" SG_ 1017 ACRfHiSdFldPrsV "ENM";
BA_ "VNSigAllNodes" SG_ 1017 ACRfHiSdFldPrs 1;
BA_ "SignalLongName" SG_ 1017 ACRfHiSdFldPrs "Air Conditioning Refrigerant High Side Fluid Pressure";
BA_ "SignalType" SG_ 1017 ACRfHiSdFldPrs "UNM";
BA_ "VNSigAllNodes" SG_ 1017 GenStptDtCycPtOvrAct 1;
BA_ "SignalLongName" SG_ 1017 GenStptDtCycPtOvrAct "Generator Setpoint Duty Cycle Powertrain Override Active";
BA_ "SignalType" SG_ 1017 GenStptDtCycPtOvrAct "BLN";
BA_ "VNSigAllNodes" SG_ 1017 VehTopSpdLmtMdAct 1;
BA_ "SignalLongName" SG_ 1017 VehTopSpdLmtMdAct "Vehicle Top Speed Limit Mode Active";
BA_ "SignalType" SG_ 1017 VehTopSpdLmtMdAct "BLN";
BA_ "VNSigAllNodes" SG_ 1017 VehTopSpdLmtArbVal 1;
BA_ "SignalLongName" SG_ 1017 VehTopSpdLmtArbVal "Vehicle Top Speed Limit Arbitrated Value";
BA_ "SignalType" SG_ 1017 VehTopSpdLmtArbVal "UNM";
BA_ "VNSigAllNodes" SG_ 1017 PT_TopSpdLmtRdcd 1;
BA_ "SignalLongName" SG_ 1017 PT_TopSpdLmtRdcd "Powertrain Top Speed Limit Reduced";
BA_ "SignalType" SG_ 1017 PT_TopSpdLmtRdcd "BLN";
BA_ "VNSigAllNodes" SG_ 1017 GenFldDutCycV 1;
BA_ "SignalLongName" SG_ 1017 GenFldDutCycV "Generator Field Duty Cycle Validity";
BA_ "SignalType" SG_ 1017 GenFldDutCycV "ENM";
BA_ "VNSigAllNodes" SG_ 1017 GenFldDutCyc 1;
BA_ "SignalLongName" SG_ 1017 GenFldDutCyc "Generator Field Duty Cycle";
BA_ "SignalType" SG_ 1017 GenFldDutCyc "UNM";
BA_ "VNSigAllNodes" SG_ 1017 GenFld 1;
BA_ "SignalLongName" SG_ 1017 GenFld "Generator Failed";
BA_ "SignalType" SG_ 1017 GenFld "BLN";
BA_ "VNSigAllNodes" SG_ 1017 FlInjRlCtRstOcc 1;
BA_ "SignalLongName" SG_ 1017 FlInjRlCtRstOcc "Fuel Injected Rolling Count Reset Occurred";
BA_ "SignalType" SG_ 1017 FlInjRlCtRstOcc "BLN";
BA_ "VNSigAllNodes" SG_ 1017 FlInjRlCt 1;
BA_ "SignalLongName" SG_ 1017 FlInjRlCt "Fuel Injected Rolling Count";
BA_ "SignalType" SG_ 1017 FlInjRlCt "UNM";
BA_ "VNSigAllNodes" SG_ 1017 EngSpdLmtnMdAct 1;
BA_ "SignalLongName" SG_ 1017 EngSpdLmtnMdAct "Engine Speed Limitation Mode Active";
BA_ "SignalType" SG_ 1017 EngSpdLmtnMdAct "BLN";
BA_ "VNSigAllNodes" SG_ 1017 EngOilRmnLf 1;
BA_ "SignalLongName" SG_ 1017 EngOilRmnLf "Engine Oil Remaining Life";
BA_ "SignalType" SG_ 1017 EngOilRmnLf "UNM";
BA_ "VNSigAllNodes" SG_ 1017 EngCoolFanSpd 1;
BA_ "SignalLongName" SG_ 1017 EngCoolFanSpd "Engine Cooling Fan Speed";
BA_ "SignalType" SG_ 1017 EngCoolFanSpd "UNM";
BA_ "VNSigAllNodes" SG_ 977 FuelFltLifRstPerf 1;
BA_ "SignalLongName" SG_ 977 FuelFltLifRstPerf "Fuel Filter Life Reset Performed";
BA_ "SignalType" SG_ 977 FuelFltLifRstPerf "BLN";
BA_ "VNSigAllNodes" SG_ 977 CrsCntlDrSelSpdAct 1;
BA_ "SignalLongName" SG_ 977 CrsCntlDrSelSpdAct "Cruise Control Driver Selected Speed Active";
BA_ "SignalType" SG_ 977 CrsCntlDrSelSpdAct "BLN";
BA_ "VNSigAllNodes" SG_ 977 ACCmpNrmLdGrdAld 1;
BA_ "SignalLongName" SG_ 977 ACCmpNrmLdGrdAld "Air Conditioning Compressor Normalized Load Gradient Allowed";
BA_ "SignalType" SG_ 977 ACCmpNrmLdGrdAld "UNM";
BA_ "VNSigAllNodes" SG_ 977 ACCompCmnd 1;
BA_ "SignalLongName" SG_ 977 ACCompCmnd "Air Conditioning Compressor Command";
BA_ "SignalType" SG_ 977 ACCompCmnd "ENM";
BA_ "VNSigAllNodes" SG_ 977 EngBstPrsIndV 1;
BA_ "SignalLongName" SG_ 977 EngBstPrsIndV "Engine Boost Pressure Indication Validity";
BA_ "SignalType" SG_ 977 EngBstPrsIndV "ENM";
BA_ "VNSigAllNodes" SG_ 977 EngBstPrsInd 1;
BA_ "SignalLongName" SG_ 977 EngBstPrsInd "Engine Boost Pressure Indication";
BA_ "SignalType" SG_ 977 EngBstPrsInd "UNM";
BA_ "VNSigAllNodes" SG_ 977 EngOilLifRstPerf 1;
BA_ "SignalLongName" SG_ 977 EngOilLifRstPerf "Engine Oil Life Reset Performed";
BA_ "SignalType" SG_ 977 EngOilLifRstPerf "BLN";
BA_ "VNSigAllNodes" SG_ 977 ThrtlPrgrsnStat 1;
BA_ "SignalLongName" SG_ 977 ThrtlPrgrsnStat "Throttle Progression Status";
BA_ "SignalType" SG_ 977 ThrtlPrgrsnStat "ENM";
BA_ "VNSigAllNodes" SG_ 977 ThrPosV 1;
BA_ "SignalLongName" SG_ 977 ThrPosV "Throttle Position Validity";
BA_ "SignalType" SG_ 977 ThrPosV "ENM";
BA_ "VNSigAllNodes" SG_ 977 ThrPos 1;
BA_ "SignalLongName" SG_ 977 ThrPos "Throttle Position";
BA_ "SignalType" SG_ 977 ThrPos "UNM";
BA_ "VNSigAllNodes" SG_ 977 InstFuelConsmpRate 1;
BA_ "SignalLongName" SG_ 977 InstFuelConsmpRate "Instantaneous Fuel Consumption Rate";
BA_ "SignalType" SG_ 977 InstFuelConsmpRate "UNM";
BA_ "VNSigAllNodes" SG_ 977 EngOilStrvtnIO 1;
BA_ "SignalLongName" SG_ 977 EngOilStrvtnIO "Engine Oil Starvation Indication On";
BA_ "SignalType" SG_ 977 EngOilStrvtnIO "BLN";
BA_ "VNSigAllNodes" SG_ 977 EngNEmsnsRelMalfAct 1;
BA_ "SignalLongName" SG_ 977 EngNEmsnsRelMalfAct "Engine Non Emissions Related Malfunction Active";
BA_ "SignalType" SG_ 977 EngNEmsnsRelMalfAct "BLN";
BA_ "VNSigAllNodes" SG_ 977 EngEmsRelMalfIndReq 1;
BA_ "SignalLongName" SG_ 977 EngEmsRelMalfIndReq "Engine Emissions Related Malfunction Indication Request";
BA_ "SignalType" SG_ 977 EngEmsRelMalfIndReq "ENM";
BA_ "VNSigAllNodes" SG_ 977 EngEmsMlfAtv 1;
BA_ "SignalLongName" SG_ 977 EngEmsMlfAtv "Engine Emissions Related Malfunction Active";
BA_ "SignalType" SG_ 977 EngEmsMlfAtv "BLN";
BA_ "VNSigAllNodes" SG_ 977 EngCstFlCutAct 1;
BA_ "SignalLongName" SG_ 977 EngCstFlCutAct "Engine Coast Fuel Cut Off Active";
BA_ "SignalType" SG_ 977 EngCstFlCutAct "BLN";
BA_ "VNSigAllNodes" SG_ 977 AppBrkBfrCrsIO 1;
BA_ "SignalLongName" SG_ 977 AppBrkBfrCrsIO "Apply Brake Before Cruise Indication On";
BA_ "SignalType" SG_ 977 AppBrkBfrCrsIO "BLN";
BA_ "VNSigAllNodes" SG_ 977 CrsSpdLmtrDrvSelSpd 1;
BA_ "SignalLongName" SG_ 977 CrsSpdLmtrDrvSelSpd "Cruise and Speed Limiter Driver Selected Speed";
BA_ "SignalType" SG_ 977 CrsSpdLmtrDrvSelSpd "UNM";
BA_ "VNSigAllNodes" SG_ 201 EngAirIntBstPrV 1;
BA_ "SignalLongName" SG_ 201 EngAirIntBstPrV "Engine Intake Air Boost Pressure Validity";
BA_ "SignalType" SG_ 201 EngAirIntBstPrV "ENM";
BA_ "VNSigAllNodes" SG_ 201 EngAirIntBstPr 1;
BA_ "SignalLongName" SG_ 201 EngAirIntBstPr "Engine Intake Air Boost Pressure";
BA_ "SignalType" SG_ 201 EngAirIntBstPr "SNM";
BA_ "VNSigAllNodes" SG_ 201 SpdLmtrSpdWrngEnbld 1;
BA_ "SignalLongName" SG_ 201 SpdLmtrSpdWrngEnbld "Speed Limiter/Speed Warning Enabled";
BA_ "SignalType" SG_ 201 SpdLmtrSpdWrngEnbld "BLN";
BA_ "VNSigAllNodes" SG_ 201 SpdLmtrSpdWrngAct 1;
BA_ "SignalLongName" SG_ 201 SpdLmtrSpdWrngAct "Speed Limiter/Speed Warning Active";
BA_ "SignalType" SG_ 201 SpdLmtrSpdWrngAct "BLN";
BA_ "VNSigAllNodes" SG_ 201 EngCylDactEvntPndg 1;
BA_ "SignalLongName" SG_ 201 EngCylDactEvntPndg "Engine Cylinder Deactivation Event Pending";
BA_ "SignalType" SG_ 201 EngCylDactEvntPndg "BLN";
BA_ "VNSigAllNodes" SG_ 201 EngCylDeactMd 1;
BA_ "SignalLongName" SG_ 201 EngCylDeactMd "Engine Cylinder Deactivation Mode";
BA_ "SignalType" SG_ 201 EngCylDeactMd "ENM";
BA_ "VNSigAllNodes" SG_ 201 RmVhStrtEngRng 1;
BA_ "SignalLongName" SG_ 201 RmVhStrtEngRng "Remote Vehicle Start Engine Running";
BA_ "SignalType" SG_ 201 RmVhStrtEngRng "BLN";
BA_ "VNSigAllNodes" SG_ 201 PFEngSpdCmndSpcd 1;
BA_ "SignalLongName" SG_ 201 PFEngSpdCmndSpcd "Platform Engine Speed Command Superceded";
BA_ "SignalType" SG_ 201 PFEngSpdCmndSpcd "BLN";
BA_ "VNSigAllNodes" SG_ 201 DrThrtlOvrrdDetProtVal 1;
BA_ "SignalLongName" SG_ 201 DrThrtlOvrrdDetProtVal "Driver Throttle Override Detected Protection Value";
BA_ "SignalType" SG_ 201 DrThrtlOvrrdDetProtVal "UNM";
BA_ "VNSigAllNodes" SG_ 201 DrThrtlOvrdDetAlvRlCnt 1;
BA_ "SignalLongName" SG_ 201 DrThrtlOvrdDetAlvRlCnt "Driver Throttle Override Detection Alive Rolling Count";
BA_ "SignalType" SG_ 201 DrThrtlOvrdDetAlvRlCnt "UNM";
BA_ "VNSigAllNodes" SG_ 201 PltfrmEngSpdCmdInhtRq 1;
BA_ "SignalLongName" SG_ 201 PltfrmEngSpdCmdInhtRq "Platform Engine Speed Command Inhibit Request";
BA_ "SignalType" SG_ 201 PltfrmEngSpdCmdInhtRq "ENM";
BA_ "VNSigAllNodes" SG_ 201 PT_BrkPedDscrtInpStatV 1;
BA_ "SignalLongName" SG_ 201 PT_BrkPedDscrtInpStatV "Powertrain Brake Pedal Discrete Input Status Validity";
BA_ "SignalType" SG_ 201 PT_BrkPedDscrtInpStatV "ENM";
BA_ "VNSigAllNodes" SG_ 201 PT_BrkPedDscrtInpStat 1;
BA_ "SignalLongName" SG_ 201 PT_BrkPedDscrtInpStat "Powertrain Brake Pedal Discrete Input Status";
BA_ "SignalType" SG_ 201 PT_BrkPedDscrtInpStat "ENM";
BA_ "VNSigAllNodes" SG_ 201 AccActPos 1;
BA_ "SignalLongName" SG_ 201 AccActPos "Accelerator Actual Position";
BA_ "SignalType" SG_ 201 AccActPos "UNM";
BA_ "VNSigAllNodes" SG_ 201 CrsCntEnbld 1;
BA_ "SignalLongName" SG_ 201 CrsCntEnbld "Cruise Control Enabled";
BA_ "SignalType" SG_ 201 CrsCntEnbld "BLN";
BA_ "VNSigAllNodes" SG_ 201 CrsCntAtv 1;
BA_ "SignalLongName" SG_ 201 CrsCntAtv "Cruise Control Active";
BA_ "SignalType" SG_ 201 CrsCntAtv "BLN";
BA_ "VNSigAllNodes" SG_ 201 DrvThrottlOvrrdDet 1;
BA_ "SignalLongName" SG_ 201 DrvThrottlOvrrdDet "Driver Throttle Override Detected";
BA_ "SignalType" SG_ 201 DrvThrottlOvrrdDet "BLN";
BA_ "VNSigAllNodes" SG_ 201 PT_CrnkAct 1;
BA_ "SignalLongName" SG_ 201 PT_CrnkAct "Powertrain Crank Active";
BA_ "SignalType" SG_ 201 PT_CrnkAct "BLN";
BA_ "VNSigAllNodes" SG_ 201 PTRunAbrt 1;
BA_ "SignalLongName" SG_ 201 PTRunAbrt "Powertrain Run Aborted";
BA_ "SignalType" SG_ 201 PTRunAbrt "BLN";
BA_ "VNSigAllNodes" SG_ 201 PTO_PT_RunAbrtd 1;
BA_ "SignalLongName" SG_ 201 PTO_PT_RunAbrtd "Power Take Off Powertrain Run Aborted";
BA_ "SignalType" SG_ 201 PTO_PT_RunAbrtd "BLN";
BA_ "VNSigAllNodes" SG_ 201 PTCrnkAbrted 1;
BA_ "SignalLongName" SG_ 201 PTCrnkAbrted "Powertrain Crank Aborted";
BA_ "SignalType" SG_ 201 PTCrnkAbrted "BLN";
BA_ "VNSigAllNodes" SG_ 201 EngSpdStat 1;
BA_ "SignalLongName" SG_ 201 EngSpdStat "Engine Speed Status";
BA_ "SignalType" SG_ 201 EngSpdStat "ENM";
BA_ "VNSigAllNodes" SG_ 201 EngSpd 1;
BA_ "SignalLongName" SG_ 201 EngSpd "Engine Speed";
BA_ "SignalType" SG_ 201 EngSpd "UNM";
BA_ "VNSigAllNodes" SG_ 201 EngRunAtv 1;
BA_ "SignalLongName" SG_ 201 EngRunAtv "Engine Run Active";
BA_ "SignalType" SG_ 201 EngRunAtv "BLN";
BA_ "VNSigAllNodes" SG_ 201 EngIdlAtv 1;
BA_ "SignalLongName" SG_ 201 EngIdlAtv "Engine Idle Active";
BA_ "SignalType" SG_ 201 EngIdlAtv "BLN";
BA_ "VNSigAllNodes" SG_ 201 AccActPosV 1;
BA_ "SignalLongName" SG_ 201 AccActPosV "Accelerator Actual Position Validity";
BA_ "SignalType" SG_ 201 AccActPosV "ENM";
BA_ "VNSigAllNodes" SG_ 501 EngRecDwnshftIO 1;
BA_ "SignalLongName" SG_ 501 EngRecDwnshftIO "Engine Recommended Downshift Indication On";
BA_ "SignalType" SG_ 501 EngRecDwnshftIO "BLN";
BA_ "VNSigAllNodes" SG_ 501 TrnsPattSelEcnMdOCm 1;
BA_ "SignalLongName" SG_ 501 TrnsPattSelEcnMdOCm "Transmission Pattern Selection Economy Mode Override Commanded";
BA_ "SignalType" SG_ 501 TrnsPattSelEcnMdOCm "BLN";
BA_ "VNSigAllNodes" SG_ 501 TransShftDlyd 1;
BA_ "SignalLongName" SG_ 501 TransShftDlyd "Transmission Shifts Delayed";
BA_ "SignalType" SG_ 501 TransShftDlyd "BLN";
BA_ "VNSigAllNodes" SG_ 501 CltStartSwAtvV 1;
BA_ "SignalLongName" SG_ 501 CltStartSwAtvV "Clutch Start Switch Active Validity";
BA_ "SignalType" SG_ 501 CltStartSwAtvV "ENM";
BA_ "VNSigAllNodes" SG_ 501 CltStartSwAtv 1;
BA_ "GenSigStartValue" SG_ 501 CltStartSwAtv 1;
BA_ "SignalLongName" SG_ 501 CltStartSwAtv "Clutch Start Switch Active";
BA_ "SignalType" SG_ 501 CltStartSwAtv "BLN";
BA_ "VNSigAllNodes" SG_ 501 CltchPdlActPosV 1;
BA_ "SignalLongName" SG_ 501 CltchPdlActPosV "Clutch Pedal Actual Position Validity";
BA_ "SignalType" SG_ 501 CltchPdlActPosV "ENM";
BA_ "VNSigAllNodes" SG_ 501 CltchPdlActPos 1;
BA_ "SignalLongName" SG_ 501 CltchPdlActPos "Clutch Pedal Actual Position";
BA_ "SignalType" SG_ 501 CltchPdlActPos "UNM";
BA_ "VNSigAllNodes" SG_ 501 TrnsEngdStateV 1;
BA_ "SignalLongName" SG_ 501 TrnsEngdStateV "Transmission Engaged State Validity";
BA_ "SignalType" SG_ 501 TrnsEngdStateV "ENM";
BA_ "VNSigAllNodes" SG_ 501 TrnsEngdState 1;
BA_ "SignalLongName" SG_ 501 TrnsEngdState "Transmission Engaged State";
BA_ "SignalType" SG_ 501 TrnsEngdState "ENM";
BA_ "VNSigAllNodes" SG_ 501 TransTUDMdStat 1;
BA_ "SignalLongName" SG_ 501 TransTUDMdStat "Transmission Tap Up/Tap Down Mode Status";
BA_ "SignalType" SG_ 501 TransTUDMdStat "ENM";
BA_ "VNSigAllNodes" SG_ 501 TrnCrpMdAtv 1;
BA_ "SignalLongName" SG_ 501 TrnCrpMdAtv "Transmission Creep Mode Active";
BA_ "SignalType" SG_ 501 TrnCrpMdAtv "BLN";
BA_ "VNSigAllNodes" SG_ 501 TrnsShftLvrLckRqd 1;
BA_ "SignalLongName" SG_ 501 TrnsShftLvrLckRqd "Transmission Shift Lever Lock Requested";
BA_ "SignalType" SG_ 501 TrnsShftLvrLckRqd "BLN";
BA_ "VNSigAllNodes" SG_ 501 TrnsSkpShftIO 1;
BA_ "SignalLongName" SG_ 501 TrnsSkpShftIO "Transmission Skip Shift Indication On";
BA_ "SignalType" SG_ 501 TrnsSkpShftIO "BLN";
BA_ "VNSigAllNodes" SG_ 501 TrnsSftMdStat 1;
BA_ "SignalLongName" SG_ 501 TrnsSftMdStat "Transmission Shift Mode Status";
BA_ "SignalType" SG_ 501 TrnsSftMdStat "ENM";
BA_ "VNSigAllNodes" SG_ 501 TrnsRngInhbtStat 1;
BA_ "SignalLongName" SG_ 501 TrnsRngInhbtStat "Transmission Range Inhibit Status";
BA_ "SignalType" SG_ 501 TrnsRngInhbtStat "ENM";
BA_ "VNSigAllNodes" SG_ 501 TopTrvlCltchSwActV 1;
BA_ "SignalLongName" SG_ 501 TopTrvlCltchSwActV "Top of Travel Clutch Switch Active Validity";
BA_ "SignalType" SG_ 501 TopTrvlCltchSwActV "ENM";
BA_ "VNSigAllNodes" SG_ 501 TopTrvlCltchSwAct 1;
BA_ "SignalLongName" SG_ 501 TopTrvlCltchSwAct "Top of Travel Clutch Switch Active";
BA_ "SignalType" SG_ 501 TopTrvlCltchSwAct "BLN";
BA_ "VNSigAllNodes" SG_ 501 OvrdrvDsblReqGrntd 1;
BA_ "SignalLongName" SG_ 501 OvrdrvDsblReqGrntd "Overdrive Disable Request Granted";
BA_ "SignalType" SG_ 501 OvrdrvDsblReqGrntd "BLN";
BA_ "VNSigAllNodes" SG_ 501 EngRecmndUpshftIO 1;
BA_ "SignalLongName" SG_ 501 EngRecmndUpshftIO "Engine Recommended Upshift Indication On";
BA_ "SignalType" SG_ 501 EngRecmndUpshftIO "BLN";
BA_ "VNSigAllNodes" SG_ 501 DrvtShftCntrlTrgtGear 1;
BA_ "SignalLongName" SG_ 501 DrvtShftCntrlTrgtGear "Driver Shift Control Target Gear";
BA_ "SignalType" SG_ 501 DrvtShftCntrlTrgtGear "ENM";
BA_ "VNSigAllNodes" SG_ 501 DrShftCntrlReqDndIO 1;
BA_ "SignalLongName" SG_ 501 DrShftCntrlReqDndIO "Driver Shift Control Request Denied Indication On";
BA_ "SignalType" SG_ 501 DrShftCntrlReqDndIO "BLN";
BA_ "VNSigAllNodes" SG_ 501 TrnShftPtrnActStat 1;
BA_ "SignalLongName" SG_ 501 TrnShftPtrnActStat "Transmission Shift Pattern Active Status";
BA_ "SignalType" SG_ 501 TrnShftPtrnActStat "ENM";
BA_ "VNSigAllNodes" SG_ 501 TrnsFldPrsPrsnt 1;
BA_ "SignalLongName" SG_ 501 TrnsFldPrsPrsnt "Transmission Fluid Pressure Present";
BA_ "SignalType" SG_ 501 TrnsFldPrsPrsnt "BLN";
BA_ "VNSigAllNodes" SG_ 501 TrnsShftLvrPos 1;
BA_ "SignalLongName" SG_ 501 TrnsShftLvrPos "Transmission Shift Lever Position";
BA_ "SignalType" SG_ 501 TrnsShftLvrPos "ENM";
BA_ "VNSigAllNodes" SG_ 501 TrnsShftLvrPosV 1;
BA_ "SignalLongName" SG_ 501 TrnsShftLvrPosV "Transmission Shift Lever Position Validity";
BA_ "SignalType" SG_ 501 TrnsShftLvrPosV "ENM";
BA_ "VNSigAllNodes" SG_ 501 TrnsTrqCnvCltCmndMd 1;
BA_ "GenSigStartValue" SG_ 501 TrnsTrqCnvCltCmndMd 7;
BA_ "SignalLongName" SG_ 501 TrnsTrqCnvCltCmndMd "Transmission Torque Converter Clutch Commanded Mode";
BA_ "SignalType" SG_ 501 TrnsTrqCnvCltCmndMd "ENM";
BA_ "VNSigAllNodes" SG_ 501 AutoTransComndGear 1;
BA_ "GenSigStartValue" SG_ 501 AutoTransComndGear 15;
BA_ "SignalLongName" SG_ 501 AutoTransComndGear "Automatic Transmission Commanded Gear";
BA_ "SignalType" SG_ 501 AutoTransComndGear "ENM";
BA_ "VNSigAllNodes" SG_ 501 AutoTransGrSftDirect 1;
BA_ "SignalLongName" SG_ 501 AutoTransGrSftDirect "Automatic Transmission Gear Shift Direction";
BA_ "SignalType" SG_ 501 AutoTransGrSftDirect "ENM";
BA_ "VNSigAllNodes" SG_ 501 TransEstGear 1;
BA_ "GenSigStartValue" SG_ 501 TransEstGear 15;
BA_ "SignalLongName" SG_ 501 TransEstGear "Transmission Estimated Gear";
BA_ "SignalType" SG_ 501 TransEstGear "ENM";
BA_ "VNSigAllNodes" SG_ 501 TransEstGearV 1;
BA_ "SignalLongName" SG_ 501 TransEstGearV "Transmission Estimated Gear Validity";
BA_ "SignalType" SG_ 501 TransEstGearV "ENM";
BA_ "VNSigAllNodes" SG_ 1225 TrnsThrmlMngmntStat 1;
BA_ "SignalLongName" SG_ 1225 TrnsThrmlMngmntStat "Transmission Thermal Management Status";
BA_ "SignalType" SG_ 1225 TrnsThrmlMngmntStat "ENM";
BA_ "VNSigAllNodes" SG_ 1225 TrnsNEmsRltMalfActv 1;
BA_ "SignalLongName" SG_ 1225 TrnsNEmsRltMalfActv "Transmission Non Emissions Related Malfunction Active";
BA_ "SignalType" SG_ 1225 TrnsNEmsRltMalfActv "BLN";
BA_ "VNSigAllNodes" SG_ 1225 TransOilTempSensPres 1;
BA_ "SignalLongName" SG_ 1225 TransOilTempSensPres "Transmission Oil Temperature Sensor Present";
BA_ "SignalType" SG_ 1225 TransOilTempSensPres "BLN";
BA_ "VNSigAllNodes" SG_ 1225 TrnEmsMlfAtv 1;
BA_ "SignalLongName" SG_ 1225 TrnEmsMlfAtv "Transmission Emissions Related Malfunction Active";
BA_ "SignalType" SG_ 1225 TrnEmsMlfAtv "BLN";
BA_ "VNSigAllNodes" SG_ 1225 TrnOilTmp 1;
BA_ "SignalLongName" SG_ 1225 TrnOilTmp "Transmission Oil Temperature";
BA_ "SignalType" SG_ 1225 TrnOilTmp "UNM";
BA_ "VNSigAllNodes" SG_ 1225 TrnOilTmpV 1;
BA_ "SignalLongName" SG_ 1225 TrnOilTmpV "Transmission Oil Temperature Validity";
BA_ "SignalType" SG_ 1225 TrnOilTmpV "ENM";
BA_ "VNSigAllNodes" SG_ 1225 TERDTC_SysDes 1;
BA_ "SignalLongName" SG_ 1225 TERDTC_SysDes "Transmission Emissions Related DTC : System Designator";
BA_ "PacketOrder" SG_ 1225 TERDTC_SysDes 1;
BA_ "SignalType" SG_ 1225 TERDTC_SysDes "ENM";
BA_ "VNSigAllNodes" SG_ 1225 TERDTC_CdNum 1;
BA_ "SignalLongName" SG_ 1225 TERDTC_CdNum "Transmission Emissions Related DTC : Code Number";
BA_ "PacketOrder" SG_ 1225 TERDTC_CdNum 2;
BA_ "SignalType" SG_ 1225 TERDTC_CdNum "UNM";
BA_ "VNSigAllNodes" SG_ 409 TrnsAliveRC_199 1;
BA_ "SignalLongName" SG_ 409 TrnsAliveRC_199 "Transmission Alive Rolling Count 199";
BA_ "SignalType" SG_ 409 TrnsAliveRC_199 "UNM";
BA_ "VNSigAllNodes" SG_ 409 TDslPrtFltrIdlRgtnMdAtv 1;
BA_ "SignalLongName" SG_ 409 TDslPrtFltrIdlRgtnMdAtv "Transmission Diesel Particulate Filter Idle Regeneration Mode Active";
BA_ "SignalType" SG_ 409 TDslPrtFltrIdlRgtnMdAtv "BLN";
BA_ "VNSigAllNodes" SG_ 409 TransMinVoltReq 1;
BA_ "SignalLongName" SG_ 409 TransMinVoltReq "Transmission Minimum Voltage Request";
BA_ "SignalType" SG_ 409 TransMinVoltReq "UNM";
BA_ "VNSigAllNodes" SG_ 409 TransVehTopSpdLim 1;
BA_ "SignalLongName" SG_ 409 TransVehTopSpdLim "Transmission Vehicle Top Speed Limit Value";
BA_ "SignalType" SG_ 409 TransVehTopSpdLim "UNM";
BA_ "VNSigAllNodes" SG_ 409 TrnsTrqRqProt 1;
BA_ "SignalLongName" SG_ 409 TrnsTrqRqProt "Transmission Torque Request Protection";
BA_ "SignalType" SG_ 409 TrnsTrqRqProt "UNM";
BA_ "VNSigAllNodes" SG_ 409 TTRLT_TorqReqVal 1;
BA_ "SignalLongName" SG_ 409 TTRLT_TorqReqVal "Transmission Torque Request Long-term : Torque Request Value";
BA_ "PacketOrder" SG_ 409 TTRLT_TorqReqVal 3;
BA_ "SignalType" SG_ 409 TTRLT_TorqReqVal "UNM";
BA_ "VNSigAllNodes" SG_ 409 TTRLT_TqRdnRlznSgg 1;
BA_ "SignalLongName" SG_ 409 TTRLT_TqRdnRlznSgg "Transmission Torque Request Long-term : Torque Reduction Realization Suggestion";
BA_ "PacketOrder" SG_ 409 TTRLT_TqRdnRlznSgg 2;
BA_ "SignalType" SG_ 409 TTRLT_TqRdnRlznSgg "ENM";
BA_ "VNSigAllNodes" SG_ 409 TTRLT_TorqInvntnTyp 1;
BA_ "SignalLongName" SG_ 409 TTRLT_TorqInvntnTyp "Transmission Torque Request Long-term : Torque Intervention Type";
BA_ "PacketOrder" SG_ 409 TTRLT_TorqInvntnTyp 1;
BA_ "SignalType" SG_ 409 TTRLT_TorqInvntnTyp "ENM";
BA_ "VNSigAllNodes" SG_ 409 TTRST_TorqReqVal 1;
BA_ "SignalLongName" SG_ 409 TTRST_TorqReqVal "Transmission Torque Request Short-term : Torque Request Value";
BA_ "PacketOrder" SG_ 409 TTRST_TorqReqVal 2;
BA_ "SignalType" SG_ 409 TTRST_TorqReqVal "UNM";
BA_ "VNSigAllNodes" SG_ 409 TTRST_TorqInvntnTyp 1;
BA_ "SignalLongName" SG_ 409 TTRST_TorqInvntnTyp "Transmission Torque Request Short-term : Torque Intervention Type";
BA_ "PacketOrder" SG_ 409 TTRST_TorqInvntnTyp 1;
BA_ "SignalType" SG_ 409 TTRST_TorqInvntnTyp "ENM";
BA_ "VNSigAllNodes" SG_ 413 TrnsCyDactTransStat 1;
BA_ "SignalLongName" SG_ 413 TrnsCyDactTransStat "Transmission Cylinder Deactivation Transition Status";
BA_ "SignalType" SG_ 413 TrnsCyDactTransStat "ENM";
BA_ "VNSigAllNodes" SG_ 413 EngBrkDsblReqd 1;
BA_ "SignalLongName" SG_ 413 EngBrkDsblReqd "Engine Brake Disable Requested";
BA_ "SignalType" SG_ 413 EngBrkDsblReqd "BLN";
BA_ "VNSigAllNodes" SG_ 413 TransNtrlCntrlMdStat 1;
BA_ "SignalLongName" SG_ 413 TransNtrlCntrlMdStat "Transmission Neutral Control Mode Status";
BA_ "SignalType" SG_ 413 TransNtrlCntrlMdStat "ENM";
BA_ "VNSigAllNodes" SG_ 413 TrnsRtoCntlSysFlt 1;
BA_ "SignalLongName" SG_ 413 TrnsRtoCntlSysFlt "Transmission Ratio Control System Fault";
BA_ "SignalType" SG_ 413 TrnsRtoCntlSysFlt "BLN";
BA_ "VNSigAllNodes" SG_ 413 TrnTrbAngVl 1;
BA_ "SignalLongName" SG_ 413 TrnTrbAngVl "Transmission Turbine Angular Velocity";
BA_ "SignalType" SG_ 413 TrnTrbAngVl "UNM";
BA_ "VNSigAllNodes" SG_ 413 TrnTrbAngVlV 1;
BA_ "SignalLongName" SG_ 413 TrnTrbAngVlV "Transmission Turbine Angular Velocity Validity";
BA_ "SignalType" SG_ 413 TrnTrbAngVlV "ENM";
BA_ "VNSigAllNodes" SG_ 413 TrnGrRat 1;
BA_ "SignalLongName" SG_ 413 TrnGrRat "Transmission Gear Ratio";
BA_ "SignalType" SG_ 413 TrnGrRat "UNM";
BA_ "VNSigAllNodes" SG_ 413 TrnGrRatV 1;
BA_ "SignalLongName" SG_ 413 TrnGrRatV "Transmission Gear Ratio Validity";
BA_ "SignalType" SG_ 413 TrnGrRatV "ENM";
BA_ "VNSigAllNodes" SG_ 413 TrnPrfAlgShfAtv 1;
BA_ "SignalLongName" SG_ 413 TrnPrfAlgShfAtv "Transmission Performance Algorithm Shift Mode Active";
BA_ "SignalType" SG_ 413 TrnPrfAlgShfAtv "BLN";
BA_ "VNSigAllNodes" SG_ 413 TrnsAliveRC 1;
BA_ "SignalLongName" SG_ 413 TrnsAliveRC "Transmission Alive Rolling Count";
BA_ "SignalType" SG_ 413 TrnsAliveRC "UNM";
BA_ "VNSigAllNodes" SG_ 413 TrnsEngSpdRqProt 1;
BA_ "SignalLongName" SG_ 413 TrnsEngSpdRqProt "Transmission Engine Speed Request Protection";
BA_ "SignalType" SG_ 413 TrnsEngSpdRqProt "UNM";
BA_ "VNSigAllNodes" SG_ 413 TESR_EngSpdCntlRsp 1;
BA_ "SignalLongName" SG_ 413 TESR_EngSpdCntlRsp "Transmission Engine Speed Request : Engine Speed Control Response";
BA_ "PacketOrder" SG_ 413 TESR_EngSpdCntlRsp 2;
BA_ "SignalType" SG_ 413 TESR_EngSpdCntlRsp "ENM";
BA_ "VNSigAllNodes" SG_ 413 TESR_EngSpdRqVal 1;
BA_ "SignalLongName" SG_ 413 TESR_EngSpdRqVal "Transmission Engine Speed Request : Engine Speed Request Value";
BA_ "PacketOrder" SG_ 413 TESR_EngSpdRqVal 3;
BA_ "SignalType" SG_ 413 TESR_EngSpdRqVal "UNM";
BA_ "VNSigAllNodes" SG_ 413 TESR_EngSpdIntTyp 1;
BA_ "SignalLongName" SG_ 413 TESR_EngSpdIntTyp "Transmission Engine Speed Request : Engine Speed Intervention Type";
BA_ "PacketOrder" SG_ 413 TESR_EngSpdIntTyp 1;
BA_ "SignalType" SG_ 413 TESR_EngSpdIntTyp "ENM";
BA_ "VNSigAllNodes" SG_ 413 TrnsGrgShftAct 1;
BA_ "SignalLongName" SG_ 413 TrnsGrgShftAct "Transmission Garage Shift Active";
BA_ "SignalType" SG_ 413 TrnsGrgShftAct "BLN";
BA_ "VNSigAllNodes" SG_ 257 DgnInf 1;
BA_ "SignalLongName" SG_ 257 DgnInf "Diagnostic Information";
BA_ "SignalType" SG_ 257 DgnInf "UNM";
BA_ "VNSigSLHSSharedDiagnostic" SG_ 257 DgnInf 1;
BA_ "VNSigAllNodes" SG_ 2016 DgnInf 1;
BA_ "SignalLongName" SG_ 2016 DgnInf "Diagnostic Information";
BA_ "SignalType" SG_ 2016 DgnInf "UNM";
BA_ "VNSigSLHSSharedDiagnostic" SG_ 2016 DgnInf 1;
BA_ "VNSigAllNodes" SG_ 197 WRSLNDWhlDisTpRC 1;
BA_ "SignalLongName" SG_ 197 WRSLNDWhlDisTpRC "Wheel Rotational Status Left Non Driven : Wheel Distance Timestamp Rollover Counter";
BA_ "PacketOrder" SG_ 197 WRSLNDWhlDisTpRC 1;
BA_ "SignalType" SG_ 197 WRSLNDWhlDisTpRC "UNM";
BA_ "VNSigAllNodes" SG_ 197 WRSLNDWhlRotStRst 1;
BA_ "SignalLongName" SG_ 197 WRSLNDWhlRotStRst "Wheel Rotational Status Left Non Driven : Wheel Rotational Status Reset Occurred";
BA_ "PacketOrder" SG_ 197 WRSLNDWhlRotStRst 3;
BA_ "SignalType" SG_ 197 WRSLNDWhlRotStRst "BLN";
BA_ "VNSigAllNodes" SG_ 197 WRSLNDWhlDistVal 1;
BA_ "SignalLongName" SG_ 197 WRSLNDWhlDistVal "Wheel Rotational Status Left Non Driven : Wheel Distance Validity";
BA_ "PacketOrder" SG_ 197 WRSLNDWhlDistVal 4;
BA_ "SignalType" SG_ 197 WRSLNDWhlDistVal "ENM";
BA_ "VNSigAllNodes" SG_ 197 WRSLNDWhlDistTstm 1;
BA_ "SignalLongName" SG_ 197 WRSLNDWhlDistTstm "Wheel Rotational Status Left Non Driven : Wheel Distance Timestamp";
BA_ "PacketOrder" SG_ 197 WRSLNDWhlDistTstm 6;
BA_ "SignalType" SG_ 197 WRSLNDWhlDistTstm "UNM";
BA_ "VNSigAllNodes" SG_ 197 WRSLNDWhlDistPCntr 1;
BA_ "SignalLongName" SG_ 197 WRSLNDWhlDistPCntr "Wheel Rotational Status Left Non Driven : Wheel Distance Pulse Counter";
BA_ "PacketOrder" SG_ 197 WRSLNDWhlDistPCntr 5;
BA_ "SignalType" SG_ 197 WRSLNDWhlDistPCntr "UNM";
BA_ "VNSigAllNodes" SG_ 197 WRSLNDSeqNum 1;
BA_ "SignalLongName" SG_ 197 WRSLNDSeqNum "Wheel Rotational Status Left Non Driven : Sequence Number";
BA_ "PacketOrder" SG_ 197 WRSLNDSeqNum 2;
BA_ "SignalType" SG_ 197 WRSLNDSeqNum "UNM";
BA_ "VNSigAllNodes" SG_ 197 WRSRNDWhlDisTpRC 1;
BA_ "SignalLongName" SG_ 197 WRSRNDWhlDisTpRC "Wheel Rotational Status Right Non Driven : Wheel Distance Timestamp Rollover Counter";
BA_ "PacketOrder" SG_ 197 WRSRNDWhlDisTpRC 1;
BA_ "SignalType" SG_ 197 WRSRNDWhlDisTpRC "UNM";
BA_ "VNSigAllNodes" SG_ 197 WRSRNDWhlRotStRst 1;
BA_ "SignalLongName" SG_ 197 WRSRNDWhlRotStRst "Wheel Rotational Status Right Non Driven : Wheel Rotational Status Reset Occurred";
BA_ "PacketOrder" SG_ 197 WRSRNDWhlRotStRst 3;
BA_ "SignalType" SG_ 197 WRSRNDWhlRotStRst "BLN";
BA_ "VNSigAllNodes" SG_ 197 WRSRNDWhlDistVal 1;
BA_ "SignalLongName" SG_ 197 WRSRNDWhlDistVal "Wheel Rotational Status Right Non Driven : Wheel Distance Validity";
BA_ "PacketOrder" SG_ 197 WRSRNDWhlDistVal 4;
BA_ "SignalType" SG_ 197 WRSRNDWhlDistVal "ENM";
BA_ "VNSigAllNodes" SG_ 197 WRSRNDWhlDistTstm 1;
BA_ "SignalLongName" SG_ 197 WRSRNDWhlDistTstm "Wheel Rotational Status Right Non Driven : Wheel Distance Timestamp";
BA_ "PacketOrder" SG_ 197 WRSRNDWhlDistTstm 6;
BA_ "SignalType" SG_ 197 WRSRNDWhlDistTstm "UNM";
BA_ "VNSigAllNodes" SG_ 197 WRSRNDWhlDistPCntr 1;
BA_ "SignalLongName" SG_ 197 WRSRNDWhlDistPCntr "Wheel Rotational Status Right Non Driven : Wheel Distance Pulse Counter";
BA_ "PacketOrder" SG_ 197 WRSRNDWhlDistPCntr 5;
BA_ "SignalType" SG_ 197 WRSRNDWhlDistPCntr "UNM";
BA_ "VNSigAllNodes" SG_ 197 WRSRNDSeqNum 1;
BA_ "SignalLongName" SG_ 197 WRSRNDSeqNum "Wheel Rotational Status Right Non Driven : Sequence Number";
BA_ "PacketOrder" SG_ 197 WRSRNDSeqNum 2;
BA_ "SignalType" SG_ 197 WRSRNDSeqNum "UNM";
BA_REL_ "GenSigTimeoutTime" BU_SG_REL_ EPS_HS SG_ 1280 WhlRotStatTmstmpRes 2500;
BA_REL_ "GenSigTimeoutMsg" BU_SG_REL_ EPS_HS SG_ 1280 WhlRotStatTmstmpRes 1280;
BA_REL_ "GenSigSuprvResp" BU_SG_REL_ EPS_HS SG_ 1280 WhlRotStatTmstmpRes 1;
BA_REL_ "GenSigTimeoutTime" BU_SG_REL_ EPS_HS SG_ 192 WRSCD_RtNDrvnSNm 250;
BA_REL_ "GenSigTimeoutMsg" BU_SG_REL_ EPS_HS SG_ 192 WRSCD_RtNDrvnSNm 192;
BA_REL_ "GenSigSuprvResp" BU_SG_REL_ EPS_HS SG_ 192 WRSCD_RtNDrvnSNm 1;
BA_REL_ "GenSigTimeoutTime" BU_SG_REL_ EPS_HS SG_ 192 WRSCD_RtDrvnSqNm 250;
BA_REL_ "GenSigTimeoutMsg" BU_SG_REL_ EPS_HS SG_ 192 WRSCD_RtDrvnSqNm 192;
BA_REL_ "GenSigSuprvResp" BU_SG_REL_ EPS_HS SG_ 192 WRSCD_RtDrvnSqNm 1;
BA_REL_ "GenSigTimeoutTime" BU_SG_REL_ EPS_HS SG_ 192 WRSCD_RNDrvnCkVa 250;
BA_REL_ "GenSigTimeoutMsg" BU_SG_REL_ EPS_HS SG_ 192 WRSCD_RNDrvnCkVa 192;
BA_REL_ "GenSigSuprvResp" BU_SG_REL_ EPS_HS SG_ 192 WRSCD_RNDrvnCkVa 1;
BA_REL_ "GenSigTimeoutTime" BU_SG_REL_ EPS_HS SG_ 192 WRSCD_RDrvnCkVa 250;
BA_REL_ "GenSigTimeoutMsg" BU_SG_REL_ EPS_HS SG_ 192 WRSCD_RDrvnCkVa 192;
BA_REL_ "GenSigSuprvResp" BU_SG_REL_ EPS_HS SG_ 192 WRSCD_RDrvnCkVa 1;
BA_REL_ "GenSigTimeoutTime" BU_SG_REL_ EPS_HS SG_ 192 WRSCD_LftNDrvnSNm 250;
BA_REL_ "GenSigTimeoutMsg" BU_SG_REL_ EPS_HS SG_ 192 WRSCD_LftNDrvnSNm 192;
BA_REL_ "GenSigSuprvResp" BU_SG_REL_ EPS_HS SG_ 192 WRSCD_LftNDrvnSNm 1;
BA_REL_ "GenSigTimeoutTime" BU_SG_REL_ EPS_HS SG_ 192 WRSCD_LftDrvnSqNm 250;
BA_REL_ "GenSigTimeoutMsg" BU_SG_REL_ EPS_HS SG_ 192 WRSCD_LftDrvnSqNm 192;
BA_REL_ "GenSigSuprvResp" BU_SG_REL_ EPS_HS SG_ 192 WRSCD_LftDrvnSqNm 1;
BA_REL_ "GenSigTimeoutTime" BU_SG_REL_ EPS_HS SG_ 192 WRSCD_LfNDrvnCkVa 250;
BA_REL_ "GenSigTimeoutMsg" BU_SG_REL_ EPS_HS SG_ 192 WRSCD_LfNDrvnCkVa 192;
BA_REL_ "GenSigSuprvResp" BU_SG_REL_ EPS_HS SG_ 192 WRSCD_LfNDrvnCkVa 1;
BA_REL_ "GenSigTimeoutTime" BU_SG_REL_ EPS_HS SG_ 192 WRSCD_LfDrvnCkVa 250;
BA_REL_ "GenSigTimeoutMsg" BU_SG_REL_ EPS_HS SG_ 192 WRSCD_LfDrvnCkVa 192;
BA_REL_ "GenSigSuprvResp" BU_SG_REL_ EPS_HS SG_ 192 WRSCD_LfDrvnCkVa 1;
BA_REL_ "GenSigTimeoutTime" BU_SG_REL_ IPC_HS SG_ 328 StrngAsstRdcdIO 2500;
BA_REL_ "GenSigTimeoutMsg" BU_SG_REL_ IPC_HS SG_ 328 StrngAsstRdcdIO 328;
BA_REL_ "GenSigSuprvResp" BU_SG_REL_ IPC_HS SG_ 328 StrngAsstRdcdIO 1;
BA_REL_ "GenSigTimeoutTime" BU_SG_REL_ TCM_HS SG_ 401 TrnsEngSpdReqFld 31;
BA_REL_ "GenSigTimeoutMsg" BU_SG_REL_ TCM_HS SG_ 401 TrnsEngSpdReqFld 401;
BA_REL_ "GenSigSuprvResp" BU_SG_REL_ TCM_HS SG_ 401 TrnsEngSpdReqFld 1;
BA_REL_ "GenSigTimeoutTime" BU_SG_REL_ TCM_HS SG_ 401 EngTrqTnsRqFld 31;
BA_REL_ "GenSigTimeoutMsg" BU_SG_REL_ TCM_HS SG_ 401 EngTrqTnsRqFld 401;
BA_REL_ "GenSigSuprvResp" BU_SG_REL_ TCM_HS SG_ 401 EngTrqTnsRqFld 1;
BA_REL_ "GenSigTimeoutTime" BU_SG_REL_ BCM_HS SG_ 1265 WhlDistPrRevDrvn 2500;
BA_REL_ "GenSigTimeoutMsg" BU_SG_REL_ BCM_HS SG_ 1265 WhlDistPrRevDrvn 1265;
BA_REL_ "GenSigSuprvResp" BU_SG_REL_ BCM_HS SG_ 1265 WhlDistPrRevDrvn 1;
BA_REL_ "GenSigTimeoutTime" BU_SG_REL_ BCM_HS SG_ 1265 DrvlnFnlAxleRatio 2500;
BA_REL_ "GenSigTimeoutMsg" BU_SG_REL_ BCM_HS SG_ 1265 DrvlnFnlAxleRatio 1265;
BA_REL_ "GenSigSuprvResp" BU_SG_REL_ BCM_HS SG_ 1265 DrvlnFnlAxleRatio 1;
BA_REL_ "GenSigTimeoutTime" BU_SG_REL_ TCM_HS SG_ 417 TracCntlSysPwrtrnInhbt 62;
BA_REL_ "GenSigTimeoutMsg" BU_SG_REL_ TCM_HS SG_ 417 TracCntlSysPwrtrnInhbt 417;
BA_REL_ "GenSigSuprvResp" BU_SG_REL_ TCM_HS SG_ 417 TracCntlSysPwrtrnInhbt 1;
BA_REL_ "GenSigTimeoutTime" BU_SG_REL_ TCM_HS SG_ 417 EngMtlProtAtv 62;
BA_REL_ "GenSigTimeoutMsg" BU_SG_REL_ TCM_HS SG_ 417 EngMtlProtAtv 417;
BA_REL_ "GenSigSuprvResp" BU_SG_REL_ TCM_HS SG_ 417 EngMtlProtAtv 1;
BA_REL_ "GenSigTimeoutTime" BU_SG_REL_ TCM_HS SG_ 417 EngDgTrqCnvClUnlkRqd 62;
BA_REL_ "GenSigTimeoutMsg" BU_SG_REL_ TCM_HS SG_ 417 EngDgTrqCnvClUnlkRqd 417;
BA_REL_ "GenSigSuprvResp" BU_SG_REL_ TCM_HS SG_ 417 EngDgTrqCnvClUnlkRqd 1;
BA_REL_ "GenSigTimeoutTime" BU_SG_REL_ TCM_HS SG_ 417 EngCyldrDeactReqd 62;
BA_REL_ "GenSigTimeoutMsg" BU_SG_REL_ TCM_HS SG_ 417 EngCyldrDeactReqd 417;
BA_REL_ "GenSigSuprvResp" BU_SG_REL_ TCM_HS SG_ 417 EngCyldrDeactReqd 1;
BA_REL_ "GenSigTimeoutTime" BU_SG_REL_ TCM_HS SG_ 417 ETGRReqdGear 62;
BA_REL_ "GenSigTimeoutMsg" BU_SG_REL_ TCM_HS SG_ 417 ETGRReqdGear 417;
BA_REL_ "GenSigSuprvResp" BU_SG_REL_ TCM_HS SG_ 417 ETGRReqdGear 1;
BA_REL_ "GenSigTimeoutTime" BU_SG_REL_ TCM_HS SG_ 417 ETGRReqType 62;
BA_REL_ "GenSigTimeoutMsg" BU_SG_REL_ TCM_HS SG_ 417 ETGRReqType 417;
BA_REL_ "GenSigSuprvResp" BU_SG_REL_ TCM_HS SG_ 417 ETGRReqType 1;
BA_REL_ "GenSigTimeoutTime" BU_SG_REL_ BCM_HS SG_ 1233 FlLvlPct 1250;
BA_REL_ "GenSigTimeoutMsg" BU_SG_REL_ BCM_HS SG_ 1233 FlLvlPct 1233;
BA_REL_ "GenSigSuprvResp" BU_SG_REL_ BCM_HS SG_ 1233 FlLvlPct 1;
BA_REL_ "GenSigVBitResp" BU_SG_REL_ BCM_HS SG_ 1233 FlLvlPct 1;
BA_REL_ "GenSigTimeoutTime" BU_SG_REL_ BCM_HS SG_ 1233 EngOilTmp 1250;
BA_REL_ "GenSigTimeoutMsg" BU_SG_REL_ BCM_HS SG_ 1233 EngOilTmp 1233;
BA_REL_ "GenSigSuprvResp" BU_SG_REL_ BCM_HS SG_ 1233 EngOilTmp 1;
BA_REL_ "GenSigVBitResp" BU_SG_REL_ BCM_HS SG_ 1233 EngOilTmp 1;
BA_REL_ "GenSigTimeoutTime" BU_SG_REL_ BCM_HS SG_ 1233 EngOilPrs 1250;
BA_REL_ "GenSigTimeoutMsg" BU_SG_REL_ BCM_HS SG_ 1233 EngOilPrs 1233;
BA_REL_ "GenSigSuprvResp" BU_SG_REL_ BCM_HS SG_ 1233 EngOilPrs 1;
BA_REL_ "GenSigVBitResp" BU_SG_REL_ BCM_HS SG_ 1233 EngOilPrs 1;
BA_REL_ "GenSigTimeoutTime" BU_SG_REL_ BCM_HS SG_ 1217 OAT_PT_Est 1250;
BA_REL_ "GenSigTimeoutMsg" BU_SG_REL_ BCM_HS SG_ 1217 OAT_PT_Est 1217;
BA_REL_ "GenSigSuprvResp" BU_SG_REL_ BCM_HS SG_ 1217 OAT_PT_Est 1;
BA_REL_ "GenSigVBitResp" BU_SG_REL_ BCM_HS SG_ 1217 OAT_PT_Est 1;
BA_REL_ "GenSigTimeoutTime" BU_SG_REL_ BCM_HS SG_ 1217 EngIntAirTmp 1250;
BA_REL_ "GenSigTimeoutMsg" BU_SG_REL_ BCM_HS SG_ 1217 EngIntAirTmp 1217;
BA_REL_ "GenSigSuprvResp" BU_SG_REL_ BCM_HS SG_ 1217 EngIntAirTmp 1;
BA_REL_ "GenSigVBitResp" BU_SG_REL_ BCM_HS SG_ 1217 EngIntAirTmp 1;
BA_REL_ "GenSigTimeoutTime" BU_SG_REL_ BCM_HS SG_ 1217 EngCltTmp 1250;
BA_REL_ "GenSigTimeoutMsg" BU_SG_REL_ BCM_HS SG_ 1217 EngCltTmp 1217;
BA_REL_ "GenSigSuprvResp" BU_SG_REL_ BCM_HS SG_ 1217 EngCltTmp 1;
BA_REL_ "GenSigVBitResp" BU_SG_REL_ BCM_HS SG_ 1217 EngCltTmp 1;
BA_REL_ "GenSigTimeoutTime" BU_SG_REL_ BCM_HS SG_ 1217 BarPrsAbs 1250;
BA_REL_ "GenSigTimeoutMsg" BU_SG_REL_ BCM_HS SG_ 1217 BarPrsAbs 1217;
BA_REL_ "GenSigSuprvResp" BU_SG_REL_ BCM_HS SG_ 1217 BarPrsAbs 1;
BA_REL_ "GenSigVBitResp" BU_SG_REL_ BCM_HS SG_ 1217 BarPrsAbs 1;
BA_REL_ "GenSigTimeoutTime" BU_SG_REL_ BCM_HS SG_ 1017 ACRfHiSdFldPrs 630;
BA_REL_ "GenSigTimeoutMsg" BU_SG_REL_ BCM_HS SG_ 1017 ACRfHiSdFldPrs 1017;
BA_REL_ "GenSigSuprvResp" BU_SG_REL_ BCM_HS SG_ 1017 ACRfHiSdFldPrs 1;
BA_REL_ "GenSigVBitResp" BU_SG_REL_ BCM_HS SG_ 1017 ACRfHiSdFldPrs 1;
BA_REL_ "GenSigTimeoutTime" BU_SG_REL_ BCM_HS SG_ 1017 GenFldDutCyc 630;
BA_REL_ "GenSigTimeoutMsg" BU_SG_REL_ BCM_HS SG_ 1017 GenFldDutCyc 1017;
BA_REL_ "GenSigSuprvResp" BU_SG_REL_ BCM_HS SG_ 1017 GenFldDutCyc 1;
BA_REL_ "GenSigVBitResp" BU_SG_REL_ BCM_HS SG_ 1017 GenFldDutCyc 1;
BA_REL_ "GenSigTimeoutTime" BU_SG_REL_ BCM_HS SG_ 977 EngBstPrsInd 250;
BA_REL_ "GenSigTimeoutMsg" BU_SG_REL_ BCM_HS SG_ 977 EngBstPrsInd 977;
BA_REL_ "GenSigSuprvResp" BU_SG_REL_ BCM_HS SG_ 977 EngBstPrsInd 1;
BA_REL_ "GenSigVBitResp" BU_SG_REL_ BCM_HS SG_ 977 EngBstPrsInd 1;
BA_REL_ "GenSigTimeoutTime" BU_SG_REL_ BCM_HS SG_ 977 ThrPos 250;
BA_REL_ "GenSigTimeoutMsg" BU_SG_REL_ BCM_HS SG_ 977 ThrPos 977;
BA_REL_ "GenSigSuprvResp" BU_SG_REL_ BCM_HS SG_ 977 ThrPos 1;
BA_REL_ "GenSigVBitResp" BU_SG_REL_ BCM_HS SG_ 977 ThrPos 1;
BA_REL_ "GenSigTimeoutTime" BU_SG_REL_ BCM_HS SG_ 201 RmVhStrtEngRng 50;
BA_REL_ "GenSigTimeoutMsg" BU_SG_REL_ BCM_HS SG_ 201 RmVhStrtEngRng 201;
BA_REL_ "GenSigSuprvResp" BU_SG_REL_ BCM_HS SG_ 201 RmVhStrtEngRng 2;
BA_REL_ "GenSigTimeoutTime" BU_SG_REL_ BCM_HS SG_ 201 AccActPos 50;
BA_REL_ "GenSigTimeoutMsg" BU_SG_REL_ BCM_HS SG_ 201 AccActPos 201;
BA_REL_ "GenSigSuprvResp" BU_SG_REL_ BCM_HS SG_ 201 AccActPos 1;
BA_REL_ "GenSigVBitResp" BU_SG_REL_ BCM_HS SG_ 201 AccActPos 1;
BA_REL_ "GenSigTimeoutTime" BU_SG_REL_ TCM_HS SG_ 201 AccActPos 250;
BA_REL_ "GenSigTimeoutMsg" BU_SG_REL_ TCM_HS SG_ 201 AccActPos 201;
BA_REL_ "GenSigSuprvResp" BU_SG_REL_ TCM_HS SG_ 201 AccActPos 1;
BA_REL_ "GenSigTimeoutTime" BU_SG_REL_ TCM_HS SG_ 201 CrsCntAtv 250;
BA_REL_ "GenSigTimeoutMsg" BU_SG_REL_ TCM_HS SG_ 201 CrsCntAtv 201;
BA_REL_ "GenSigSuprvResp" BU_SG_REL_ TCM_HS SG_ 201 CrsCntAtv 1;
BA_REL_ "GenSigTimeoutTime" BU_SG_REL_ BCM_HS SG_ 201 PTRunAbrt 50;
BA_REL_ "GenSigTimeoutMsg" BU_SG_REL_ BCM_HS SG_ 201 PTRunAbrt 201;
BA_REL_ "GenSigSuprvResp" BU_SG_REL_ BCM_HS SG_ 201 PTRunAbrt 2;
BA_REL_ "GenSigSuprvRespSubValue" BU_SG_REL_ BCM_HS SG_ 201 PTRunAbrt 1;
BA_REL_ "GenSigTimeoutTime" BU_SG_REL_ BCM_HS SG_ 201 EngSpd 250;
BA_REL_ "GenSigTimeoutMsg" BU_SG_REL_ BCM_HS SG_ 201 EngSpd 201;
BA_REL_ "GenSigSuprvResp" BU_SG_REL_ BCM_HS SG_ 201 EngSpd 1;
BA_REL_ "GenSigTimeoutTime" BU_SG_REL_ BCM_HS SG_ 201 EngRunAtv 50;
BA_REL_ "GenSigTimeoutMsg" BU_SG_REL_ BCM_HS SG_ 201 EngRunAtv 201;
BA_REL_ "GenSigSuprvResp" BU_SG_REL_ BCM_HS SG_ 201 EngRunAtv 2;
BA_REL_ "GenSigTimeoutTime" BU_SG_REL_ BCM_HS SG_ 501 CltStartSwAtv 250;
BA_REL_ "GenSigTimeoutMsg" BU_SG_REL_ BCM_HS SG_ 501 CltStartSwAtv 501;
BA_REL_ "GenSigSuprvResp" BU_SG_REL_ BCM_HS SG_ 501 CltStartSwAtv 1;
BA_REL_ "GenSigVBitResp" BU_SG_REL_ BCM_HS SG_ 501 CltStartSwAtv 1;
BA_REL_ "GenSigTimeoutTime" BU_SG_REL_ BCM_HS SG_ 501 TrnsEngdState 250;
BA_REL_ "GenSigTimeoutMsg" BU_SG_REL_ BCM_HS SG_ 501 TrnsEngdState 501;
BA_REL_ "GenSigSuprvResp" BU_SG_REL_ BCM_HS SG_ 501 TrnsEngdState 1;
BA_REL_ "GenSigVBitResp" BU_SG_REL_ BCM_HS SG_ 501 TrnsEngdState 1;
BA_REL_ "GenSigTimeoutTime" BU_SG_REL_ BCM_HS SG_ 501 TransTUDMdStat 250;
BA_REL_ "GenSigTimeoutMsg" BU_SG_REL_ BCM_HS SG_ 501 TransTUDMdStat 501;
BA_REL_ "GenSigSuprvResp" BU_SG_REL_ BCM_HS SG_ 501 TransTUDMdStat 1;
BA_REL_ "GenSigTimeoutTime" BU_SG_REL_ BCM_HS SG_ 501 TopTrvlCltchSwAct 250;
BA_REL_ "GenSigTimeoutMsg" BU_SG_REL_ BCM_HS SG_ 501 TopTrvlCltchSwAct 501;
BA_REL_ "GenSigSuprvResp" BU_SG_REL_ BCM_HS SG_ 501 TopTrvlCltchSwAct 1;
BA_REL_ "GenSigVBitResp" BU_SG_REL_ BCM_HS SG_ 501 TopTrvlCltchSwAct 1;
BA_REL_ "GenSigTimeoutTime" BU_SG_REL_ BCM_HS SG_ 501 TrnsShftLvrPos 250;
BA_REL_ "GenSigTimeoutMsg" BU_SG_REL_ BCM_HS SG_ 501 TrnsShftLvrPos 501;
BA_REL_ "GenSigSuprvResp" BU_SG_REL_ BCM_HS SG_ 501 TrnsShftLvrPos 1;
BA_REL_ "GenSigVBitResp" BU_SG_REL_ BCM_HS SG_ 501 TrnsShftLvrPos 1;
BA_REL_ "GenSigTimeoutTime" BU_SG_REL_ ECM_HS SG_ 501 TrnsTrqCnvCltCmndMd 62;
BA_REL_ "GenSigTimeoutMsg" BU_SG_REL_ ECM_HS SG_ 501 TrnsTrqCnvCltCmndMd 501;
BA_REL_ "GenSigSuprvResp" BU_SG_REL_ ECM_HS SG_ 501 TrnsTrqCnvCltCmndMd 1;
BA_REL_ "GenSigTimeoutTime" BU_SG_REL_ BCM_HS SG_ 501 AutoTransComndGear 250;
BA_REL_ "GenSigTimeoutMsg" BU_SG_REL_ BCM_HS SG_ 501 AutoTransComndGear 501;
BA_REL_ "GenSigSuprvResp" BU_SG_REL_ BCM_HS SG_ 501 AutoTransComndGear 1;
BA_REL_ "GenSigTimeoutTime" BU_SG_REL_ ECM_HS SG_ 501 AutoTransComndGear 62;
BA_REL_ "GenSigTimeoutMsg" BU_SG_REL_ ECM_HS SG_ 501 AutoTransComndGear 501;
BA_REL_ "GenSigSuprvResp" BU_SG_REL_ ECM_HS SG_ 501 AutoTransComndGear 1;
BA_REL_ "GenSigTimeoutTime" BU_SG_REL_ BCM_HS SG_ 501 TransEstGear 250;
BA_REL_ "GenSigTimeoutMsg" BU_SG_REL_ BCM_HS SG_ 501 TransEstGear 501;
BA_REL_ "GenSigSuprvResp" BU_SG_REL_ BCM_HS SG_ 501 TransEstGear 1;
BA_REL_ "GenSigVBitResp" BU_SG_REL_ BCM_HS SG_ 501 TransEstGear 1;
BA_REL_ "GenSigTimeoutTime" BU_SG_REL_ BCM_HS SG_ 1225 TrnOilTmp 1250;
BA_REL_ "GenSigTimeoutMsg" BU_SG_REL_ BCM_HS SG_ 1225 TrnOilTmp 1225;
BA_REL_ "GenSigSuprvResp" BU_SG_REL_ BCM_HS SG_ 1225 TrnOilTmp 1;
BA_REL_ "GenSigVBitResp" BU_SG_REL_ BCM_HS SG_ 1225 TrnOilTmp 1;
BA_REL_ "GenSigTimeoutTime" BU_SG_REL_ ECM_HS SG_ 409 TTRLT_TorqReqVal 31;
BA_REL_ "GenSigTimeoutMsg" BU_SG_REL_ ECM_HS SG_ 409 TTRLT_TorqReqVal 409;
BA_REL_ "GenSigSuprvResp" BU_SG_REL_ ECM_HS SG_ 409 TTRLT_TorqReqVal 1;
BA_REL_ "GenSigTimeoutTime" BU_SG_REL_ ECM_HS SG_ 409 TTRLT_TqRdnRlznSgg 31;
BA_REL_ "GenSigTimeoutMsg" BU_SG_REL_ ECM_HS SG_ 409 TTRLT_TqRdnRlznSgg 409;
BA_REL_ "GenSigSuprvResp" BU_SG_REL_ ECM_HS SG_ 409 TTRLT_TqRdnRlznSgg 1;
BA_REL_ "GenSigTimeoutTime" BU_SG_REL_ ECM_HS SG_ 409 TTRLT_TorqInvntnTyp 31;
BA_REL_ "GenSigTimeoutMsg" BU_SG_REL_ ECM_HS SG_ 409 TTRLT_TorqInvntnTyp 409;
BA_REL_ "GenSigSuprvResp" BU_SG_REL_ ECM_HS SG_ 409 TTRLT_TorqInvntnTyp 1;
BA_REL_ "GenSigTimeoutTime" BU_SG_REL_ ECM_HS SG_ 409 TTRST_TorqReqVal 31;
BA_REL_ "GenSigTimeoutMsg" BU_SG_REL_ ECM_HS SG_ 409 TTRST_TorqReqVal 409;
BA_REL_ "GenSigSuprvResp" BU_SG_REL_ ECM_HS SG_ 409 TTRST_TorqReqVal 1;
BA_REL_ "GenSigTimeoutTime" BU_SG_REL_ ECM_HS SG_ 409 TTRST_TorqInvntnTyp 31;
BA_REL_ "GenSigTimeoutMsg" BU_SG_REL_ ECM_HS SG_ 409 TTRST_TorqInvntnTyp 409;
BA_REL_ "GenSigSuprvResp" BU_SG_REL_ ECM_HS SG_ 409 TTRST_TorqInvntnTyp 1;
BA_REL_ "GenSigTimeoutTime" BU_SG_REL_ ECM_HS SG_ 413 TrnsRtoCntlSysFlt 62;
BA_REL_ "GenSigTimeoutMsg" BU_SG_REL_ ECM_HS SG_ 413 TrnsRtoCntlSysFlt 413;
BA_REL_ "GenSigSuprvResp" BU_SG_REL_ ECM_HS SG_ 413 TrnsRtoCntlSysFlt 1;
BA_REL_ "GenSigTimeoutTime" BU_SG_REL_ ECM_HS SG_ 413 TESR_EngSpdCntlRsp 62;
BA_REL_ "GenSigTimeoutMsg" BU_SG_REL_ ECM_HS SG_ 413 TESR_EngSpdCntlRsp 413;
BA_REL_ "GenSigSuprvResp" BU_SG_REL_ ECM_HS SG_ 413 TESR_EngSpdCntlRsp 1;
BA_REL_ "GenSigTimeoutTime" BU_SG_REL_ ECM_HS SG_ 413 TESR_EngSpdRqVal 62;
BA_REL_ "GenSigTimeoutMsg" BU_SG_REL_ ECM_HS SG_ 413 TESR_EngSpdRqVal 413;
BA_REL_ "GenSigSuprvResp" BU_SG_REL_ ECM_HS SG_ 413 TESR_EngSpdRqVal 1;
BA_REL_ "GenSigTimeoutTime" BU_SG_REL_ ECM_HS SG_ 413 TESR_EngSpdIntTyp 62;
BA_REL_ "GenSigTimeoutMsg" BU_SG_REL_ ECM_HS SG_ 413 TESR_EngSpdIntTyp 413;
BA_REL_ "GenSigSuprvResp" BU_SG_REL_ ECM_HS SG_ 413 TESR_EngSpdIntTyp 1;
BA_REL_ "GenSigTimeoutTime" BU_SG_REL_ ECM_HS SG_ 413 TrnsGrgShftAct 62;
BA_REL_ "GenSigTimeoutMsg" BU_SG_REL_ ECM_HS SG_ 413 TrnsGrgShftAct 413;
BA_REL_ "GenSigSuprvResp" BU_SG_REL_ ECM_HS SG_ 413 TrnsGrgShftAct 1;
BA_REL_ "GenSigTimeoutTime" BU_SG_REL_ BCM_HS SG_ 197 WRSLNDWhlDisTpRC 250;
BA_REL_ "GenSigTimeoutMsg" BU_SG_REL_ BCM_HS SG_ 197 WRSLNDWhlDisTpRC 197;
BA_REL_ "GenSigSuprvResp" BU_SG_REL_ BCM_HS SG_ 197 WRSLNDWhlDisTpRC 1;
BA_REL_ "GenSigTimeoutTime" BU_SG_REL_ BCM_HS SG_ 197 WRSLNDWhlRotStRst 250;
BA_REL_ "GenSigTimeoutMsg" BU_SG_REL_ BCM_HS SG_ 197 WRSLNDWhlRotStRst 197;
BA_REL_ "GenSigSuprvResp" BU_SG_REL_ BCM_HS SG_ 197 WRSLNDWhlRotStRst 1;
BA_REL_ "GenSigTimeoutTime" BU_SG_REL_ BCM_HS SG_ 197 WRSLNDWhlDistVal 250;
BA_REL_ "GenSigTimeoutMsg" BU_SG_REL_ BCM_HS SG_ 197 WRSLNDWhlDistVal 197;
BA_REL_ "GenSigSuprvResp" BU_SG_REL_ BCM_HS SG_ 197 WRSLNDWhlDistVal 1;
BA_REL_ "GenSigTimeoutTime" BU_SG_REL_ BCM_HS SG_ 197 WRSLNDWhlDistTstm 250;
BA_REL_ "GenSigTimeoutMsg" BU_SG_REL_ BCM_HS SG_ 197 WRSLNDWhlDistTstm 197;
BA_REL_ "GenSigSuprvResp" BU_SG_REL_ BCM_HS SG_ 197 WRSLNDWhlDistTstm 1;
BA_REL_ "GenSigTimeoutTime" BU_SG_REL_ BCM_HS SG_ 197 WRSLNDWhlDistPCntr 250;
BA_REL_ "GenSigTimeoutMsg" BU_SG_REL_ BCM_HS SG_ 197 WRSLNDWhlDistPCntr 197;
BA_REL_ "GenSigSuprvResp" BU_SG_REL_ BCM_HS SG_ 197 WRSLNDWhlDistPCntr 1;
BA_REL_ "GenSigTimeoutTime" BU_SG_REL_ BCM_HS SG_ 197 WRSLNDSeqNum 250;
BA_REL_ "GenSigTimeoutMsg" BU_SG_REL_ BCM_HS SG_ 197 WRSLNDSeqNum 197;
BA_REL_ "GenSigSuprvResp" BU_SG_REL_ BCM_HS SG_ 197 WRSLNDSeqNum 1;
BA_REL_ "GenSigTimeoutTime" BU_SG_REL_ BCM_HS SG_ 197 WRSRNDWhlDisTpRC 250;
BA_REL_ "GenSigTimeoutMsg" BU_SG_REL_ BCM_HS SG_ 197 WRSRNDWhlDisTpRC 197;
BA_REL_ "GenSigSuprvResp" BU_SG_REL_ BCM_HS SG_ 197 WRSRNDWhlDisTpRC 1;
BA_REL_ "GenSigTimeoutTime" BU_SG_REL_ BCM_HS SG_ 197 WRSRNDWhlRotStRst 250;
BA_REL_ "GenSigTimeoutMsg" BU_SG_REL_ BCM_HS SG_ 197 WRSRNDWhlRotStRst 197;
BA_REL_ "GenSigSuprvResp" BU_SG_REL_ BCM_HS SG_ 197 WRSRNDWhlRotStRst 1;
BA_REL_ "GenSigTimeoutTime" BU_SG_REL_ BCM_HS SG_ 197 WRSRNDWhlDistVal 250;
BA_REL_ "GenSigTimeoutMsg" BU_SG_REL_ BCM_HS SG_ 197 WRSRNDWhlDistVal 197;
BA_REL_ "GenSigSuprvResp" BU_SG_REL_ BCM_HS SG_ 197 WRSRNDWhlDistVal 1;
BA_REL_ "GenSigTimeoutTime" BU_SG_REL_ BCM_HS SG_ 197 WRSRNDWhlDistTstm 250;
BA_REL_ "GenSigTimeoutMsg" BU_SG_REL_ BCM_HS SG_ 197 WRSRNDWhlDistTstm 197;
BA_REL_ "GenSigSuprvResp" BU_SG_REL_ BCM_HS SG_ 197 WRSRNDWhlDistTstm 1;
BA_REL_ "GenSigTimeoutTime" BU_SG_REL_ BCM_HS SG_ 197 WRSRNDWhlDistPCntr 250;
BA_REL_ "GenSigTimeoutMsg" BU_SG_REL_ BCM_HS SG_ 197 WRSRNDWhlDistPCntr 197;
BA_REL_ "GenSigSuprvResp" BU_SG_REL_ BCM_HS SG_ 197 WRSRNDWhlDistPCntr 1;
BA_REL_ "GenSigTimeoutTime" BU_SG_REL_ BCM_HS SG_ 197 WRSRNDSeqNum 250;
BA_REL_ "GenSigTimeoutMsg" BU_SG_REL_ BCM_HS SG_ 197 WRSRNDSeqNum 197;
BA_REL_ "GenSigSuprvResp" BU_SG_REL_ BCM_HS SG_ 197 WRSRNDSeqNum 1;
VAL_ 546 ChmNum 7 "7" 6 "6" 5 "5" 4 "4" 3 "3" 2 "2" 1 "1" 0 "0" ;
VAL_ 546 ChmReq 1 "True" 0 "False" ;
VAL_ 494 TPMTrLrnMdCmplt 2 "Unsuccess Complete" 1 "Success Complete" 0 "False" ;
VAL_ 773 RHRTirePrsStat 4 "High Pressure(soft warning)" 3 "Unknown" 2 "Flat Tire (Hard warning)" 1 "Low Pressure(Soft warning)" 0 "Fail Not Present" ;
VAL_ 773 LHRTirePrsStat 4 "High Pressure(soft warning)" 3 "Unknown" 2 "Flat Tire (Hard warning)" 1 "Low Pressure(Soft warning)" 0 "Fail Not Present" ;
VAL_ 773 RHFTirePrsStat 4 "High Pressure(soft warning)" 3 "Unknown" 2 "Flat Tire (Hard warning)" 1 "Low Pressure(Soft warning)" 0 "Fail Not Present" ;
VAL_ 773 LHFTirePrsStat 4 "High Pressure(soft warning)" 3 "Unknown" 2 "Flat Tire (Hard warning)" 1 "Low Pressure(Soft warning)" 0 "Fail Not Present" ;
VAL_ 773 TirePrsSysFailSts 1 "Fail Present" 0 "Fail Not Present" ;
VAL_ 773 IDTireTemp 3 "RR" 2 "LR" 1 "RF" 0 "LF" ;
VAL_ 1284 IDStudyACK 1 "True" 0 "False" ;
VAL_ 1283 IDStudyReq 1 "True" 0 "False" ;
VAL_ 519 DrvSelOvSpdWarnActConf 1 "true" 0 "false" ;
VAL_ 519 OvSpdChmReq 1 "true" 0 "false" ;
VAL_ 533 DrvSelOvSpdEnbl 1 "true" 0 "false" ;
VAL_ 533 OvSpdSta 1 "True" 0 "False" ;
VAL_ 328 StrngAsstRdcdIO 1 "True" 0 "False" ;
VAL_ 328 PwrStrIO 1 "true" 0 "false" ;
VAL_ 528 ChmVolSt 1 "Loud" 0 "Normal" ;
VAL_ 528 ChmAct 1 "true" 0 "false" ;
VAL_ 517 SC_SndTne 14 "No Chime with Radio Source Muted" 13 "Gong (2000 Hz) Radio Source Muted" 12 "Gong (750 Hz) Radio Source Muted" 11 "Beep (2000 Hz) Radio Source Muted" 10 "Beep (750 Hz) Radio Source Muted" 9 "High Frequency Broadband" 8 "Harp" 7 "Gong 2 (2000 Hz)" 6 "Gong 1 (750 Hz)" 5 "Beep 2 (2000 Hz)" 4 "Beep 1 (750 Hz)" 3 "Click-Clack" 2 "Click" 1 "Clack" 0 "Clock" ;
VAL_ 517 SndLocRtRr 1 "true" 0 "false" ;
VAL_ 517 SndLocLftRr 1 "true" 0 "false" ;
VAL_ 517 SndLocPasFr 1 "true" 0 "false" ;
VAL_ 517 SndLocDrFr 1 "true" 0 "false" ;
VAL_ 401 EngTrqTrnRqTmpFld 1 "true" 0 "false" ;
VAL_ 401 EngTrqTrnRqLmtd 1 "true" 0 "false" ;
VAL_ 401 TrnsEngSpdReqFld 1 "true" 0 "false" ;
VAL_ 401 EngTrqTnsRqFld 1 "true" 0 "false" ;
VAL_ 401 EngTrqRdnFld 1 "true" 0 "false" ;
VAL_ 401 EngNTrnsRegStdyStTqV 1 "Invalid" 0 "Valid" ;
VAL_ 401 EngAirflwStdyStTorqV 1 "Invalid" 0 "Valid" ;
VAL_ 401 AccKdwnAtv 1 "true" 0 "false" ;
VAL_ 401 AccPosV 1 "Invalid" 0 "Valid" ;
VAL_ 401 EngActStdyStTorqV 1 "Invalid" 0 "Valid" ;
VAL_ 1265 EngOffTmPTV 1 "Invalid" 0 "Valid" ;
VAL_ 1265 EngOffTmPTM 1 "Use Data" 0 "Don't Use Data" ;
VAL_ 417 EngRunng 1 "true" 0 "false" ;
VAL_ 417 EngCrsCntrlMode 5 "Tap" 4 "Coast" 3 "Accel" 2 "Resume" 1 "Engaged" 0 "Inactive" ;
VAL_ 417 EngPstOxgSnsDgAstRq 1 "true" 0 "false" ;
VAL_ 417 CrsCtrlCnstSpdAct 1 "true" 0 "false" ;
VAL_ 417 WrmUpShftPtrnRq 1 "Active" 0 "Inactive" ;
VAL_ 417 EngCntrlRunCrnkTrmSt 1 "Active" 0 "Inactive" ;
VAL_ 417 EngAlwCltAdp 1 "true" 0 "false" ;
VAL_ 417 AccPdlPosPcntFullRngV 1 "Invalid" 0 "Valid" ;
VAL_ 417 DslPrtFltrIdlRgtnMdReq 1 "true" 0 "false" ;
VAL_ 417 DslPartFltrClngAlgActM 1 "Use Data" 0 "Don't Use Data" ;
VAL_ 417 DslPartFltrClngAlgAct 1 "true" 0 "false" ;
VAL_ 417 ACCmCltEngd 1 "true" 0 "false" ;
VAL_ 417 ParkNeutralSwStatV 1 "Invalid" 0 "Valid" ;
VAL_ 417 ParkNeutralSwStat 1 "Not Park/Neutral" 0 "Park/Neutral" ;
VAL_ 417 EngColdHiIdleActive 1 "true" 0 "false" ;
VAL_ 417 EngCyDactTqSmtAct 1 "true" 0 "false" ;
VAL_ 417 EngBrkStat 2 "Active Absorbing Torque" 1 "Active Not Absorbing Torque" 0 "Inactive" ;
VAL_ 417 TracCntlSysPwrtrnInhbt 1 "true" 0 "false" ;
VAL_ 417 EngMtlProtAtv 1 "true" 0 "false" ;
VAL_ 417 EngDgTrqCnvClUnlkRqd 1 "true" 0 "false" ;
VAL_ 417 EngCyldrDeactReqd 1 "true" 0 "false" ;
VAL_ 417 ETGRReqdGear 8 "Eighth Gear" 7 "Seventh Gear" 6 "Sixth Gear" 5 "Fifth Gear" 4 "Fourth Gear" 3 "Third Gear" 2 "Second Gear" 1 "First Gear" 0 "No Action" ;
VAL_ 417 ETGRReqType 0 "No Action" 3 "Hold Gear" 2 "Min Gear Request" 1 "Max Gear Request" ;
VAL_ 1233 EngShtdwnAct 1 "true" 0 "false" ;
VAL_ 1233 EngShtdwnPndgIO 1 "true" 0 "false" ;
VAL_ 1233 FuelFltChgNwIO 1 "true" 0 "false" ;
VAL_ 1233 PTExPrtclFltrWrn2IO 1 "true" 0 "false" ;
VAL_ 1233 PTHiElecLdReqd 1 "true" 0 "false" ;
VAL_ 1233 PTExPrtclFltrWrnIO 1 "true" 0 "false" ;
VAL_ 1233 AirCndOffIO 1 "true" 0 "false" ;
VAL_ 1233 DslGlwPlgIO 1 "true" 0 "false" ;
VAL_ 1233 StgDisIO 1 "true" 0 "false" ;
VAL_ 1233 RdcdPwrIO 1 "true" 0 "false" ;
VAL_ 1233 FlLvlPctV 1 "Invalid" 0 "Valid" ;
VAL_ 1233 EngWtrInFlIO 1 "true" 0 "false" ;
VAL_ 1233 EngOilTmpV 1 "Invalid" 0 "Valid" ;
VAL_ 1233 EngOilPrsV 1 "Invalid" 0 "Valid" ;
VAL_ 1233 EngOilPrsLwIO 1 "true" 0 "false" ;
VAL_ 1233 EngOilLvlLwIO 1 "true" 0 "false" ;
VAL_ 1233 EngOilChngIO 1 "true" 0 "false" ;
VAL_ 1233 EngHt_StpEngIO 1 "true" 0 "false" ;
VAL_ 1233 EngHotFuelEnrchmntIO 1 "true" 0 "false" ;
VAL_ 1233 CkFlFilrCapIO 1 "true" 0 "false" ;
VAL_ 1217 LegPstDTCClrDrvCyCm 1 "true" 0 "false" ;
VAL_ 1217 LegDiagColdStCndMet 1 "true" 0 "false" ;
VAL_ 1217 LegDiagColdStCndFltPr 1 "true" 0 "false" ;
VAL_ 1217 EngEconMdCmnd 1 "true" 0 "false" ;
VAL_ 1217 EngOilHotIO 1 "true" 0 "false" ;
VAL_ 1217 DslExhFldWrngIndRq 5 "Warning Level 5" 4 "Warning Level 4" 3 "Warning Level 3" 2 "Warning Level 2" 1 "Warning Level 1" 0 "No Indication" ;
VAL_ 1217 DslExhFldRmngDstV 1 "Invalid" 0 "Valid" ;
VAL_ 1217 OAT_PT_EstV 1 "Invalid" 0 "Valid" ;
VAL_ 1217 LegDiagStndCndMet 1 "true" 0 "false" ;
VAL_ 1217 LegDiagStndCndFltPr 1 "true" 0 "false" ;
VAL_ 1217 OAT_PT_EstM 1 "Use Data" 0 "Don't Use Data" ;
VAL_ 1217 EngWrmUpAch 1 "true" 0 "false" ;
VAL_ 1217 EngIntAirTmpV 1 "Invalid" 0 "Valid" ;
VAL_ 1217 EngCltTmpV 1 "Invalid" 0 "Valid" ;
VAL_ 1217 BarPrsAbsV 1 "Invalid" 0 "Valid" ;
VAL_ 1017 ACRfHiSdFldPrsV 1 "Invalid" 0 "Valid" ;
VAL_ 1017 GenStptDtCycPtOvrAct 1 "true" 0 "false" ;
VAL_ 1017 VehTopSpdLmtMdAct 1 "true" 0 "false" ;
VAL_ 1017 PT_TopSpdLmtRdcd 1 "true" 0 "false" ;
VAL_ 1017 GenFldDutCycV 1 "Invalid" 0 "Valid" ;
VAL_ 1017 GenFld 1 "true" 0 "false" ;
VAL_ 1017 FlInjRlCtRstOcc 1 "true" 0 "false" ;
VAL_ 1017 EngSpdLmtnMdAct 1 "true" 0 "false" ;
VAL_ 977 FuelFltLifRstPerf 1 "true" 0 "false" ;
VAL_ 977 CrsCntlDrSelSpdAct 1 "true" 0 "false" ;
VAL_ 977 ACCompCmnd 1 "On" 0 "Off" ;
VAL_ 977 EngBstPrsIndV 1 "Invalid" 0 "Valid" ;
VAL_ 977 EngOilLifRstPerf 1 "true" 0 "false" ;
VAL_ 977 ThrtlPrgrsnStat 3 "ECM Selected Progression" 2 "Map C" 1 "Map B" 0 "Map A" ;
VAL_ 977 ThrPosV 1 "Invalid" 0 "Valid" ;
VAL_ 977 EngOilStrvtnIO 1 "true" 0 "false" ;
VAL_ 977 EngNEmsnsRelMalfAct 1 "true" 0 "false" ;
VAL_ 977 EngEmsRelMalfIndReq 4 "Flashing 0.5 Hertz Indication" 3 "Flashing 2 Hertz Indication" 2 "Flashing 1 Hertz Indication" 1 "No Indication" 0 "Continuous Indication" ;
VAL_ 977 EngEmsMlfAtv 1 "true" 0 "false" ;
VAL_ 977 EngCstFlCutAct 1 "true" 0 "false" ;
VAL_ 977 AppBrkBfrCrsIO 1 "true" 0 "false" ;
VAL_ 201 EngAirIntBstPrV 1 "Invalid" 0 "Valid" ;
VAL_ 201 SpdLmtrSpdWrngEnbld 1 "true" 0 "false" ;
VAL_ 201 SpdLmtrSpdWrngAct 1 "true" 0 "false" ;
VAL_ 201 EngCylDactEvntPndg 1 "true" 0 "false" ;
VAL_ 201 EngCylDeactMd 3 "Reactivation In Progress" 2 "Half of Total Cylinders Active" 1 "Deactivation In Progress" 0 "All Cylinders Active" ;
VAL_ 201 RmVhStrtEngRng 1 "true" 0 "false" ;
VAL_ 201 PFEngSpdCmndSpcd 1 "true" 0 "false" ;
VAL_ 201 PltfrmEngSpdCmdInhtRq 1 "Inhibit Platform Eng. Speed Control" 0 "Allow Platform Engine Speed Control" ;
VAL_ 201 PT_BrkPedDscrtInpStatV 1 "Invalid" 0 "Valid" ;
VAL_ 201 PT_BrkPedDscrtInpStat 1 "Brake Applied" 0 "Brake Not Applied" ;
VAL_ 201 CrsCntEnbld 1 "true" 0 "false" ;
VAL_ 201 CrsCntAtv 1 "true" 0 "false" ;
VAL_ 201 DrvThrottlOvrrdDet 1 "true" 0 "false" ;
VAL_ 201 PT_CrnkAct 1 "true" 0 "false" ;
VAL_ 201 PTRunAbrt 1 "true" 0 "false" ;
VAL_ 201 PTO_PT_RunAbrtd 1 "true" 0 "false" ;
VAL_ 201 PTCrnkAbrted 1 "true" 0 "false" ;
VAL_ 201 EngSpdStat 3 "Invalid" 1 "Degraded Operation" 0 "Normal Operation" ;
VAL_ 201 EngRunAtv 1 "true" 0 "false" ;
VAL_ 201 EngIdlAtv 1 "true" 0 "false" ;
VAL_ 201 AccActPosV 1 "Invalid" 0 "Valid" ;
VAL_ 501 EngRecDwnshftIO 1 "true" 0 "false" ;
VAL_ 501 TrnsPattSelEcnMdOCm 1 "true" 0 "false" ;
VAL_ 501 TransShftDlyd 1 "true" 0 "false" ;
VAL_ 501 CltStartSwAtvV 1 "Invalid" 0 "Valid" ;
VAL_ 501 CltStartSwAtv 1 "true" 0 "false" ;
VAL_ 501 CltchPdlActPosV 1 "Invalid" 0 "Valid" ;
VAL_ 501 TrnsEngdStateV 1 "Invalid" 0 "Valid" ;
VAL_ 501 TrnsEngdState 3 "Operating State Not Reached" 2 "Transmission Engaged in Reverse" 1 "Transmission Engaged in Forward" 0 "Transmission Not Engaged" ;
VAL_ 501 TransTUDMdStat 2 "Electronic Range Select Active" 1 "Driver Shift Control Active" 0 "No Activation" ;
VAL_ 501 TrnCrpMdAtv 1 "true" 0 "false" ;
VAL_ 501 TrnsShftLvrLckRqd 1 "true" 0 "false" ;
VAL_ 501 TrnsSkpShftIO 1 "true" 0 "false" ;
VAL_ 501 TrnsSftMdStat 3 "Automatic Grade Braking Mode" 2 "Lift-Foot Cornering Mode" 1 "Performance Mode" 0 "No Override Mode" ;
VAL_ 501 TrnsRngInhbtStat 4 "Diagnostic Inhibit Active" 3 "Driveline Not Engaged" 2 "Transmission Range Re-Selection Req" 1 "Transmission Inhibit Active" 0 "No Range Inhibit Active" ;
VAL_ 501 TopTrvlCltchSwActV 1 "Invalid" 0 "Valid" ;
VAL_ 501 TopTrvlCltchSwAct 1 "true" 0 "false" ;
VAL_ 501 OvrdrvDsblReqGrntd 1 "true" 0 "false" ;
VAL_ 501 EngRecmndUpshftIO 1 "true" 0 "false" ;
VAL_ 501 DrvtShftCntrlTrgtGear 8 "Eighth Gear" 7 "Seventh Gear" 6 "Sixth Gear" 5 "Fifth Gear" 4 "Fourth Gear" 3 "Third Gear" 2 "Second Gear" 1 "First Gear" 0 "Not Supported" ;
VAL_ 501 DrShftCntrlReqDndIO 1 "true" 0 "false" ;
VAL_ 501 TrnShftPtrnActStat 6 "PT Protection Pattern Active" 5 "PT Non-Protection Pattern Active" 4 "Shift Pattern 4 Active" 3 "Shift Pattern 3 Active" 2 "Shift Pattern 2 Active" 1 "Shift Pattern 1 Active" 0 "Default Shift Pattern Active" ;
VAL_ 501 TrnsFldPrsPrsnt 1 "true" 0 "false" ;
VAL_ 501 TrnsShftLvrPos 15 "Lever Position Unknown" 9 "Forward Range F" 8 "Forward Range E" 7 "Forward Range D" 6 "Forward Range C" 5 "Forward Range B" 4 "Forward Range A" 3 "Neutral Range" 2 "Reverse Range" 1 "Park Range" 0 "Between Ranges" ;
VAL_ 501 TrnsShftLvrPosV 1 "Invalid" 0 "Valid" ;
VAL_ 501 TrnsTrqCnvCltCmndMd 7 "Not Supported" 3 "Locked" 2 "Controlled Slip" 1 "Transitioning" 0 "Unlocked" ;
VAL_ 501 AutoTransComndGear 15 "Park Gear" 14 "Reverse Gear" 13 "Neutral Gear" 12 "CVT Forward Gear" 11 "EVT Mode 2" 10 "EVT Mode 1" 8 "Eighth Gear" 7 "Seventh Gear" 6 "Sixth Gear" 5 "Fifth Gear" 4 "Fourth Gear" 3 "Third Gear" 2 "Second Gear" 1 "First Gear" 0 "Not Supported" ;
VAL_ 501 AutoTransGrSftDirect 2 "Downshift in Progress" 1 "Upshift in Progress" 0 "No Shift in Progress" ;
VAL_ 501 TransEstGear 15 "Park Gear" 14 "Reverse Gear" 13 "Neutral Gear" 12 "CVT Forward Gear" 11 "EVT Mode 2" 10 "EVT Mode 1" 8 "Eighth Gear" 7 "Seventh Gear" 6 "Sixth Gear" 5 "Fifth Gear" 4 "Fourth Gear" 3 "Third Gear" 2 "Second Gear" 1 "First Gear" 0 "Not Supported" ;
VAL_ 501 TransEstGearV 1 "Invalid" 0 "Valid" ;
VAL_ 1225 TrnsThrmlMngmntStat 2 "Driver Intervention Requested" 1 "Countermeasures Active" 0 "Normal" ;
VAL_ 1225 TrnsNEmsRltMalfActv 1 "true" 0 "false" ;
VAL_ 1225 TransOilTempSensPres 1 "true" 0 "false" ;
VAL_ 1225 TrnEmsMlfAtv 1 "true" 0 "false" ;
VAL_ 1225 TrnOilTmpV 1 "Invalid" 0 "Valid" ;
VAL_ 1225 TERDTC_SysDes 15 "U3-Network Codes Reserved" 14 "U2-Network Codes Reserved" 13 "U1-Network Codes MFG Controlled" 12 "U0-Network Codes SAE Controlled" 11 "B3-Body Codes Reserved" 10 "B2-Body Codes Reserved" 9 "B1-Body Codes MFG Controlled" 8 "B0-Body Codes SAE Controlled" 7 "C3-Chassis Codes Reserved" 6 "C2-Chassis Codes Reserved" 5 "C1-Chassis Codes MFG Controlled" 4 "C0-Chassis Codes SAE Controlled" 3 "P3-Powertrain Codes Reserved" 2 "P2-Powertrain Codes Reserved" 1 "P1-Powertrain Codes MFG Controlled" 0 "P0-Powertrain Codes SAE Controlled" ;
VAL_ 409 TDslPrtFltrIdlRgtnMdAtv 1 "true" 0 "false" ;
VAL_ 409 TTRLT_TqRdnRlznSgg 3 "Stability Optimized 2" 2 "Stability Optimized 1" 1 "Transient Optimized" 0 "No Suggestion" ;
VAL_ 409 TTRLT_TorqInvntnTyp 2 "Minimum Limit" 1 "Maximum Limit" 0 "No Intervention" ;
VAL_ 409 TTRST_TorqInvntnTyp 1 "Maximum Limit" 0 "No Intervention" ;
VAL_ 413 TrnsCyDactTransStat 2 "Ready for Half of TotalCylinders" 1 "Ready for All Cylinders" 0 "Not Ready" ;
VAL_ 413 EngBrkDsblReqd 1 "true" 0 "false" ;
VAL_ 413 TransNtrlCntrlMdStat 3 "Exiting Neutral Control" 2 "Neutral Control Active" 1 "Entering Neutral Control" 0 "Neutral Control Not Active" ;
VAL_ 413 TrnsRtoCntlSysFlt 1 "true" 0 "false" ;
VAL_ 413 TrnTrbAngVlV 1 "Invalid" 0 "Valid" ;
VAL_ 413 TrnGrRatV 1 "Invalid" 0 "Valid" ;
VAL_ 413 TrnPrfAlgShfAtv 1 "true" 0 "false" ;
VAL_ 413 TESR_EngSpdCntlRsp 3 "Stability Optimized Condition 2" 2 "Stability Optimized Condition 1" 1 "Transient Optimized" 0 "No Suggestion" ;
VAL_ 413 TESR_EngSpdIntTyp 2 "Engine Speed Min Limit" 1 "Engine Speed Max Limit" 0 "No Intervention" ;
VAL_ 413 TrnsGrgShftAct 1 "true" 0 "false" ;
VAL_ 197 WRSLNDWhlRotStRst 1 "true" 0 "false" ;
VAL_ 197 WRSLNDWhlDistVal 1 "Invalid" 0 "Valid" ;
VAL_ 197 WRSRNDWhlRotStRst 1 "true" 0 "false" ;
VAL_ 197 WRSRNDWhlDistVal 1 "Invalid" 0 "Valid" ;
SIG_GROUP_ 192 WhlRotatStatChkData 1 : WRSCD_RtNDrvnSNm WRSCD_RtDrvnSqNm WRSCD_RNDrvnCkVa WRSCD_RDrvnCkVa WRSCD_LftNDrvnSNm WRSCD_LftDrvnSqNm WRSCD_LfNDrvnCkVa WRSCD_LfDrvnCkVa;
SIG_GROUP_ 517 SndChrs 1 : SC_SndDutCyc SC_NmofRp SC_SndCdnPrd SC_SndTne;
SIG_GROUP_ 517 SndLoc 1 : SndLocRtRr SndLocLftRr SndLocPasFr SndLocDrFr;
SIG_GROUP_ 417 EngTransGearReq 1 : ETGRReqdGear ETGRReqType;
SIG_GROUP_ 1225 TransEmsnsRelDTC 1 : TERDTC_SysDes TERDTC_CdNum;
SIG_GROUP_ 409 TransTorqReqLngTrm 1 : TTRLT_TorqReqVal TTRLT_TqRdnRlznSgg TTRLT_TorqInvntnTyp;
SIG_GROUP_ 409 TransTorqReqShrtTrm 1 : TTRST_TorqReqVal TTRST_TorqInvntnTyp;
SIG_GROUP_ 413 TrnsEngSpdRq 1 : TESR_EngSpdCntlRsp TESR_EngSpdRqVal TESR_EngSpdIntTyp;
SIG_GROUP_ 197 WhlRotStatLftNDrvn 1 : WRSLNDWhlDisTpRC WRSLNDWhlRotStRst WRSLNDWhlDistVal WRSLNDWhlDistTstm WRSLNDWhlDistPCntr WRSLNDSeqNum;
SIG_GROUP_ 197 WhlRotStatRghtNDrvn 1 : WRSRNDWhlDisTpRC WRSRNDWhlRotStRst WRSRNDWhlDistVal WRSRNDWhlDistTstm WRSRNDWhlDistPCntr WRSRNDSeqNum;
